VERSION "HNNBNNNYNNNNNNNNNNNNNNNNNNNNNNNNNNNNNNNNNN/4/%%%/4/'%**4NNN///"

NS_ :

BS_:

BU_: Frontradar Frontsensorik

BO_ 780 ACC_02: 8 Frontradar
 SG_ ACC_02_CRC : 0|8@1+ (1,0) [0|255] "" Vector__XXX
 SG_ ACC_02_BZ : 8|4@1+ (1,0) [0|15] "" Vector__XXX
 SG_ ACC_Wunschgeschw_02 : 12|10@1+ (0.32,0) [0|327.04] "Unit_KiloMeterPerHour" Vector__XXX
 SG_ ACC_Status_Prim_Anz : 22|2@1+ (1,0) [0|3] "" Vector__XXX
 SG_ ACC_Abstandsindex : 24|10@1+ (1,0) [1|1021] "" Vector__XXX
 SG_ ACC_Akustik_02 : 34|2@1+ (1,0) [0|3] "" Vector__XXX
 SG_ ACC_Warnung_Verkehrszeichen_1 : 36|1@1+ (1,0) [0|1] "" Vector__XXX
 SG_ ACC_Gesetzte_Zeitluecke : 37|3@1+ (1,0) [0|7] "" Vector__XXX
 SG_ ACC_Optischer_Fahrerhinweis : 40|1@1+ (1,0) [0|1] "" Vector__XXX
 SG_ ACC_Typ_Tachokranz : 41|1@1+ (1,0) [0|1] "" Vector__XXX
 SG_ ACC_Anzeige_Zeitluecke : 42|1@1+ (1,0) [0|1] "" Vector__XXX
 SG_ ACC_Tachokranz : 43|1@1+ (1,0) [0|1] "" Vector__XXX
 SG_ ACC_Display_Prio : 44|2@1+ (1,0) [0|3] "" Vector__XXX
 SG_ ACC_Relevantes_Objekt : 46|2@1+ (1,0) [0|3] "" Vector__XXX
 SG_ ACC_Texte_Primaeranz : 48|7@1+ (1,0) [0|127] "" Vector__XXX
 SG_ ACC_Wunschgeschw_erreicht : 55|1@1+ (1,0) [0|1] "" Vector__XXX
 SG_ ACC_Typ_Tachokranz_unten : 60|1@1+ (1,0) [0|1] "" Vector__XXX
 SG_ ACC_Status_Anzeige : 61|3@1+ (1,0) [0|7] "" Vector__XXX

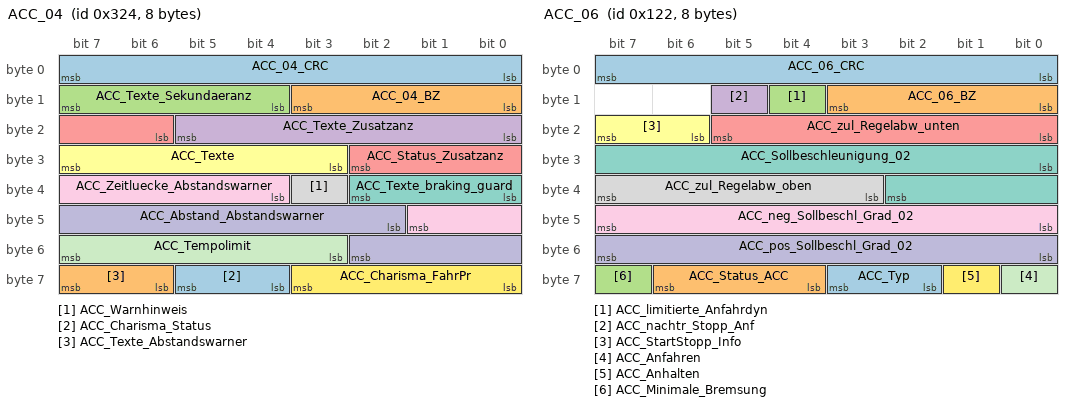
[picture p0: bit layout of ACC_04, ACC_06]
BO_ 804 ACC_04: 8 Frontradar
 SG_ ACC_04_CRC : 0|8@1+ (1,0) [0|255] "" Vector__XXX
 SG_ ACC_04_BZ : 8|4@1+ (1,0) [0|15] "" Vector__XXX
 SG_ ACC_Texte_Sekundaeranz : 12|4@1+ (1,0) [0|15] "" Vector__XXX
 SG_ ACC_Texte_Zusatzanz : 16|6@1+ (1,0) [0|63] "" Vector__XXX
 SG_ ACC_Status_Zusatzanz : 22|5@1+ (1,0) [0|31] "" Vector__XXX
 SG_ ACC_Texte : 27|5@1+ (1,0) [0|31] "" Vector__XXX
 SG_ ACC_Texte_braking_guard : 32|3@1+ (1,0) [0|7] "" Vector__XXX
 SG_ ACC_Warnhinweis : 35|1@1+ (1,0) [0|1] "" Vector__XXX
 SG_ ACC_Zeitluecke_Abstandswarner : 36|6@1+ (0.1,0) [0|6] "Unit_Secon" Vector__XXX
 SG_ ACC_Abstand_Abstandswarner : 42|9@1+ (1,0) [0|508] "" Vector__XXX
 SG_ ACC_Tempolimit : 51|5@1+ (1,0) [0|31] "" Vector__XXX
 SG_ ACC_Charisma_FahrPr : 56|4@1+ (1,0) [0|15] "" Vector__XXX
 SG_ ACC_Charisma_Status : 60|2@1+ (1,0) [0|3] "" Vector__XXX
 SG_ ACC_Texte_Abstandswarner : 62|2@1+ (1,0) [0|3] "" Vector__XXX

BO_ 290 ACC_06: 8 Frontradar
 SG_ ACC_06_CRC : 0|8@1+ (1,0) [0|255] "" Vector__XXX
 SG_ ACC_06_BZ : 8|4@1+ (1,0) [0|15] "" Vector__XXX
 SG_ ACC_limitierte_Anfahrdyn : 12|1@1+ (1,0) [0|1] "" Vector__XXX
 SG_ ACC_nachtr_Stopp_Anf : 13|1@1+ (1,0) [0|1] "" Vector__XXX
 SG_ ACC_zul_Regelabw_unten : 16|6@1+ (0.024,0) [0|1.512] "Unit_MeterPerSeconSquar" Vector__XXX
 SG_ ACC_StartStopp_Info : 22|2@1+ (1,0) [0|3] "" Vector__XXX
 SG_ ACC_Sollbeschleunigung_02 : 24|11@1+ (0.005,-7.22) [-7.22|3.005] "Unit_MeterPerSeconSquar" Vector__XXX
 SG_ ACC_zul_Regelabw_oben : 35|5@1+ (0.0625,0) [0|1.9375] "Unit_MeterPerSeconSquar" Vector__XXX
 SG_ ACC_neg_Sollbeschl_Grad_02 : 40|8@1+ (0.05,0) [0|12.75] "Unit_MeterPerCubicSecon" Vector__XXX
 SG_ ACC_pos_Sollbeschl_Grad_02 : 48|8@1+ (0.05,0) [0|12.75] "Unit_MeterPerCubicSecon" Vector__XXX
 SG_ ACC_Anfahren : 56|1@1+ (1,0) [0|1] "" Vector__XXX
 SG_ ACC_Anhalten : 57|1@1+ (1,0) [0|1] "" Vector__XXX
 SG_ ACC_Typ : 58|2@1+ (1,0) [0|3] "" Vector__XXX
 SG_ ACC_Status_ACC : 60|3@1+ (1,0) [0|7] "" Vector__XXX
 SG_ ACC_Minimale_Bremsung : 63|1@1+ (1,0) [0|1] "" Vector__XXX

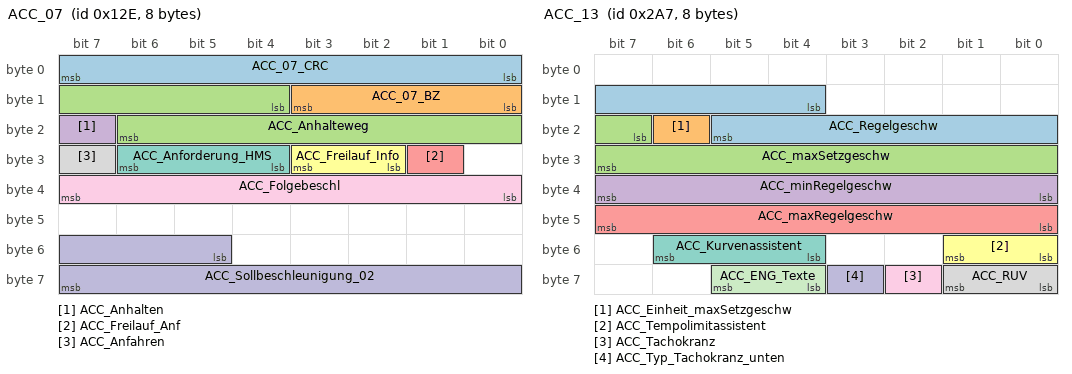
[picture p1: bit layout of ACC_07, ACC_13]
BO_ 302 ACC_07: 8 Frontradar
 SG_ ACC_07_CRC : 0|8@1+ (1,0) [0|255] "" Vector__XXX
 SG_ ACC_07_BZ : 8|4@1+ (1,0) [0|15] "" Vector__XXX
 SG_ ACC_Anhalteweg : 12|11@1+ (0.01,0) [0|20.45] "Unit_Meter" Vector__XXX
 SG_ ACC_Anhalten : 23|1@1+ (1,0) [0|1] "" Vector__XXX
 SG_ ACC_Freilauf_Anf : 25|1@1+ (1,0) [0|1] "" Vector__XXX
 SG_ ACC_Freilauf_Info : 26|2@1+ (1,0) [0|3] "" Vector__XXX
 SG_ ACC_Anforderung_HMS : 28|3@1+ (1,0) [0|7] "" Vector__XXX
 SG_ ACC_Anfahren : 31|1@1+ (1,0) [0|1] "" Vector__XXX
 SG_ ACC_Folgebeschl : 32|8@1+ (0.03,-4.6) [-4.6|2.99] "Unit_MeterPerSeconSquar" Vector__XXX
 SG_ ACC_Sollbeschleunigung_02 : 53|11@1+ (0.005,-7.22) [-7.22|3.005] "Unit_MeterPerSeconSquar" Vector__XXX

BO_ 279 ACC_10: 8 Frontradar
 SG_ ACC_10_CRC : 0|8@1+ (1,0) [0|255] ""  Frontsensorik
 SG_ ACC_10_BZ : 8|4@1+ (1,0) [0|15] ""  Frontsensorik
 SG_ AWV1_Anf_Prefill : 16|1@1+ (1,0) [0|1] "" Vector__XXX
 SG_ ANB_CM_Info : 17|1@1+ (1,0) [0|1] "" Vector__XXX
 SG_ AWV2_Freigabe : 18|1@1+ (1,0) [0|1] ""  Frontsensorik
 SG_ AWV1_HBA_Param : 19|2@1+ (1,0) [0|3] "" Vector__XXX
 SG_ AWV2_Ruckprofil : 21|3@1+ (1,0) [0|7] "" Vector__XXX
 SG_ AWV2_Priowarnung : 24|1@1+ (1,0) [0|1] "" Vector__XXX
 SG_ ANB_CM_Anforderung : 25|1@1+ (1,0) [0|1] "" Vector__XXX
 SG_ ANB_Info_Teilbremsung : 26|1@1+ (1,0) [0|1] "" Vector__XXX
 SG_ ANB_Notfallblinken : 27|1@1+ (1,0) [0|1] "" Vector__XXX
 SG_ ANB_Teilbremsung_Freigabe : 28|1@1+ (1,0) [0|1] ""  Frontsensorik
 SG_ ANB_Zielbrems_Teilbrems_Verz_Anf : 29|10@1+ (0.024,-20.016) [-20.016|4.536] "Unit_MeterPerSeconSquar" Vector__XXX
 SG_ ANB_Zielbremsung_Freigabe : 39|1@1+ (1,0) [0|1] ""  Frontsensorik
 SG_ AWV_Vorstufe : 40|1@1+ (1,0) [0|1] "" Vector__XXX
 SG_ AWV_Halten : 41|1@1+ (1,0) [0|1] "" Vector__XXX
 SG_ AWV_CityANB_Auspraegung : 42|1@1+ (1,0) [0|1] "" Vector__XXX
 SG_ PCF_Freigabe : 43|1@1+ (1,0) [0|1] "" Vector__XXX
 SG_ AWV1_ECD_Anlauf : 44|1@1+ (1,0) [0|1] "" Vector__XXX
 SG_ PCF_Time_to_collision : 56|8@1+ (0.01,0) [0|2.5] "Unit_Secon" Vector__XXX

BO_ 679 ACC_13: 8 Frontradar
 SG_ ACC_Regelgeschw : 12|10@1+ (0.32,0) [0|327.04] "Unit_KiloMeterPerHour" Vector__XXX
 SG_ ACC_Einheit_maxSetzgeschw : 22|1@1+ (1,0) [0|1] "" Vector__XXX
 SG_ ACC_maxSetzgeschw : 23|9@1+ (1,0) [0|510] "" Vector__XXX
 SG_ ACC_minRegelgeschw : 32|8@1+ (0.32,0) [0|81.28] "Unit_KiloMeterPerHour" Vector__XXX
 SG_ ACC_maxRegelgeschw : 40|8@1+ (0.32,0) [0|81.28] "Unit_KiloMeterPerHour" Vector__XXX
 SG_ ACC_Tempolimitassistent : 48|2@1+ (1,0) [0|3] "" Vector__XXX
 SG_ ACC_Kurvenassistent : 52|3@1+ (1,0) [0|7] "" Vector__XXX
 SG_ ACC_RUV : 56|2@1+ (1,0) [0|3] "" Vector__XXX
 SG_ ACC_Tachokranz : 58|1@1+ (1,0) [0|1] "" Vector__XXX
 SG_ ACC_Typ_Tachokranz_unten : 59|1@1+ (1,0) [0|1] "" Vector__XXX
 SG_ ACC_ENG_Texte : 60|2@1+ (1,0) [0|3] "" Vector__XXX

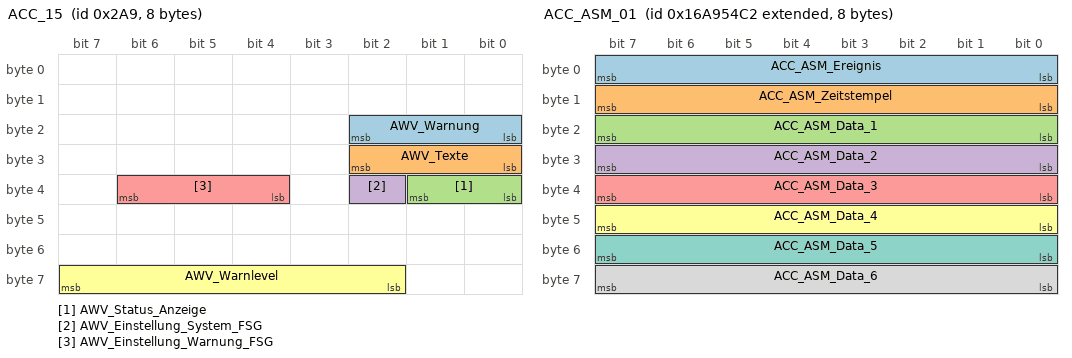
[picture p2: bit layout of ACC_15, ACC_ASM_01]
BO_ 681 ACC_15: 8 Frontradar
 SG_ AWV_Warnung : 16|3@1+ (1,0) [0|7] "" Vector__XXX
 SG_ AWV_Texte : 24|3@1+ (1,0) [0|7] "" Vector__XXX
 SG_ AWV_Status_Anzeige : 32|2@1+ (1,0) [0|3] "" Vector__XXX
 SG_ AWV_Einstellung_System_FSG : 34|1@1+ (1,0) [0|1] "" Vector__XXX
 SG_ AWV_Einstellung_Warnung_FSG : 36|3@1+ (1,0) [0|7] "" Vector__XXX
 SG_ AWV_Warnlevel : 58|6@1+ (1,0) [0|63] "" Vector__XXX

BO_ 2527679682 ACC_ASM_01: 8 Frontradar
 SG_ ACC_ASM_Ereignis : 0|8@1+ (1,0) [1|254] "" Vector__XXX
 SG_ ACC_ASM_Zeitstempel : 8|8@1+ (0.08,0) [0|20.32] "Unit_Secon" Vector__XXX
 SG_ ACC_ASM_Data_1 : 16|8@1+ (1,0) [0|255] "" Vector__XXX
 SG_ ACC_ASM_Data_2 : 24|8@1+ (1,0) [0|255] "" Vector__XXX
 SG_ ACC_ASM_Data_3 : 32|8@1+ (1,0) [0|255] "" Vector__XXX
 SG_ ACC_ASM_Data_4 : 40|8@1+ (1,0) [0|255] "" Vector__XXX
 SG_ ACC_ASM_Data_5 : 48|8@1+ (1,0) [0|255] "" Vector__XXX
 SG_ ACC_ASM_Data_6 : 56|8@1+ (1,0) [0|255] "" Vector__XXX

BO_ 64 Airbag_01: 8 Vector__XXX
 SG_ Airbag_01_CRC : 0|8@1+ (1,0) [0|255] ""  Frontradar,Frontsensorik
 SG_ Airbag_01_BZ : 8|4@1+ (1,0) [0|15] ""  Frontradar,Frontsensorik
 SG_ AB_RGS_Anst : 12|4@1+ (1,0) [0|15] "" Vector__XXX
 SG_ AB_Front_Crash : 16|1@1+ (1,0) [0|1] ""  Frontradar,Frontsensorik
 SG_ AB_Heck_Crash : 17|1@1+ (1,0) [0|1] ""  Frontsensorik
 SG_ AB_SF_Crash : 18|1@1+ (1,0) [0|1] ""  Frontsensorik
 SG_ AB_SB_Crash : 19|1@1+ (1,0) [0|1] ""  Frontsensorik
 SG_ AB_Rollover_Crash : 20|1@1+ (1,0) [0|1] ""  Frontsensorik
 SG_ AB_Crash_Int : 21|3@1+ (1,0) [0|7] ""  Frontradar
 SG_ AB_Lampe : 24|1@1+ (1,0) [0|1] "" Vector__XXX
 SG_ AB_Deaktiviert : 25|1@1+ (1,0) [0|1] "" Vector__XXX
 SG_ AB_VB_deaktiviert : 26|1@1+ (1,0) [0|1] "" Vector__XXX
 SG_ AB_Systemfehler : 27|1@1+ (1,0) [0|1] ""  Frontsensorik
 SG_ AB_Diagnose : 28|1@1+ (1,0) [0|1] "" Vector__XXX
 SG_ AB_Stellgliedtest : 29|1@1+ (1,0) [0|1] "" Vector__XXX
 SG_ AB_Erh_Auf_VB : 30|2@1+ (1,0) [0|3] "" Vector__XXX
 SG_ AB_Gurtwarn_VF : 32|1@1+ (1,0) [0|1] "" Vector__XXX
 SG_ AB_Gurtwarn_VB : 33|1@1+ (1,0) [0|1] "" Vector__XXX
 SG_ AB_Anzeige_Fussg : 34|2@1+ (1,0) [0|3] "" Vector__XXX
 SG_ AB_Texte_AKS : 36|2@1+ (1,0) [0|3] "" Vector__XXX
 SG_ AB_PAO_Leuchte_Anf : 38|1@1+ (1,0) [0|1] "" Vector__XXX
 SG_ AB_MKB_gueltig : 39|1@1+ (1,0) [0|1] "" Vector__XXX
 SG_ AB_MKB_Anforderung : 40|1@1+ (1,0) [0|1] "" Vector__XXX
 SG_ AB_Versorgungsspannung : 41|1@1+ (1,0) [0|1] "" Vector__XXX
 SG_ AB_Deaktivierung_HV : 42|3@1+ (1,0) [0|7] "" Vector__XXX
 SG_ AB_EDR_Trigger : 45|2@1+ (1,0) [0|3] "" Vector__XXX
 SG_ SC_Masterzeit_Offset : 53|2@1+ (5.08,0) [0|15.24] "Unit_Secon"  Frontradar
 SG_ SC_Masterzeit : 57|7@1+ (0.04,0) [0|5.04] "Unit_Secon"  Frontradar

BO_ 1312 Airbag_02: 8 Vector__XXX
 SG_ Airbag_02_CRC : 0|8@1+ (1,0) [0|255] ""  Frontradar
 SG_ Airbag_02_BZ : 8|4@1+ (1,0) [0|15] ""  Frontradar
 SG_ LoGeWa_Event_Kombiwarnung : 12|4@1+ (1,0) [0|15] "" Vector__XXX
 SG_ AB_Anforderung_eCall : 16|1@1+ (1,0) [0|1] "" Vector__XXX
 SG_ AB_Anprall_Seite_Beifahrer : 17|1@1+ (1,0) [0|1] "" Vector__XXX
 SG_ AB_Anprall_Rollover : 18|1@1+ (1,0) [0|1] "" Vector__XXX
 SG_ AB_Anprall_FGS : 19|1@1+ (1,0) [0|1] "" Vector__XXX
 SG_ AB_Anprall_Front_Beifahrer : 20|1@1+ (1,0) [0|1] "" Vector__XXX
 SG_ AB_Anprall_Front_Fahrer : 21|1@1+ (1,0) [0|1] "" Vector__XXX
 SG_ AB_Anprall_Heck_Beifahrer : 22|1@1+ (1,0) [0|1] "" Vector__XXX
 SG_ AB_Anprall_Heck_Fahrer : 23|1@1+ (1,0) [0|1] "" Vector__XXX
 SG_ AB_Wickelklappung_Reihe2_MI : 24|2@1+ (1,0) [0|3] "" Vector__XXX
 SG_ AB_Belegung_VB : 26|2@1+ (1,0) [0|3] "" Vector__XXX
 SG_ AB_Abschaltanf_SIH_BF : 28|1@1+ (1,0) [0|1] "" Vector__XXX
 SG_ AB_Anprall_Seite_Fahrer : 29|1@1+ (1,0) [0|1] "" Vector__XXX
 SG_ SC_PAO_Schriftzug_Anf : 30|2@1+ (1,0) [0|3] "" Vector__XXX
 SG_ SC_PAO_ON_Anf : 32|2@1+ (1,0) [0|3] "" Vector__XXX
 SG_ SC_PAO_OFF_Anf : 34|2@1+ (1,0) [0|3] "" Vector__XXX
 SG_ AB_Crashschwere : 36|3@1+ (1,0) [0|7] "" Vector__XXX
 SG_ AB_Anforderung_USM : 39|1@1+ (1,0) [0|1] "" Vector__XXX
 SG_ AB_Gurtschloss_FA : 40|2@1+ (1,0) [0|3] ""  Frontradar
 SG_ AB_Gurtschloss_BF : 42|2@1+ (1,0) [0|3] "" Vector__XXX
 SG_ AB_Gurtschloss_Reihe2_FA : 44|2@1+ (1,0) [0|3] "" Vector__XXX
 SG_ AB_Gurtschloss_Reihe2_MI : 46|2@1+ (1,0) [0|3] "" Vector__XXX
 SG_ AB_Gurtschloss_Reihe2_BF : 48|2@1+ (1,0) [0|3] "" Vector__XXX
 SG_ AB_Gurtschloss_Reihe3_FA : 50|2@1+ (1,0) [0|3] "" Vector__XXX
 SG_ AB_Gurtschloss_Reihe3_MI : 52|2@1+ (1,0) [0|3] "" Vector__XXX
 SG_ AB_Gurtschloss_Reihe3_BF : 54|2@1+ (1,0) [0|3] "" Vector__XXX
 SG_ AB_Sitzpos_Sens_FA : 56|2@1+ (1,0) [0|3] "" Vector__XXX
 SG_ AB_Sitzpos_Sens_BF : 58|2@1+ (1,0) [0|3] "" Vector__XXX
 SG_ AB_Wickelklappung_Reihe2_BF : 60|2@1+ (1,0) [0|3] "" Vector__XXX
 SG_ AB_Wickelklappung_Reihe2_FA : 62|2@1+ (1,0) [0|3] "" Vector__XXX

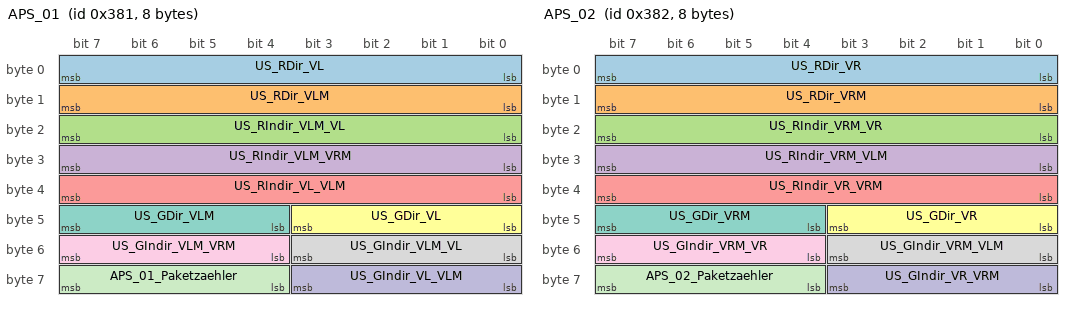
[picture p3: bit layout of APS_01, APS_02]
BO_ 897 APS_01: 8 Vector__XXX
 SG_ US_RDir_VL : 0|8@1+ (0.02,0) [0|5.1] "Unit_Meter"  Frontradar
 SG_ US_RDir_VLM : 8|8@1+ (0.02,0) [0|5.1] "Unit_Meter"  Frontradar
 SG_ US_RIndir_VLM_VL : 16|8@1+ (0.02,0) [0|5.1] "Unit_Meter"  Frontradar
 SG_ US_RIndir_VLM_VRM : 24|8@1+ (0.02,0) [0|5.1] "Unit_Meter"  Frontradar
 SG_ US_RIndir_VL_VLM : 32|8@1+ (0.02,0) [0|5.1] "Unit_Meter"  Frontradar
 SG_ US_GDir_VL : 40|4@1+ (0.066,0) [0|0.99] ""  Frontradar
 SG_ US_GDir_VLM : 44|4@1+ (0.066,0) [0|0.99] ""  Frontradar
 SG_ US_GIndir_VLM_VL : 48|4@1+ (0.066,0) [0|0.99] ""  Frontradar
 SG_ US_GIndir_VLM_VRM : 52|4@1+ (0.066,0) [0|0.99] ""  Frontradar
 SG_ US_GIndir_VL_VLM : 56|4@1+ (0.066,0) [0|0.99] ""  Frontradar
 SG_ APS_01_Paketzaehler : 60|4@1+ (1,0) [0|15] ""  Frontradar

BO_ 898 APS_02: 8 Vector__XXX
 SG_ US_RDir_VR : 0|8@1+ (0.02,0) [0|5.1] "Unit_Meter"  Frontradar
 SG_ US_RDir_VRM : 8|8@1+ (0.02,0) [0|5.1] "Unit_Meter"  Frontradar
 SG_ US_RIndir_VRM_VR : 16|8@1+ (0.02,0) [0|5.1] "Unit_Meter"  Frontradar
 SG_ US_RIndir_VRM_VLM : 24|8@1+ (0.02,0) [0|5.1] "Unit_Meter"  Frontradar
 SG_ US_RIndir_VR_VRM : 32|8@1+ (0.02,0) [0|5.1] "Unit_Meter"  Frontradar
 SG_ US_GDir_VR : 40|4@1+ (0.066,0) [0|0.99] ""  Frontradar
 SG_ US_GDir_VRM : 44|4@1+ (0.066,0) [0|0.99] ""  Frontradar
 SG_ US_GIndir_VRM_VLM : 48|4@1+ (0.066,0) [0|0.99] ""  Frontradar
 SG_ US_GIndir_VRM_VR : 52|4@1+ (0.066,0) [0|0.99] ""  Frontradar
 SG_ US_GIndir_VR_VRM : 56|4@1+ (0.066,0) [0|0.99] ""  Frontradar
 SG_ APS_02_Paketzaehler : 60|4@1+ (1,0) [0|15] ""  Frontradar

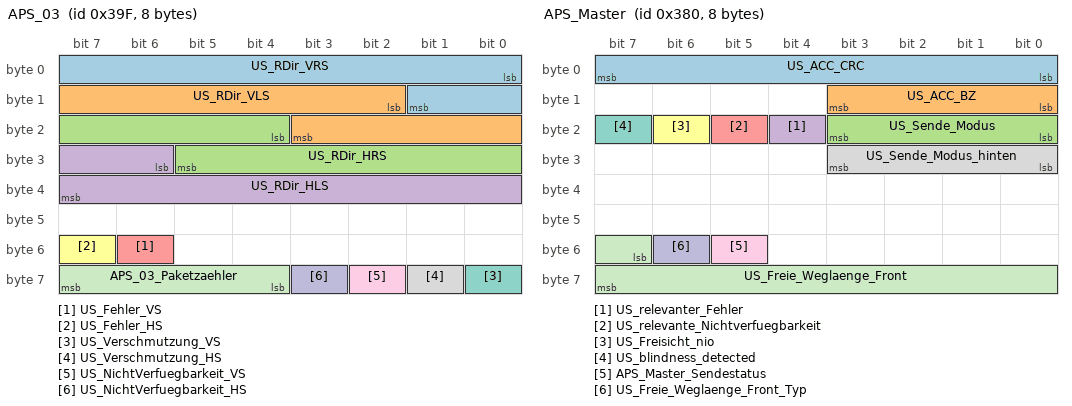
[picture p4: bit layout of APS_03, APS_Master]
BO_ 927 APS_03: 8 Vector__XXX
 SG_ US_RDir_VRS : 0|10@1+ (0.015625,0) [0|15.984375] "Unit_Meter" Vector__XXX
 SG_ US_RDir_VLS : 10|10@1+ (0.015625,0) [0|15.984375] "Unit_Meter" Vector__XXX
 SG_ US_RDir_HRS : 20|10@1+ (0.015625,0) [0|15.984375] "Unit_Meter" Vector__XXX
 SG_ US_RDir_HLS : 30|10@1+ (0.015625,0) [0|15.984375] "Unit_Meter" Vector__XXX
 SG_ US_Fehler_VS : 54|1@1+ (1,0) [0|1] "" Vector__XXX
 SG_ US_Fehler_HS : 55|1@1+ (1,0) [0|1] "" Vector__XXX
 SG_ US_Verschmutzung_VS : 56|1@1+ (1,0) [0|1] "" Vector__XXX
 SG_ US_Verschmutzung_HS : 57|1@1+ (1,0) [0|1] "" Vector__XXX
 SG_ US_NichtVerfuegbarkeit_VS : 58|1@1+ (1,0) [0|1] "" Vector__XXX
 SG_ US_NichtVerfuegbarkeit_HS : 59|1@1+ (1,0) [0|1] "" Vector__XXX
 SG_ APS_03_Paketzaehler : 60|4@1+ (1,0) [0|15] "" Vector__XXX

BO_ 896 APS_Master: 8 Vector__XXX
 SG_ US_ACC_CRC : 0|8@1+ (1,0) [0|255] "" Vector__XXX
 SG_ US_ACC_BZ : 8|4@1+ (1,0) [0|15] ""  Frontradar
 SG_ US_Sende_Modus : 16|4@1+ (1,0) [0|15] ""  Frontradar
 SG_ US_relevanter_Fehler : 20|1@1+ (1,0) [0|1] ""  Frontradar
 SG_ US_relevante_Nichtverfuegbarkeit : 21|1@1+ (1,0) [0|1] ""  Frontradar
 SG_ US_Freisicht_nio : 22|1@1+ (1,0) [0|1] ""  Frontradar
 SG_ US_blindness_detected : 23|1@1+ (1,0) [0|1] ""  Frontradar
 SG_ US_Sende_Modus_hinten : 24|4@1+ (1,0) [0|15] "" Vector__XXX
 SG_ APS_Master_Sendestatus : 53|1@1+ (1,0) [0|1] "" Vector__XXX
 SG_ US_Freie_Weglaenge_Front_Typ : 54|1@1+ (1,0) [0|1] ""  Frontradar
 SG_ US_Freie_Weglaenge_Front : 55|9@1+ (0.01,0) [0|5] "Unit_Meter"  Frontradar

BO_ 2536703232 BAP_ACC_ASG_01: 8 Vector__XXX
 SG_ BAP_ACC_ASG_01_Header : 0|8@1+ (1,0) [0|255] ""  Frontradar

BO_ 2536703248 BAP_ACC_FSG_01: 8 Frontradar
 SG_ BAP_ACC_FSG_01_Header : 0|8@1+ (1,0) [0|255] "" Vector__XXX

BO_ 2536708864 BAP_AWV_ASG_01: 8 Vector__XXX
 SG_ BAP_AWV_ASG_01_Header : 0|8@1+ (1,0) [0|255] ""  Frontradar

BO_ 2536708865 BAP_AWV_ASG_02: 8 Vector__XXX
 SG_ BAP_AWV_ASG_02_Header : 0|8@1+ (1,0) [0|255] ""  Frontradar

BO_ 2536708880 BAP_AWV_FSG_01: 8 Frontradar
 SG_ BAP_AWV_FSG_01_Header : 0|8@1+ (1,0) [0|255] "" Vector__XXX

BO_ 2536767264 BAP_Debug_Cmd: 8 Vector__XXX
 SG_ BAP_Debug_Cmd : 0|16@1+ (1,0) [0|65535] ""  Frontradar,Frontsensorik

BO_ 2536767280 BAP_Debug_Data: 8 Frontsensorik
 SG_ BAP_Debug_Data : 0|64@1+ (1,0) [0|1.84467440737096E+019] "" Vector__XXX

BO_ 2536708352 BAP_LDW_ASG_01: 8 Vector__XXX
 SG_ BAP_LDW_ASG_01_Header : 0|8@1+ (1,0) [0|255] ""  Frontsensorik

BO_ 2536708353 BAP_LDW_ASG_02: 8 Vector__XXX
 SG_ BAP_LDW_ASG_02_Header : 0|8@1+ (1,0) [0|255] ""  Frontsensorik

BO_ 2536708368 BAP_LDW_FSG_01: 8 Frontsensorik
 SG_ BAP_LDW_FSG_01_Header : 0|8@1+ (1,0) [0|255] "" Vector__XXX

BO_ 2536716800 BAP_PedAssist_ASG_01: 8 Vector__XXX
 SG_ BAP_PedAssist_ASG_01_Header : 0|8@1+ (1,0) [0|255] "" Vector__XXX

BO_ 2536716801 BAP_PedAssist_ASG_02: 8 Vector__XXX
 SG_ BAP_PedAssist_ASG_02_Data : 0|8@1+ (1,0) [0|255] "" Vector__XXX

BO_ 2536716816 BAP_PedAssist_FSG_01: 8 Vector__XXX
 SG_ BAP_PedAssist_FSG_01_Header : 0|8@1+ (1,0) [0|255] "" Vector__XXX

BO_ 2536703744 BAP_RDK_ASG_01: 8 Vector__XXX
 SG_ BAP_RDK_ASG_01_Header : 0|8@1+ (1,0) [0|255] "" Vector__XXX

BO_ 2536703745 BAP_RDK_ASG_02: 8 Vector__XXX
 SG_ BAP_RDK_ASG_02_Header : 0|8@1+ (1,0) [0|255] "" Vector__XXX

BO_ 2536703760 BAP_RDK_FSG_01: 8 Vector__XXX
 SG_ BAP_RDK_FSG_01_Header : 0|8@1+ (1,0) [0|255] "" Vector__XXX

BO_ 2536708608 BAP_SWA_ASG_01: 8 Vector__XXX
 SG_ BAP_SWA_ASG_01_Header : 0|8@1+ (1,0) [0|255] "" Vector__XXX

BO_ 2536708609 BAP_SWA_ASG_02: 8 Vector__XXX
 SG_ BAP_SWA_ASG_02_Header : 0|8@1+ (1,0) [0|255] "" Vector__XXX

BO_ 2536708624 BAP_SWA_FSG_01: 8 Vector__XXX
 SG_ BAP_SWA_FSG_01_Header : 0|8@1+ (1,0) [0|255] "" Vector__XXX

BO_ 2536710400 BAP_VZA_ASG_01: 8 Vector__XXX
 SG_ BAP_VZA_ASG_01_Header : 0|8@1+ (1,0) [0|255] ""  Frontsensorik

BO_ 2536710401 BAP_VZA_ASG_02: 8 Vector__XXX
 SG_ BAP_VZA_ASG_02_Header : 0|8@1+ (1,0) [0|255] ""  Frontsensorik

BO_ 2536710402 BAP_VZA_ASG_03: 8 Vector__XXX
 SG_ BAP_VZA_ASG_03_Header : 0|8@1+ (1,0) [0|255] "" Vector__XXX

BO_ 2536710416 BAP_VZA_FSG_01: 8 Frontsensorik
 SG_ BAP_VZA_FSG_01_Header : 0|8@1+ (1,0) [0|255] "" Vector__XXX

BO_ 870 Blinkmodi_02: 8 Vector__XXX
 SG_ BM_ZV_auf : 12|1@1+ (1,0) [0|1] "" Vector__XXX
 SG_ BM_ZV_zu : 13|1@1+ (1,0) [0|1] "" Vector__XXX
 SG_ BM_DWA_ein : 14|1@1+ (1,0) [0|1] "" Vector__XXX
 SG_ BM_DWA_Alarm : 15|1@1+ (1,0) [0|1] "" Vector__XXX
 SG_ BM_Crash : 16|1@1+ (1,0) [0|1] "" Vector__XXX
 SG_ BM_Panik : 17|1@1+ (1,0) [0|1] "" Vector__XXX
 SG_ BM_Not_Bremsung : 18|1@1+ (1,0) [0|1] "" Vector__XXX
 SG_ BM_GDO : 19|1@1+ (1,0) [0|1] "" Vector__XXX
 SG_ BM_Warnblinken : 20|1@1+ (1,0) [0|1] ""  Frontradar
 SG_ BM_Taxi_Notalarm : 21|1@1+ (1,0) [0|1] "" Vector__XXX
 SG_ BM_Telematik : 22|1@1+ (1,0) [0|1] "" Vector__XXX
 SG_ BM_links : 23|1@1+ (1,0) [0|1] ""  Frontsensorik
 SG_ BM_rechts : 24|1@1+ (1,0) [0|1] ""  Frontsensorik
 SG_ Blinken_li_Fzg_Takt : 25|1@1+ (1,0) [0|1] "" Vector__XXX
 SG_ Blinken_re_Fzg_Takt : 26|1@1+ (1,0) [0|1] "" Vector__XXX
 SG_ Blinken_li_Kombi_Takt : 27|1@1+ (1,0) [0|1] "" Vector__XXX
 SG_ Blinken_re_Kombi_Takt : 28|1@1+ (1,0) [0|1] "" Vector__XXX
 SG_ BM_NBA_n_codiert_n_aktiv : 29|1@1+ (1,0) [0|1] "" Vector__XXX
 SG_ BM_NBA_Status : 30|2@1+ (1,0) [0|3] "" Vector__XXX
 SG_ BM_WBT_Beleuchtung : 32|1@1+ (1,0) [0|1] "" Vector__XXX
 SG_ BM_HD_Oeffnung_angelernt : 33|1@1+ (1,0) [0|1] "" Vector__XXX
 SG_ BM_Autobahn : 34|1@1+ (1,0) [0|1] "" Vector__XXX
 SG_ BM_Rollenmodus_Blinken : 35|1@1+ (1,0) [0|1] "" Vector__XXX
 SG_ BM_Recas : 36|1@1+ (1,0) [0|1] "" Vector__XXX
 SG_ BM_Wischblinken : 37|1@1+ (1,0) [0|1] "" Vector__XXX
 SG_ BM_Telematik_Abbruchgrund : 38|6@1+ (1,0) [0|63] "" Vector__XXX

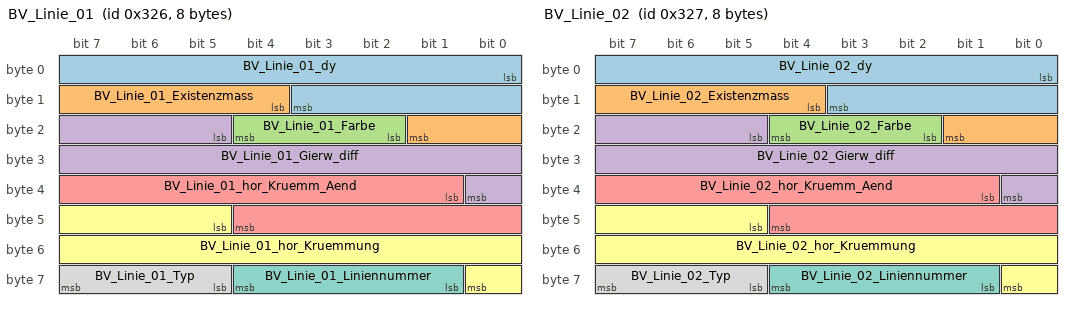
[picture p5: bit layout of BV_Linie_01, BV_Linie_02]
BO_ 806 BV_Linie_01: 8 Frontsensorik
 SG_ BV_Linie_01_dy : 0|12@1+ (0.00390625,-8) [-8|7.99609375] "Unit_Meter" Vector__XXX
 SG_ BV_Linie_01_Existenzmass : 12|6@1+ (0.015625,0) [0|0.984375] "Unit_Meter" Vector__XXX
 SG_ BV_Linie_01_Farbe : 18|3@1+ (1,0) [0|7] "" Vector__XXX
 SG_ BV_Linie_01_Gierw_diff : 21|12@1+ (0.00048828125,-1) [-1|0.99951171875] "Unit_Radia" Vector__XXX
 SG_ BV_Linie_01_hor_Kruemm_Aend : 33|12@1+ (1,-2047) [-2047|2048] "" Vector__XXX
 SG_ BV_Linie_01_hor_Kruemmung : 45|12@1+ (1,-2047) [-2047|2048] "" Vector__XXX
 SG_ BV_Linie_01_Liniennummer : 57|4@1+ (1,0) [1|15] "" Vector__XXX
 SG_ BV_Linie_01_Typ : 61|3@1+ (1,0) [0|7] "" Vector__XXX

BO_ 807 BV_Linie_02: 8 Frontsensorik
 SG_ BV_Linie_02_dy : 0|12@1+ (0.00390625,-8) [-8|7.99609375] "Unit_Meter" Vector__XXX
 SG_ BV_Linie_02_Existenzmass : 12|6@1+ (0.015625,0) [0|0.984375] "Unit_Meter" Vector__XXX
 SG_ BV_Linie_02_Farbe : 18|3@1+ (1,0) [0|7] "" Vector__XXX
 SG_ BV_Linie_02_Gierw_diff : 21|12@1+ (0.00048828125,-1) [-1|0.99951171875] "Unit_Radia" Vector__XXX
 SG_ BV_Linie_02_hor_Kruemm_Aend : 33|12@1+ (1,-2047) [-2047|2048] "" Vector__XXX
 SG_ BV_Linie_02_hor_Kruemmung : 45|12@1+ (1,-2047) [-2047|2048] "" Vector__XXX
 SG_ BV_Linie_02_Liniennummer : 57|4@1+ (1,0) [1|15] "" Vector__XXX
 SG_ BV_Linie_02_Typ : 61|3@1+ (1,0) [0|7] "" Vector__XXX

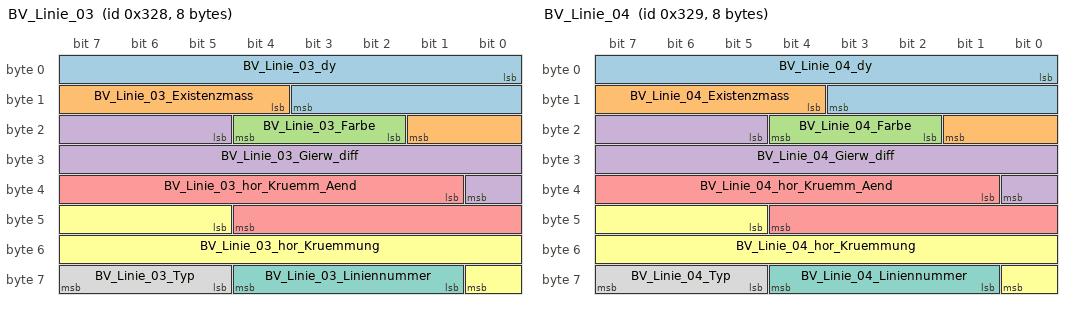
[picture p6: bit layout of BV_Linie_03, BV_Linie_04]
BO_ 808 BV_Linie_03: 8 Frontsensorik
 SG_ BV_Linie_03_dy : 0|12@1+ (0.00390625,-8) [-8|7.99609375] "Unit_Meter" Vector__XXX
 SG_ BV_Linie_03_Existenzmass : 12|6@1+ (0.015625,0) [0|0.984375] "Unit_Meter" Vector__XXX
 SG_ BV_Linie_03_Farbe : 18|3@1+ (1,0) [0|7] "" Vector__XXX
 SG_ BV_Linie_03_Gierw_diff : 21|12@1+ (0.00048828125,-1) [-1|0.99951171875] "Unit_Radia" Vector__XXX
 SG_ BV_Linie_03_hor_Kruemm_Aend : 33|12@1+ (1,-2047) [-2047|2048] "" Vector__XXX
 SG_ BV_Linie_03_hor_Kruemmung : 45|12@1+ (1,-2047) [-2047|2048] "" Vector__XXX
 SG_ BV_Linie_03_Liniennummer : 57|4@1+ (1,0) [1|15] "" Vector__XXX
 SG_ BV_Linie_03_Typ : 61|3@1+ (1,0) [0|7] "" Vector__XXX

BO_ 809 BV_Linie_04: 8 Frontsensorik
 SG_ BV_Linie_04_dy : 0|12@1+ (0.00390625,-8) [-8|7.99609375] "Unit_Meter" Vector__XXX
 SG_ BV_Linie_04_Existenzmass : 12|6@1+ (0.015625,0) [0|0.984375] "Unit_Meter" Vector__XXX
 SG_ BV_Linie_04_Farbe : 18|3@1+ (1,0) [0|7] "" Vector__XXX
 SG_ BV_Linie_04_Gierw_diff : 21|12@1+ (0.00048828125,-1) [-1|0.99951171875] "Unit_Radia" Vector__XXX
 SG_ BV_Linie_04_hor_Kruemm_Aend : 33|12@1+ (1,-2047) [-2047|2048] "" Vector__XXX
 SG_ BV_Linie_04_hor_Kruemmung : 45|12@1+ (1,-2047) [-2047|2048] "" Vector__XXX
 SG_ BV_Linie_04_Liniennummer : 57|4@1+ (1,0) [1|15] "" Vector__XXX
 SG_ BV_Linie_04_Typ : 61|3@1+ (1,0) [0|7] "" Vector__XXX

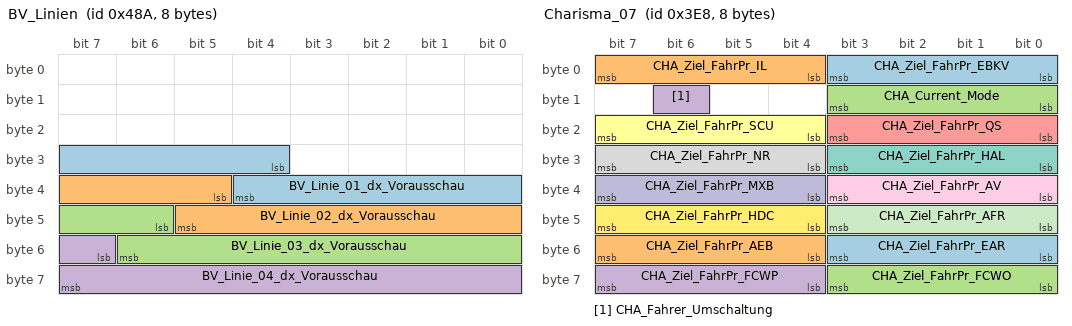
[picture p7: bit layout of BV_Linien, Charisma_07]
BO_ 1162 BV_Linien: 8 Frontsensorik
 SG_ BV_Linie_01_dx_Vorausschau : 28|9@1+ (0.25,0) [0|127.75] "Unit_Meter" Vector__XXX
 SG_ BV_Linie_02_dx_Vorausschau : 37|9@1+ (0.25,0) [0|127.75] "Unit_Meter" Vector__XXX
 SG_ BV_Linie_03_dx_Vorausschau : 46|9@1+ (0.25,0) [0|127.75] "Unit_Meter" Vector__XXX
 SG_ BV_Linie_04_dx_Vorausschau : 55|9@1+ (0.25,0) [0|127.75] "Unit_Meter" Vector__XXX

BO_ 2617162240 CCP_ACC_CRO_01: 8 Vector__XXX
 SG_ CCP_ACC_CRO_01_Data : 0|64@1+ (1,0) [0|1] ""  Frontradar

BO_ 2617162241 CCP_ACC_DTO_01: 8 Frontradar
 SG_ CCP_ACC_DTO_01_Data : 0|64@1+ (1,0) [0|1] "" Vector__XXX

BO_ 901 Charisma_01: 8 Vector__XXX
 SG_ CHA_Ziel_FahrPr_AGA : 0|4@1+ (1,0) [0|15] "" Vector__XXX
 SG_ CHA_Ziel_FahrPr_ESP : 4|4@1+ (1,0) [0|15] "" Vector__XXX
 SG_ CHA_Ziel_FahrPr_Freilauf : 8|4@1+ (1,0) [0|15] "" Vector__XXX
 SG_ CHA_Fahrer_Umschaltung : 14|1@1+ (1,0) [0|1] ""  Frontradar
 SG_ CHA_Fahrer_Umschaltung_BMA : 15|1@1+ (1,0) [0|1] "" Vector__XXX
 SG_ CHA_Ziel_FahrPr_MO : 16|4@1+ (1,0) [0|15] "" Vector__XXX
 SG_ CHA_Ziel_FahrPr_GE : 20|4@1+ (1,0) [0|15] "" Vector__XXX
 SG_ CHA_Ziel_FahrPr_ALR : 24|4@1+ (1,0) [0|15] "" Vector__XXX
 SG_ CHA_Ziel_FahrPr_MO_BZS : 28|4@1+ (1,0) [0|15] "" Vector__XXX
 SG_ CHA_Ziel_FahrPr_DR : 32|4@1+ (1,0) [0|15] "" Vector__XXX
 SG_ CHA_Ziel_FahrPr_VAQ : 36|4@1+ (1,0) [0|15] "" Vector__XXX
 SG_ CHA_Ziel_FahrPr_AFS : 40|4@1+ (1,0) [0|15] "" Vector__XXX
 SG_ CHA_Ziel_FahrPr_RGS : 44|4@1+ (1,0) [0|15] "" Vector__XXX
 SG_ CHA_Ziel_FahrPr_EPS : 48|4@1+ (1,0) [0|15] "" Vector__XXX
 SG_ CHA_Ziel_FahrPr_ACC : 52|4@1+ (1,0) [0|15] ""  Frontradar
 SG_ CHA_Ziel_FahrPr_SAK : 56|4@1+ (1,0) [0|15] "" Vector__XXX
 SG_ CHA_Ziel_FahrPr_MO_StSt : 60|4@1+ (1,0) [0|15] "" Vector__XXX

BO_ 1000 Charisma_07: 8 Vector__XXX
 SG_ CHA_Ziel_FahrPr_EBKV : 0|4@1+ (1,0) [0|15] "" Vector__XXX
 SG_ CHA_Ziel_FahrPr_IL : 4|4@1+ (1,0) [0|15] "" Vector__XXX
 SG_ CHA_Current_Mode : 8|4@1+ (1,0) [0|15] ""  Frontradar
 SG_ CHA_Fahrer_Umschaltung : 14|1@1+ (1,0) [0|1] "" Vector__XXX
 SG_ CHA_Ziel_FahrPr_QS : 16|4@1+ (1,0) [0|15] "" Vector__XXX
 SG_ CHA_Ziel_FahrPr_SCU : 20|4@1+ (1,0) [0|15] "" Vector__XXX
 SG_ CHA_Ziel_FahrPr_HAL : 24|4@1+ (1,0) [0|15] "" Vector__XXX
 SG_ CHA_Ziel_FahrPr_NR : 28|4@1+ (1,0) [0|15] "" Vector__XXX
 SG_ CHA_Ziel_FahrPr_AV : 32|4@1+ (1,0) [0|15] "" Vector__XXX
 SG_ CHA_Ziel_FahrPr_MXB : 36|4@1+ (1,0) [0|15] "" Vector__XXX
 SG_ CHA_Ziel_FahrPr_AFR : 40|4@1+ (1,0) [0|15] "" Vector__XXX
 SG_ CHA_Ziel_FahrPr_HDC : 44|4@1+ (1,0) [0|15] "" Vector__XXX
 SG_ CHA_Ziel_FahrPr_EAR : 48|4@1+ (1,0) [0|15] "" Vector__XXX
 SG_ CHA_Ziel_FahrPr_AEB : 52|4@1+ (1,0) [0|15] "" Vector__XXX
 SG_ CHA_Ziel_FahrPr_FCWO : 56|4@1+ (1,0) [0|15] "" Vector__XXX
 SG_ CHA_Ziel_FahrPr_FCWP : 60|4@1+ (1,0) [0|15] "" Vector__XXX

BO_ 2549880330 DIA_LED_LM_L_Req: 8 Vector__XXX
 SG_ DIA_LED_LM_L_Req_Data : 0|64@1+ (1,0) [0|1.84467440737096E+019] "" Vector__XXX

BO_ 2550011402 DIA_LED_LM_L_Resp: 8 Vector__XXX
 SG_ DIA_LED_LM_L_Resp_Data : 0|64@1+ (1,0) [0|1.84467440737096E+019] "" Vector__XXX

BO_ 2549880331 DIA_LED_LM_R_Req: 8 Vector__XXX
 SG_ DIA_LED_LM_R_Req_Data : 0|64@1+ (1,0) [0|1.84467440737096E+019] "" Vector__XXX

BO_ 2550011403 DIA_LED_LM_R_Resp: 8 Vector__XXX
 SG_ DIA_LED_LM_R_Resp_Data : 0|64@1+ (1,0) [0|1.84467440737096E+019] "" Vector__XXX

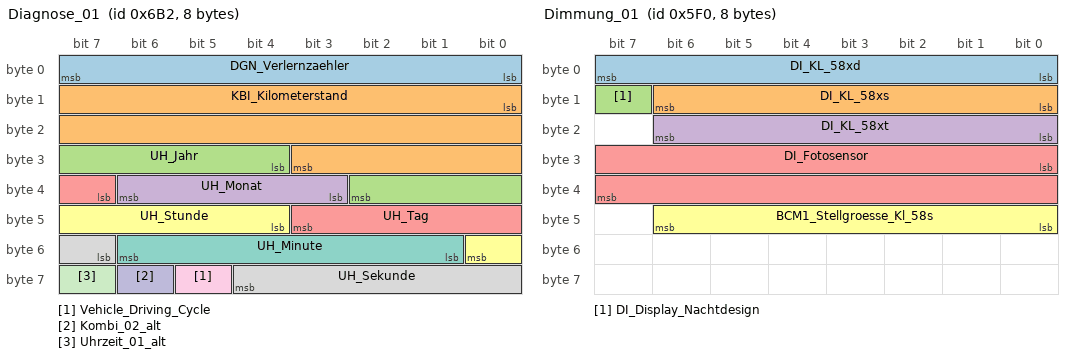
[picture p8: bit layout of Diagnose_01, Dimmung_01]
BO_ 1714 Diagnose_01: 8 Vector__XXX
 SG_ DGN_Verlernzaehler : 0|8@1+ (1,0) [0|254] ""  Frontradar,Frontsensorik
 SG_ KBI_Kilometerstand : 8|20@1+ (1,0) [0|1048573] "Unit_KiloMeter"  Frontradar,Frontsensorik
 SG_ UH_Jahr : 28|7@1+ (1,2000) [2000|2127] "Unit_Year"  Frontradar,Frontsensorik
 SG_ UH_Monat : 35|4@1+ (1,0) [1|12] "Unit_Month"  Frontradar,Frontsensorik
 SG_ UH_Tag : 39|5@1+ (1,0) [1|31] "Unit_Day"  Frontradar,Frontsensorik
 SG_ UH_Stunde : 44|5@1+ (1,0) [0|23] "Unit_Hours"  Frontradar,Frontsensorik
 SG_ UH_Minute : 49|6@1+ (1,0) [0|59] "Unit_Minut"  Frontradar,Frontsensorik
 SG_ UH_Sekunde : 55|6@1+ (1,0) [0|59] "Unit_Secon"  Frontradar,Frontsensorik
 SG_ Vehicle_Driving_Cycle : 61|1@1+ (1,0) [0|1] "" Vector__XXX
 SG_ Kombi_02_alt : 62|1@1+ (1,0) [0|1] ""  Frontradar,Frontsensorik
 SG_ Uhrzeit_01_alt : 63|1@1+ (1,0) [0|1] ""  Frontradar,Frontsensorik

BO_ 1520 Dimmung_01: 8 Vector__XXX
 SG_ DI_KL_58xd : 0|8@1+ (1,0) [0|253] "" Vector__XXX
 SG_ DI_KL_58xs : 8|7@1+ (1,0) [0|100] "Unit_PerCent" Vector__XXX
 SG_ DI_Display_Nachtdesign : 15|1@1+ (1,0) [0|1] "" Vector__XXX
 SG_ DI_KL_58xt : 16|7@1+ (1,0) [0|100] "Unit_PerCent" Vector__XXX
 SG_ DI_Fotosensor : 24|16@1+ (1,0) [0|65535] "" Vector__XXX
 SG_ BCM1_Stellgroesse_Kl_58s : 40|7@1+ (1,0) [0|100] "" Vector__XXX

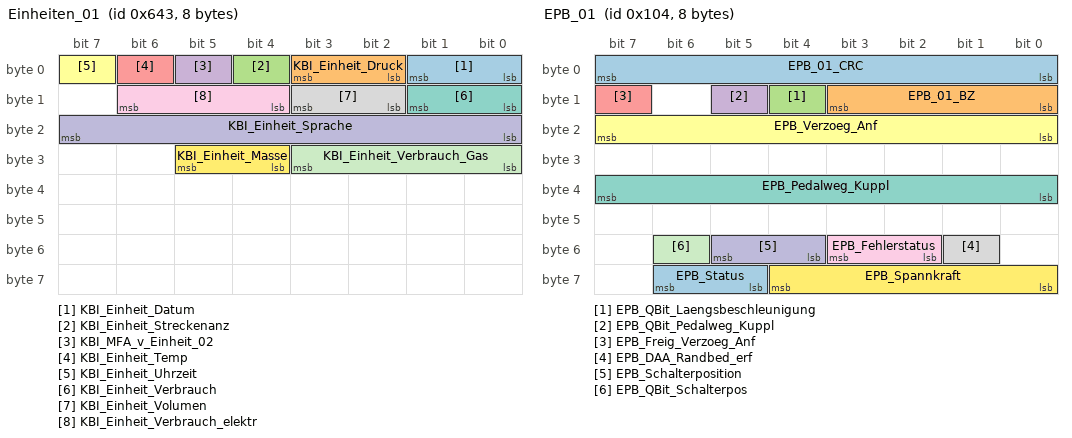
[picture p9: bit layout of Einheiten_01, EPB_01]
BO_ 1603 Einheiten_01: 8 Vector__XXX
 SG_ KBI_Einheit_Datum : 0|2@1+ (1,0) [0|3] "" Vector__XXX
 SG_ KBI_Einheit_Druck : 2|2@1+ (1,0) [0|3] "" Vector__XXX
 SG_ KBI_Einheit_Streckenanz : 4|1@1+ (1,0) [0|1] "" Vector__XXX
 SG_ KBI_MFA_v_Einheit_02 : 5|1@1+ (1,0) [0|1] "" Vector__XXX
 SG_ KBI_Einheit_Temp : 6|1@1+ (1,0) [0|1] "" Vector__XXX
 SG_ KBI_Einheit_Uhrzeit : 7|1@1+ (1,0) [0|1] "" Vector__XXX
 SG_ KBI_Einheit_Verbrauch : 8|2@1+ (1,0) [0|3] "" Vector__XXX
 SG_ KBI_Einheit_Volumen : 10|2@1+ (1,0) [0|3] "" Vector__XXX
 SG_ KBI_Einheit_Verbrauch_elektr : 12|3@1+ (1,0) [0|7] "" Vector__XXX
 SG_ KBI_Einheit_Sprache : 16|8@1+ (1,0) [0|255] "" Vector__XXX
 SG_ KBI_Einheit_Verbrauch_Gas : 24|4@1+ (1,0) [0|15] "" Vector__XXX
 SG_ KBI_Einheit_Masse : 28|2@1+ (1,0) [0|3] "" Vector__XXX

BO_ 260 EPB_01: 8 Vector__XXX
 SG_ EPB_01_CRC : 0|8@1+ (1,0) [0|255] ""  Frontradar
 SG_ EPB_01_BZ : 8|4@1+ (1,0) [0|15] ""  Frontradar
 SG_ EPB_QBit_Laengsbeschleunigung : 12|1@1+ (1,0) [0|1] "" Vector__XXX
 SG_ EPB_QBit_Pedalweg_Kuppl : 13|1@1+ (1,0) [0|1] "" Vector__XXX
 SG_ EPB_Freig_Verzoeg_Anf : 15|1@1+ (1,0) [0|1] ""  Frontradar
 SG_ EPB_Verzoeg_Anf : 16|8@1+ (0.048,-7.968) [-7.968|4.224] "Unit_MeterPerSeconSquar" Vector__XXX
 SG_ EPB_Pedalweg_Kuppl : 32|8@1+ (0.4,0) [8|92] "Unit_PerCent" Vector__XXX
 SG_ EPB_DAA_Randbed_erf : 49|1@1+ (1,0) [0|1] "" Vector__XXX
 SG_ EPB_Fehlerstatus : 50|2@1+ (1,0) [0|3] ""  Frontradar
 SG_ EPB_Schalterposition : 52|2@1+ (1,0) [0|3] ""  Frontradar
 SG_ EPB_QBit_Schalterpos : 54|1@1+ (1,0) [0|1] ""  Frontradar
 SG_ EPB_Spannkraft : 56|5@1+ (1,0) [0|29] "Unit_KiloNewto"  Frontradar
 SG_ EPB_Status : 61|2@1+ (1,0) [0|3] ""  Frontradar

BO_ 257 ESP_02: 8 Vector__XXX
 SG_ ESP_02_CRC : 0|8@1+ (1,0) [0|255] ""  Frontradar,Frontsensorik
 SG_ ESP_02_BZ : 8|4@1+ (1,0) [0|15] ""  Frontradar,Frontsensorik
 SG_ ESP_QBit_Gierrate : 12|1@1+ (1,0) [0|1] ""  Frontradar,Frontsensorik
 SG_ ESP_QBit_Laengsbeschl : 13|1@1+ (1,0) [0|1] ""  Frontradar,Frontsensorik
 SG_ ESP_QBit_Querb : 14|1@1+ (1,0) [0|1] ""  Frontradar,Frontsensorik
 SG_ ESP_Stillstandsflag : 15|1@1+ (1,0) [0|1] "" Vector__XXX
 SG_ ESP_Querbeschleunigung : 16|8@1+ (0.01,-1.27) [-1.27|1.27] "Unit_ForceOfGravi"  Frontradar,Frontsensorik
 SG_ ESP_Laengsbeschl : 24|10@1+ (0.03125,-16) [-16|15.90625] "Unit_MeterPerSeconSquar"  Frontradar,Frontsensorik
 SG_ ESC_Motorstartverzoegerung : 34|1@1+ (1,0) [0|1] "" Vector__XXX
 SG_ ESC_SeitenwindAssistent_Eingriff : 35|1@1+ (1,0) [0|1] "" Vector__XXX
 SG_ ESP_Anschleppstart_Freigabe : 36|2@1+ (1,0) [0|3] "" Vector__XXX
 SG_ ESP_QBit_Anf_Vert_Wank : 39|1@1+ (1,0) [0|1] "" Vector__XXX
 SG_ ESP_Gierrate : 40|14@1+ (0.01,0) [0|163.82] "Unit_DegreOfArcPerSecon"  Frontradar,Frontsensorik
 SG_ ESP_VZ_Gierrate : 54|1@1+ (1,0) [0|1] ""  Frontradar,Frontsensorik
 SG_ ESP_Notbremsanzeige : 55|1@1+ (1,0) [0|1] "" Vector__XXX
 SG_ ESP_SpannungsAnf : 56|1@1+ (1,0) [0|1] "" Vector__XXX
 SG_ ESP_PLA_Abbruch : 57|3@1+ (1,0) [0|7] "" Vector__XXX
 SG_ ESP_Status_ESP_PLA : 60|4@1+ (1,0) [0|15] "" Vector__XXX

BO_TX_BU_ 2536767280 : Frontradar,Frontsensorik;

CM_ "MQB_ECAN_V7.14F Generated by BUSNET NG Produktiv 9.3.5";
CM_ BU_ Frontradar "Frontradar (mit Funktion Adaptive Cruise Control) ab MQB B inkl. MQB A0";
CM_ BU_ Frontsensorik "Frontkamera MQB A";
CM_ BO_ 780 "ab MQB mit CRC-8, ACC_Wunschgeschw_02 und ACC_Akustik_02";
CM_ SG_ 780 ACC_02_CRC "Für MLB:
'Berechnung siehe Lastenheft 'Kommunikationsabsicherung für FlexRay und CAN''

Ab MQB und MLBevo:
'Berechnung siehe Lastenheft 'End-to-End Kommunikationsabsicherung''

Endwerte siehe Begleitdokument 'S-PDU Kennungsfolgen'";
CM_ SG_ 780 ACC_Wunschgeschw_02 "Zur Anzeige der Wunschgeschwindigkeit im Kombiinstrument
";
CM_ SG_ 780 ACC_Status_Prim_Anz "Ansteuerung einer primären Statusanzeige für ACC/GRA in verschiedenen Farben";
CM_ SG_ 780 ACC_Abstandsindex "Für die optionale Anzeige einer einheitenlosen Abstandsreserve oder einer gemessenen Zeitlücke in der Zusatzanzeige
";
CM_ SG_ 780 ACC_Akustik_02 "Ansteuerung der zugehörigen Akustik im Kombiinstrument, solange die entsprechende Bitkombination gesetzt ist.";
CM_ SG_ 780 ACC_Warnung_Verkehrszeichen_1 "PACC: Zeigt bei Überschreitung der aktuellen Höchstgeschwindigkeit um 10% einen Hinweis im Kombi an";
CM_ SG_ 780 ACC_Gesetzte_Zeitluecke "Nur in ADR/ACC-Fahrzeugen: ACC Zusatzanzeige: 0 = aus / ungleich 0 = ein; angezeigte ADR-Zeitlücke wird auf 3 Bits begrenzt";
CM_ SG_ 780 ACC_Optischer_Fahrerhinweis "Fahrerübernahmeaufforderung; z.B. bei Erreichen der Systemgrenzen oder beim Auftreten von Fehlern in kritischen Situationen (VW).
";
CM_ SG_ 780 ACC_Typ_Tachokranz "Abhängig von der ACC-Codierung 'Land' ist der Bereich der einstellbaren Wunschgeschwindigkeit und damit die Länge des schwach beleuchteten Tachokranzes begrenzt. Das Bit steuert im Kombi die Ausleuchtung des Tachokranzes an.
Der auszuleuchtende Bereich i";
CM_ SG_ 780 ACC_Anzeige_Zeitluecke "Anforderung zur Umschaltung zwischen dem Anzeigemodus 'Keine Änderung Zeitlücke' und 'Änderung Zeitlücke' (z.B. Pfeildarstellung in Zusatzanzeige)
";
CM_ SG_ 780 ACC_Tachokranz "Für zusätzliche Status- und Einstellbereichsanzeige im Tacho. (z.B. Tachokranz)
";
CM_ SG_ 780 ACC_Display_Prio "Zur situationsabhängigen Prioritätensteuerung von ACC Anzeigen im nicht permanenten Anzeigebereich. Im Kombiinstrument ist jeder Prioritätsstufe eine adäquate Prio-Definition zugeordnet.

";
CM_ SG_ 780 ACC_Relevantes_Objekt "Ansteuerung einer primären Anzeige 'Relevantes Objekt' für ACC in verschiedenen Farben.
";
CM_ SG_ 780 ACC_Texte_Primaeranz "Weitere Textdefinitionen im DBC- bzw. FIBEX-File!";
CM_ SG_ 780 ACC_Wunschgeschw_erreicht "Signal for Bentley BY83x: ACC_set_speed_achieved

Mit diesem Signal wird im Kombi eine Anzeige angesteuert, wenn das Fahrzeug die gesetzte Wunschgeschwindigkeit erreicht hat.

This signal illuminates the set speed icon a different colour  in the Kombi";
CM_ SG_ 780 ACC_Typ_Tachokranz_unten "Mit diesem Bit wird die LED unterhalb der minimalen Setzgeschwindigkeit an/ausgeschaltet.
";
CM_ SG_ 780 ACC_Status_Anzeige "Status nur zur Defintion von Anzeige im Kombi. Hinweis: Wird für die spez. VW-Anzeige (überlappende Anzeigebereiche) verwendet. Vom AUDI-ACC im Rahmen der Modulstrategie zu bedienen.";
CM_ BO_ 804 "ab MQB mit CRC-8";
CM_ SG_ 804 ACC_04_CRC "Für MLB:
'Berechnung siehe Lastenheft 'Kommunikationsabsicherung für FlexRay und CAN''

Ab MQB und MLBevo:
'Berechnung siehe Lastenheft 'End-to-End Kommunikationsabsicherung''

Endwerte siehe Begleitdokument 'S-PDU Kennungsfolgen'";
CM_ SG_ 804 ACC_Texte_Sekundaeranz "Textdefinitionen für Anzeige ACC, Tempolimitassistent und Kurvenassistent";
CM_ SG_ 804 ACC_Texte_Zusatzanz "Beschreibt aktuell aktives Fahrprogramm/Zeitlücke usw. des ACC

0xD..0x10 = DISTANZ x stand sind im Audi D4 nicht definiert";
CM_ SG_ 804 ACC_Status_Zusatzanz "Für optionale Anzeige eines Bildes/Textes in der Zusatzanzeige. (Mitteldisplay)

0x7..0x1F = nicht definiert
";
CM_ SG_ 804 ACC_Texte "Zusätzliches Signal zu 'ACC_Texte_Primaeranz', welches Warnungen und Fahrerhinweise bzgl. ACC im Mitteldisplay des Kombis anzeigt.";
CM_ SG_ 804 ACC_Texte_braking_guard "Ausgaben der AWV-Funktionen (braking guard, Front Assist, presense):
* Deaktivierung über MMI / MIB / Kombi oder ESP-Austastung
* die Anzeige der Warnung bei Kollisionsgefahr
* Anzeige zu Beginn des AWV-Demomodus
* Meldung von Systemstörungen  sowie
";
CM_ SG_ 804 ACC_Warnhinweis "Porsche E2: zur Anzeige der gelben Warnaufforderung als Vorstufe zum TOR (TOR: Übernahmeaufforderung bei Erreichen der ACC-Systemgrenze)

VW MQB: Signal wird zur Ansteuerung der Abstandswarnung im Kombiinstrument genutzt.";
CM_ SG_ 804 ACC_Zeitluecke_Abstandswarner "Anzeige der aktuellen Zeitluecke zum vorausfahrenden Fahrzeug";
CM_ SG_ 804 ACC_Abstand_Abstandswarner "Signal dient zur Anzeige des Abstands im Kombi
Hinweis: das Signal ist mit dem Signal ACC_Einheit_Abstandswarner zu interpretieren";
CM_ SG_ 804 ACC_Tempolimit "Anzeige einer Tempolimit-Vorgabe (Geschwindigkeitsbegrenzung, Aufhebung einer Geschwindigkeitsbegrenzung)

Signalbeschreibung 0..31: siehe LH Kombi-SG_-_6.2.x_ACC";
CM_ SG_ 804 ACC_Charisma_FahrPr "MLBevo: Aktuelles Fahrprogramm des Charisma-Teilnehmers (siehe Systemlastenheft Drive Select)
MQB: Istwert der Kennlinie (siehe Systemlastenheft MQB FPA)";
CM_ SG_ 804 ACC_Charisma_Status "Rückmeldung an den Charisma-Master

Wert 0x3 ist nur für Fahrzeuge ab MQB relevant";
CM_ SG_ 804 ACC_Texte_Abstandswarner "Signal zur Ansteuerung von Fahrer- und Warnhinweisen des Abstandswarners im Mitteldisplay";
CM_ BO_ 290 "ab MQB";
CM_ SG_ 290 ACC_06_CRC "Für MLB:
'Berechnung siehe Lastenheft 'Kommunikationsabsicherung für FlexRay und CAN''

Ab MQB und MLBevo:
'Berechnung siehe Lastenheft 'End-to-End Kommunikationsabsicherung''

Endwerte siehe Begleitdokument 'S-PDU Kennungsfolgen'";
CM_ SG_ 290 ACC_limitierte_Anfahrdyn "Info für den Motor, dass beim ACC-Anfahren mit Zielfahrzeug seitens ACC eine limitierte Fahrpedalkennlinie gefordert wird.";
CM_ SG_ 290 ACC_nachtr_Stopp_Anf "Dieses Signal dient dem Motor als Trigger, dass ein nachträglicher Motorstopp eingeleitet werden kann, wenn es die Bedingungen des StSt Koordinators dies zulassen.";
CM_ SG_ 290 ACC_zul_Regelabw_unten "Anforderung an den Triebstrangkoordinator. Zulässiger Betrag der Abweichung zwischen angeforderter 'ACC_Sollbeschleunigung(_02)' und umzusetzender Sollbeschleunigung  im TSK. Im TSK wird, abhängig vom Arbeitspunkt die Toleranz und die Sollbeschleunigung f";
CM_ SG_ 290 ACC_StartStopp_Info "Freigabe bzw. Startanforderung für Start/Stopp";
CM_ SG_ 290 ACC_Sollbeschleunigung_02 "Anforderung an den Triebstrangkoordinator , eine 'ACC_Sollbeschleunigung' umzusetzen.";
CM_ SG_ 290 ACC_zul_Regelabw_oben "Anforderung an den Triebstrangkoordinator. Zulässiger Betrag der Abweichung zwischen angeforderter 'ACC_Sollbeschleunigung(_02)' und umzusetzender Sollbeschleunigung  im TSK. Im TSK wird, abhängig vom Arbeitspunkt die Toleranz und die Sollbeschleunigung f";
CM_ SG_ 290 ACC_neg_Sollbeschl_Grad_02 "Empfehlung an den Triebstrangkoordinator , mit welchem betragsmäßig maximalen negativen Gradienten eine ACC-Anforderung 'ACC_Sollbeschleunigung_02' einzuregeln ist.";
CM_ SG_ 290 ACC_pos_Sollbeschl_Grad_02 "Empfehlung an den Triebstrangkoordinator , mit welchem betragsmäßig maximalen positiven Gradienten eine ACC-Anforderung 'ACC_Sollbeschleunigung_02' einzuregeln ist.";
CM_ SG_ 290 ACC_Anfahren "Anforderung Anfahren";
CM_ SG_ 290 ACC_Anhalten "Im Falle eines gesetzten Bits wird vom ACC ein Anhalten bis in den Stand gewünscht. Das Bit wird von ACC nur unterhalb einer appl. Geschwindigkeitsschwelle gesetzt. Notwendig für die ACCplus-Funktionalität. Nicht für Audi B8 relevant, jedoch im Vorgriff a";
CM_ SG_ 290 ACC_Typ "Motor plausibilisiert seine eigene Kodierung";
CM_ SG_ 290 ACC_Status_ACC "'ACC OFF' bedeutet ACC-Hauptschalter ist 'Gerastet Aus

'ACC Reversibler Fehler' bedeutet, daß das ACC aktuell einen 
reversiblen Fehler im ACC-SG selbst oder in einem zum 
ACC-System gehörenden SG erkennt.

'ACC irreversibler Fehler' bedeutet, daß ";
CM_ SG_ 290 ACC_Minimale_Bremsung "Im Falle eines gesetzten Bits wird vom ACC dem TSK angezeigt, dass es sich im Resume_Suspend_Mode befindet. In diesem Mode darf der TSK keine ECD-Bremsung anfordern, unabhängig von der 'ACC_Sollbeschleunigungsanforderung'. Eine Fahrzeugverzögerung darf nu";
CM_ BO_ 302 "ab MQB";
CM_ SG_ 302 ACC_07_CRC "Für MLB:
'Berechnung siehe Lastenheft 'Kommunikationsabsicherung für FlexRay und CAN''

Ab MQB und MLBevo:
'Berechnung siehe Lastenheft 'End-to-End Kommunikationsabsicherung''

Endwerte siehe Begleitdokument 'S-PDU Kennungsfolgen'";
CM_ SG_ 302 ACC_Anhalteweg "Verbleibender Weg bis zum Stillstand";
CM_ SG_ 302 ACC_Anhalten "Im Falle eines gesetzten Bits wird vom ACC ein Anhalten bis in den Stand gewünscht. Das Bit wird von ACC nur unterhalb einer appl. Geschwindigkeitsschwelle gesetzt. Notwendig für die ACCplus-Funktionalität. Nicht für Audi B8 relevant, jedoch im Vorgriff a";
CM_ SG_ 302 ACC_Freilauf_Anf "Freilauf-Anforderung durch Energo/ACC";
CM_ SG_ 302 ACC_Freilauf_Info "Freilauf-Freigabe durch Aktiven Teilnehmer Freilauf";
CM_ SG_ 302 ACC_Anforderung_HMS "Bremsanforderung an den Haltemanager";
CM_ SG_ 302 ACC_Anfahren "Anforderung Anfahren";
CM_ SG_ 302 ACC_Folgebeschl "Sollbeschleunigung des ACC-Folgeregler";
CM_ SG_ 302 ACC_Sollbeschleunigung_02 "Anforderung an den Triebstrangkoordinator , eine 'ACC_Sollbeschleunigung' umzusetzen.";
CM_ BO_ 279 "ab MQB";
CM_ SG_ 279 ACC_10_CRC "Für MLB:
'Berechnung siehe Lastenheft 'Kommunikationsabsicherung für FlexRay und CAN''

Ab MQB und MLBevo:
'Berechnung siehe Lastenheft 'End-to-End Kommunikationsabsicherung''

Endwerte siehe Begleitdokument 'S-PDU Kennungsfolgen'";
CM_ SG_ 279 AWV1_Anf_Prefill "Anforderung an ESP, dass die Prefill-Funktion aktiviert werden soll.
Nur Audi B8: Umsetzung der Prefill-Anforderung im ESP nur in Verbindung mit gesetztem Bit 'AWV1_Freigabe'.";
CM_ SG_ 279 ANB_CM_Info "Information über die ANB_CM-Ausprägung";
CM_ SG_ 279 AWV2_Freigabe "Freigabit für die Warnruck-Anforderung an das ESP";
CM_ SG_ 279 AWV1_HBA_Param "Anforderung an ESP, welcher HBA-Parametersatz verwendet werden soll. Die Festlegung der Empfindlichkeitsschwellen der verschiedenen Parametersätze erfolgt mit der Applikation des Gesamtsystems ESP/ACC bzw. des HBA.
Nur Audi B8: Umsetzung der Anforderung ";
CM_ SG_ 279 AWV2_Ruckprofil "Anforderung an ESP, welcher Ruck aus einer Auswahl von max. 7 verschiedenen Ruckprofilen verwendet werden soll. Eine Umsetzung der Ruckanforderung im ESP erfolgt nur mit gesetztem Bit 'AWV2 Freigabe'.";
CM_ SG_ 279 AWV2_Priowarnung "Im Falle einer AWV2-Vorwarnung (optisch/akustisch) oder eines AWV2-Bremsruckes soll im LDW eine Fahrerwarnung bzgl. Verlassen der Fahrspur unterdrückt werden. (AWV2 hat Priorität. Eine gleichzeitige LDW-Warnung könnte den Fahrer irritieren.) 
";
CM_ SG_ 279 ANB_CM_Anforderung "ANB_CM-Anforderungsbit an das ESP";
CM_ SG_ 279 ANB_Info_Teilbremsung "Über das Signal s_ANB_Info_Teilbremsung muss das ACC-SG dem ESP-SG dauerhaft beginnend mit einer Teilbremsung-Anforderung mitteilen welche Ausprägung angefordert wird.

Signaldefinition: 
0x0 = Ausprägung 'Standard'
0x1 = Ausprägung 'Erweitert'";
CM_ SG_ 279 ANB_Notfallblinken "Info an das BCM_2 die Warnblinkanlage anzusteuern";
CM_ SG_ 279 ANB_Teilbremsung_Freigabe "Freigabe-Bit der Teilbremsung an das ESP";
CM_ SG_ 279 ANB_Zielbrems_Teilbrems_Verz_Anf "Verzögerungsanforderung der Funktionen Zielbremsung und Teibremsung an das ESP";
CM_ SG_ 279 ANB_Zielbremsung_Freigabe "Freigabe-Bit der Zielbremsung an das ESP";
CM_ SG_ 279 AWV_Vorstufe "Info an das Restfahrzeug, dass in Kürze eine Notbremsung/schnelles Ausweichmanöver erfolgt (Info wird u.a. in Dämpferregelung zur Anpassung der Regelung verwendet)";
CM_ SG_ 279 AWV_Halten "Anforderung an das ESP, das Fahrzeug nach erfolgter automatischer Bremsung bis in den Stillstand im Stillstand zu halten und eine Fahrer-Überwachung zu aktivieren.";
CM_ SG_ 279 AWV_CityANB_Auspraegung "Plausibilisierung der Codierung der CityANB-Ausprägung im ESP.";
CM_ SG_ 279 PCF_Freigabe "Freigabe der Funktion PreCrash-Front";
CM_ SG_ 279 AWV1_ECD_Anlauf "Anforderung an ESC, dass die ESP-Pumpe für eine bevorstehende ECD-Regelung aktiviert werden soll.";
CM_ SG_ 279 PCF_Time_to_collision "Prädizierter Aufprallzeipunkt des relevanten Objektes";
CM_ SG_ 679 ACC_Regelgeschw "Zur Anzeige der Regelgeschwindigkeit (z.B. Kurven- / Tempolimitassistent) im Kombiinstrument";
CM_ SG_ 679 ACC_Einheit_maxSetzgeschw "Einheit zu Signal ACC_maxSetzgeschw";
CM_ SG_ 679 ACC_maxSetzgeschw "maximale ACC-Setzgeschwindigkeit zur Ansteuerung des ACC-Setzbereichs im Kombi
Hinweis: Signal ist mit Signal ACC_Einheit_maxSetzgeschw zu interpretieren";
CM_ SG_ 679 ACC_minRegelgeschw "Signal dient zur Anzeige von Regelabweichungen.
Subtrahiert von der Regelgeschwindigkeit ergibt sich eine Toleranzgeschwindigkeit.";
CM_ SG_ 679 ACC_maxRegelgeschw "Signal dient zur Anzeige von Regelabweichungen.
Addiert zu der Regelgeschwindigkeit ergibt sich eine Toleranzgeschwindigkeit.";
CM_ SG_ 679 ACC_Tempolimitassistent "Ansteuerng einer Anzeige zur Funktion Tempolimitassistent";
CM_ SG_ 679 ACC_Kurvenassistent "Ansteuerung einer Anzeige zur Funktion Kurvenassistent";
CM_ SG_ 679 ACC_RUV "Anzeige für Rechtsunterholverhinderung in Abhängigkeit Rechts- / Linksverkehr";
CM_ SG_ 679 ACC_Tachokranz "Für zusätzliche Status- und Einstellbereichsanzeige im Tacho. (z.B. Tachokranz)
";
CM_ SG_ 679 ACC_Typ_Tachokranz_unten "Mit diesem Bit wird die LED unterhalb der minimalen Setzgeschwindigkeit an/ausgeschaltet.
";
CM_ SG_ 679 ACC_ENG_Texte "Signal zur Ansteuerung von Fahrerhinweisen der Energo-Funktioin im Mitteldisplay ";
CM_ SG_ 681 AWV_Warnung "Hinweisanzeige im Kombi 'Hauptdisplay'";
CM_ SG_ 681 AWV_Texte "Hinweisanzeige im Kombi 'Hauptdisplay'
3 = Demomodus --> nur für VW
4 = System_aus --> nur für PAG
";
CM_ SG_ 681 AWV_Status_Anzeige "Signal zur Realisierung des BAP-Koordiantors
Signal identisch zu AWV_BAP_Status 
Kl15 aus: nicht bereitgestellt.";
CM_ SG_ 681 AWV_Einstellung_System_FSG "Signal zur Realisierung des BAP-Koordiantors";
CM_ SG_ 681 AWV_Einstellung_Warnung_FSG "Signal zur Realisierung des BAP-Koordinators";
CM_ SG_ 681 AWV_Warnlevel "Warnlevel der Funktion Anhaltewegverkürzung";
CM_ SG_ 2527679682 ACC_ASM_Ereignis "Dieses Signal definiert, welche Funktion und welche Art von Aktivität das Senden der Botschaft an den Assistenzsystemmonitor ASM (Host SG: Safety Computer) veranlasst hat.";
CM_ SG_ 2527679682 ACC_ASM_Zeitstempel "Dieses Signal ermöglicht die zeitliche Zuordnung der von ACC an den Assistenzsystemmonitor ASM (Host SG: Safety Computer) gesendeten Statusbotschaften.";
CM_ SG_ 2527679682 ACC_ASM_Data_1 "Dieses Signal wird von ACC (LongRangeRadar) befüllt und an den Assistenzsystemmonitor ASM (Host SG: Safety Computer) gesendet.";
CM_ SG_ 2527679682 ACC_ASM_Data_2 "Dieses Signal wird von ACC (LongRangeRadar) befüllt und an den Assistenzsystemmonitor ASM (Host SG: Safety Computer) gesendet.";
CM_ SG_ 2527679682 ACC_ASM_Data_3 "Dieses Signal wird von ACC (LongRangeRadar) befüllt und an den Assistenzsystemmonitor ASM (Host SG: Safety Computer) gesendet.";
CM_ SG_ 2527679682 ACC_ASM_Data_4 "Dieses Signal wird von ACC (LongRangeRadar) befüllt und an den Assistenzsystemmonitor ASM (Host SG: Safety Computer) gesendet.";
CM_ SG_ 2527679682 ACC_ASM_Data_5 "Dieses Signal wird von ACC (LongRangeRadar) befüllt und an den Assistenzsystemmonitor ASM (Host SG: Safety Computer) gesendet.";
CM_ SG_ 2527679682 ACC_ASM_Data_6 "Dieses Signal wird von ACC (LongRangeRadar) befüllt und an den Assistenzsystemmonitor ASM (Host SG: Safety Computer) gesendet.";
CM_ SG_ 64 Airbag_01_CRC "Für MLB:
'Berechnung siehe Lastenheft 'Kommunikationsabsicherung für FlexRay und CAN''

Ab MQB und MLBevo:
'Berechnung siehe Lastenheft 'End-to-End Kommunikationsabsicherung''

Endwerte siehe Begleitdokument 'S-PDU Kennungsfolgen'";
CM_ SG_ 64 AB_RGS_Anst "PreCrash-Ansteuerung reversibler Gurtstraffer (Aktivierung und Kraftniveau)

10xx = deaktiviert";
CM_ SG_ 64 AB_Front_Crash "Bit wird bei Überschreitung der Gurtstraffer-, US- und RdW-Schwelle gesetzt";
CM_ SG_ 64 AB_Heck_Crash "Wird für alle neu anlaufenden Projekte umgesetzt: AB8.4, Audi8/VW8";
CM_ SG_ 64 AB_SF_Crash "Z.Zt. nur in Verbindung mit Crash-Intensität >= 100b (Kraftstoffpumpenabschaltung) verwendet.";
CM_ SG_ 64 AB_SB_Crash "Z.Zt. nur in Verbindung mit Crash-Intensität >= 100b (Kraftstoffpumpenabschaltung) verwendet.
";
CM_ SG_ 64 AB_Rollover_Crash "Wird im B6/B7 Cabrio und New Beetle Cabrio bedient. ";
CM_ SG_ 64 AB_Crash_Int "Crash_Intensität_1 = fahrzeugabhängige Reaktionen im Crash
Crash_Intensität_2 = fahrzeugabhängige Reaktionen im Crash
Crash_Intensität_3 = fahrzeugabhängige Reaktionen im Crash

Die jeweiligen fahrzeugabhängigen Reaktionen im Crash sind in einem separ";
CM_ SG_ 64 AB_Lampe "Sicherheitswarnlampe im Kombi wird vom Airbag-SG angesteuert; Zustand der Lampe wird auf dem CAN-Bus ausgegeben (auch Blinkinformation).";
CM_ SG_ 64 AB_Deaktiviert "Airbag oder Gurtstraffer wurden per Anpassung deaktiviert: Aktualisierung erst nach Selbsttest";
CM_ SG_ 64 AB_VB_deaktiviert "Als Option vorgehalten, Beifahrerairbag wurden per Schlüsselschalter oder Insassenerkennung deaktiviert";
CM_ SG_ 64 AB_Systemfehler "Systemfehler Ggf. wird Warnlampe dauernd eingeschaltet.";
CM_ SG_ 64 AB_Diagnose "Airbag in Diagnose";
CM_ SG_ 64 AB_Stellgliedtest "Information, ob Airbag im Stellgliedtest ist, um eine Notrufauflösung beim Stellgliedtest zu verhindern";
CM_ SG_ 64 AB_Erh_Auf_VB "Der Fahrer soll bei einem Statuswechsel des Beifahrerairbags (ausgelöst durch die Beifahrerinsassenerkennung oder den Schlüsselschloßschalter) aufmerksam gemacht werden durch eine Anzeige im Kombi. Nur Audi: gültig für: AB2 (4-Türer AU352), B7, C6, D3";
CM_ SG_ 64 AB_Gurtwarn_VF "Fahrer hat Gurt nicht gesteckt, Anzeige im Kombi";
CM_ SG_ 64 AB_Gurtwarn_VB "Beifahrer hat Gurt nicht gesteckt, Anzeige im Kombi";
CM_ SG_ 64 AB_Anzeige_Fussg "Anzeige für ausgelöste Fussgängerschutz-Aktuatorik";
CM_ SG_ 64 AB_Texte_AKS "Textanzeige für pyrotechnische Auslösung der aktiven Kopfstütze (AKS)";
CM_ SG_ 64 AB_PAO_Leuchte_Anf "Anforderung an die Passenger-Airbag-Off Leuchte in der Dachkonsole (ein / aus), Einsatz nur bei PAG";
CM_ SG_ 64 AB_MKB_gueltig "Multi-Kollisions-Bremsung im Airbag freigeschaltet";
CM_ SG_ 64 AB_MKB_Anforderung "Anforderung Multi-Kollisions-Bremsung";
CM_ SG_ 64 AB_Versorgungsspannung "Übertragung der Plausibilitätsinformation Kl.15-Last vs. Kl.15-CAN.
Bedienung im Fall Kl.15-Last 'EIN' und Kl.15-CAN 'AUS' mit Ausgabe Warnung/Akustik im Kombi.";
CM_ SG_ 64 AB_Deaktivierung_HV "Deaktivierung des HV-Systems und der HV-Teilnehmer im Crash (u.a. Hybrid- und Elektrofahrzeuge)";
CM_ SG_ 64 AB_EDR_Trigger "Triggerbedingung zur dezentralen Aufzeichnung unfallrelevanter Daten im Event Data Recorder";
CM_ SG_ 64 SC_Masterzeit_Offset "Erweiterung des Signals SC_Masterzeit um zwei höherwertige Bits, so dass ein Zeitbereich von ~20s (statt 5s) abgedeckt werden kann. Der aus SC_Masterzeit_Offset und SC_Masterzeit zu bildende Zeitstempel wird für die Synchronisation von Ereignissen der Fun";
CM_ SG_ 64 SC_Masterzeit "Masterzeit für alle Objektlisten";
CM_ SG_ 1312 Airbag_02_CRC "Für MLB:
'Berechnung siehe Lastenheft 'Kommunikationsabsicherung für FlexRay und CAN''

Ab MQB und MLBevo:
'Berechnung siehe Lastenheft 'End-to-End Kommunikationsabsicherung''

Endwerte siehe Begleitdokument 'S-PDU Kennungsfolgen'";
CM_ SG_ 1312 LoGeWa_Event_Kombiwarnung "Event für Kombiwarnung";
CM_ SG_ 1312 AB_Anforderung_eCall "Trigger für Car2X Steuergerät das ein eCall Ereignis erkannt wurde.";
CM_ SG_ 1312 AB_Anprall_Seite_Beifahrer "Uebermittlung der Lage einer Kollision, Anprallzone Beifahrerseite Seite";
CM_ SG_ 1312 AB_Anprall_Rollover "Uebermittlung der Lage einer Kollision, Rollover erkannt";
CM_ SG_ 1312 AB_Anprall_FGS "Uebermittlung der Lage einer Kollision, Fussgaengerschutz-Aktorik";
CM_ SG_ 1312 AB_Anprall_Front_Beifahrer "Uebermittlung der Lage einer Kollision, Anprallzone Beifahrerseite vorne";
CM_ SG_ 1312 AB_Anprall_Front_Fahrer "Uebermittlung der Lage einer Kollision, Anprallzone Fahrerseite vorne";
CM_ SG_ 1312 AB_Anprall_Heck_Beifahrer "Uebermittlung der Lage einer Kollision, Anprallzone Beifahrerseite hinten";
CM_ SG_ 1312 AB_Anprall_Heck_Fahrer "Uebermittlung der Lage einer Kollision, Anprallzone Fahrerseite hinten";
CM_ SG_ 1312 AB_Wickelklappung_Reihe2_MI "Status Wickelklappung 2. Reihe Mitte, Mehrausstattung";
CM_ SG_ 1312 AB_Belegung_VB "Belegungserkennung vorne Beifahrer. Wird in US-Steuergeräten über Bladder-Matte bedient, optional bei RdW, falls SBE_EuroNCAP entschieden wird.";
CM_ SG_ 1312 AB_Abschaltanf_SIH_BF "Die Insassenerkennung auf der Beifahrerseite fordert bei Übertemperatur eine Abschaltung der Sitzheizung an. Die Übertemperatur kann bei niederohmigen Nebenschlüssen der Sitzheizungsmatte als Folge von zu hohem resultierenden Strom auftreten.";
CM_ SG_ 1312 AB_Anprall_Seite_Fahrer "Uebermittlung der Lage einer Kollision, Anprallzone Fahrerseite Seite";
CM_ SG_ 1312 SC_PAO_Schriftzug_Anf "Sollwert für LED 'PASSENGER AIRBAG' in Anzeige Passenger Airbag On/Off";
CM_ SG_ 1312 SC_PAO_ON_Anf "Sollwert für LED 'ON' in Anzeige Passenger Airbag On/Off";
CM_ SG_ 1312 SC_PAO_OFF_Anf "Sollwert für LED 'OFF' in Anzeige Passenger Airbag On/Off";
CM_ SG_ 1312 AB_Crashschwere "Übermittlung der Crashschwere an das Gateway (OBDC)";
CM_ SG_ 1312 AB_Anforderung_USM "Trigger für Gateway (OBDC) und MIB/MMI, dass ein USM-Ereignis erkannt wurde.";
CM_ SG_ 1312 AB_Gurtschloss_FA "Gurtschlosstatatus Fahrerseite";
CM_ SG_ 1312 AB_Gurtschloss_BF "Gurtschlossstatus Beifahrerseite";
CM_ SG_ 1312 AB_Gurtschloss_Reihe2_FA "Gurtschlossstatus 2. Reihe Fahrerseite, Mehrausstattung";
CM_ SG_ 1312 AB_Gurtschloss_Reihe2_MI "Gurtschlossstatus 2. Reihe Mitte,  Mehrausstattung";
CM_ SG_ 1312 AB_Gurtschloss_Reihe2_BF "Gurtschlossstatus 2. Reihe Beifahrerseite,  Mehrausstattung";
CM_ SG_ 1312 AB_Gurtschloss_Reihe3_FA "Gurtschlossstatus 3. Reihe Fahrerseite,  Mehrausstattung";
CM_ SG_ 1312 AB_Gurtschloss_Reihe3_MI "Gurtschlossstatus 3. Reihe Mitte,  Mehrausstattung";
CM_ SG_ 1312 AB_Gurtschloss_Reihe3_BF "Gurtschlossstatus 3. Reihe Beifahrerseite,  Mehrausstattung";
CM_ SG_ 1312 AB_Sitzpos_Sens_FA "Ausgabe Sitzposition Fahrer";
CM_ SG_ 1312 AB_Sitzpos_Sens_BF "Ausgabe Sitzposition Beifahrer";
CM_ SG_ 1312 AB_Wickelklappung_Reihe2_BF "Status Wickelklappung 2. Reihe Beifahrerseite, Mehrausstattung";
CM_ SG_ 1312 AB_Wickelklappung_Reihe2_FA "Status Wickelklappung 2. Reihe Fahrerseite, Mehrausstattung";
CM_ SG_ 897 US_RDir_VL "direkte Messung des US-Sensors vorne links";
CM_ SG_ 897 US_RDir_VLM "direkte Messung des US-Sensors vorne links Mitte";
CM_ SG_ 897 US_RIndir_VLM_VL "indirekte Messung der US-Sensoren vorne links Mitte (Sender) und vorne links (Empfänger)";
CM_ SG_ 897 US_RIndir_VLM_VRM "indirekte Messung der US-Sensoren vorne links Mitte (Sender) und vorne rechts Mitte (Empfänger)";
CM_ SG_ 897 US_RIndir_VL_VLM "indirekte Messung der US-Sensoren vorne links (Sender) und vorne links Mitte (Empfänger)";
CM_ SG_ 897 US_GDir_VL "Güte der direkten Messung des US-Sensors vorne links";
CM_ SG_ 897 US_GDir_VLM "Güte der direkten Messung des US-Sensors vorne links Mitte";
CM_ SG_ 897 US_GIndir_VLM_VL "Güte der indirekten Messung der US-Sensoren vorne links Mitte (Sender) und vorne links (Empfänger)";
CM_ SG_ 897 US_GIndir_VLM_VRM "Güte der indirekten Messung der US-Sensoren vorne links Mitte (Sender) und vorne rechts Mitte (Empfänger)";
CM_ SG_ 897 US_GIndir_VL_VLM "Güte der indirekten Messung der US-Sensoren vorne links (Sender) und vorne links Mitte (Empfänger)";
CM_ SG_ 897 APS_01_Paketzaehler "Wird verwendet zur Verifizierung der Botschafsreihenfolge
APS_Master
APS_01
APS_02

";
CM_ SG_ 898 US_RDir_VR "direkte Messung des US-Sensors vorne rechts";
CM_ SG_ 898 US_RDir_VRM "direkte Messung des US-Sensors vorne rechts Mitte";
CM_ SG_ 898 US_RIndir_VRM_VR "indirekte Messung der US-Sensoren vorne rechts  Mitte (Sender) und vorne rechts (Empfänger)";
CM_ SG_ 898 US_RIndir_VRM_VLM "indirekte Messung der US-Sensoren vorne rechts Mitte (Sender) und vorne links Mitte (Empfänger)";
CM_ SG_ 898 US_RIndir_VR_VRM "indirekte Messung der US-Sensoren vorne rechts (Sender) und vorne rechts Mitte (Empfänger)";
CM_ SG_ 898 US_GDir_VR "Güte der direkten Messung des US-Sensors vorne rechts";
CM_ SG_ 898 US_GDir_VRM "Güte der direkten Messung des US-Sensors vorne rechts Mitte";
CM_ SG_ 898 US_GIndir_VRM_VLM "Güte der indirekten Messung der US-Sensoren vorne rechts Mitte (Sender) und vorne links Mitte (Empfänger)";
CM_ SG_ 898 US_GIndir_VRM_VR "Güte der indirekten Messung der US-Sensoren vorne rechts Mitte (Sender) und vorne rechts (Empfänger)";
CM_ SG_ 898 US_GIndir_VR_VRM "Güte der indirekten Messung der US-Sensoren vorne rechts (Sender) und vorne rechts Mitte (Empfänger)";
CM_ SG_ 898 APS_02_Paketzaehler "Wird verwendet zur Verifizierung der Botschafsreihenfolge
APS_Master
APS_01
APS_02

";
CM_ SG_ 927 US_RDir_VRS "direkte Messung des US-Sensors vorne rechts seitlich";
CM_ SG_ 927 US_RDir_VLS "direkte Messung des US-Sensors vorne links seitlich";
CM_ SG_ 927 US_RDir_HRS "direkte Messung des US-Sensors hinten rechts seitlich";
CM_ SG_ 927 US_RDir_HLS "direkte Messung des US-Sensors hinten links seitlich";
CM_ SG_ 927 US_Fehler_VS "Fehler US-Sensoren vorne seitlich";
CM_ SG_ 927 US_Fehler_HS "Fehler US-Sensor hinten seitlich";
CM_ SG_ 927 US_Verschmutzung_VS "Verschmutzung US-Sensoren vorne seitlich";
CM_ SG_ 927 US_Verschmutzung_HS "Verschmutzung US-Sensoren hinten seitlich";
CM_ SG_ 927 US_NichtVerfuegbarkeit_VS "Nichtverfuegbarkeit US-Sensoren vorne seitlich";
CM_ SG_ 927 US_NichtVerfuegbarkeit_HS "Nichtverfuegbarkeit US-Sensoren hinten seitlich";
CM_ SG_ 927 APS_03_Paketzaehler "Wird verwendet zur Verifizierung der Botschafsreihenfolge";
CM_ SG_ 896 US_ACC_CRC "Ab MQB und MLBevo:
'Berechnung siehe Lastenheft 'End-to-End Kommunikationsabsicherung''

Endwerte siehe Begleitdokument 'S-PDU Kennungsfolgen'";
CM_ SG_ 896 US_Sende_Modus "US=Ultraschall
US_SendeModus:
0x0: keine für das ACC-SG relevanten Abstandswerte werden gesendet
0x1: 4K ext. range, 10 Signalwege verfügbar ('4m')
0x2: 4K norm. range, 10 Signalwege verfügbar ('2m')
0x3: 6K ext. range, 16 Signalwege verfügbar ('4m')";
CM_ SG_ 896 US_relevanter_Fehler "US erkennt einen Fehler, die Objektdetektion im Frontbereich betreffend, mit FSP-Eintrag.";
CM_ SG_ 896 US_relevante_Nichtverfuegbarkeit "US erkennt eine Nichtverfuegbarkeit, die Objektdetektion im Frontbereich betreffend, ohne FSP-Eintrag";
CM_ SG_ 896 US_Freisicht_nio "Blindheitserkennung
Nach KL15-Ein konnte Freisichtprüfung noch nicht erfüllt werden";
CM_ SG_ 896 US_blindness_detected "US erkennt selbständig eigene Blindheit durch äußere Einflüsse.";
CM_ SG_ 896 US_Sende_Modus_hinten "US=Ultraschall
US_Sende_Modus_hinten:
0x0: keine für das ACC-SG relevanten Abstandswerte werden gesendet
0x1....0x4: frei
0x5: 2-K. ext. range (PLA), 2 Signalwege verfügbar ('4m')
0x6: Modeumschaltung (ext -> norm oder norm -> ext)
0x7: Blindheitspr";
CM_ SG_ 896 APS_Master_Sendestatus "Gibt den Sendestatus der Botschaft APS_Master an (notwendig für IL-Unterstützung)";
CM_ SG_ 896 US_Freie_Weglaenge_Front_Typ "Beschreibt die Begrenzung der freien Weglänge vor dem Fahrzeug. Gehört somit zum Signal US_Freie_Weglaenge_Front. Die freie Weglänge kann bei einem gemessenen Objekt enden oder bei der maximalen Sensorreichweite.";
CM_ SG_ 896 US_Freie_Weglaenge_Front "US_Freie Weglaenge vor dem Fahrzeug - lenkwinkelabhängig. Die freie Weglänge kann dabei durch Hindernisse oder den maximalen Sichtbereich beschränkt sein. Siehe Signal US_Freie_Weglaenge_Front_Typ";
CM_ BO_ 870 "Nur die Kombination des statischen und toggelnden Signals ergibt den Blinktakt für die Hell & Dunkelphase";
CM_ SG_ 870 BM_ZV_auf "Blinken bei ZV auf

";
CM_ SG_ 870 BM_ZV_zu "Blinken bei ZV zu

";
CM_ SG_ 870 BM_DWA_ein "Status Quittierungsblinken DWA";
CM_ SG_ 870 BM_DWA_Alarm "Status DWA-Alarmblinken
";
CM_ SG_ 870 BM_Crash "Status Crashblinken
";
CM_ SG_ 870 BM_Panik "Panikblinken
";
CM_ SG_ 870 BM_Not_Bremsung "Notbremsblinken

";
CM_ SG_ 870 BM_GDO "Blinken bei UGDO anlernen

";
CM_ SG_ 870 BM_Warnblinken "Warnblinken

";
CM_ SG_ 870 BM_Taxi_Notalarm "Blinken bei Taxi-Not-Alarm

";
CM_ SG_ 870 BM_Telematik "Telematikblinken
";
CM_ SG_ 870 BM_links "Richtungsblinken links

";
CM_ SG_ 870 BM_rechts "Richtungsblinken rechts

";
CM_ SG_ 870 Blinken_li_Fzg_Takt "Fzg-Takt Blinker links

";
CM_ SG_ 870 Blinken_re_Fzg_Takt "Fzg-Takt Blinker rechts

";
CM_ SG_ 870 Blinken_li_Kombi_Takt "Kombi-Takt Blinker links

";
CM_ SG_ 870 Blinken_re_Kombi_Takt "Kombi-Takt Blinker rechts

";
CM_ SG_ 870 BM_NBA_n_codiert_n_aktiv "Notbremsanzeige nicht codiert/nicht aktiv (Fehler)";
CM_ SG_ 870 BM_NBA_Status "Notbremsanzeige Status nicht aktiv / BRL Dunkelphase / BRL Hellphase";
CM_ SG_ 870 BM_WBT_Beleuchtung "Aktivierung Warnblinktasterfunktionsbeleuchtung
Warnblinktasterfunktionsbeleuchtung soll aktiviert werden (statisch auf 1)";
CM_ SG_ 870 BM_HD_Oeffnung_angelernt "Das HDSG fordert über das CAN Signal HDSG_01.HD_Rueckmeld_prog eine Blinkerquittierung beim BCM2 an.
Wenn die Geschwindigkeit kleiner einer vorgegebenen Schwelle (default 2km/h) ist wird das Signal BM_HD_Öffnung_angelernt versendet und die Blinkerquittie";
CM_ SG_ 870 BM_Autobahn "Status Autobahnblinken
";
CM_ SG_ 870 BM_Rollenmodus_Blinken "Das Signal wird statisch gesetzt, wenn die Blinkerart Rollenmodus_Blinken aktiv ist.";
CM_ SG_ 870 BM_Recas "Blinkermodus RECAS  (RearEndCollisionAlertSignal)";
CM_ SG_ 870 BM_Wischblinken "Blinkermodus Wisch_Blinken";
CM_ SG_ 870 BM_Telematik_Abbruchgrund "Gibt bei erwaretem aber ausbleibendem Flankenanstieg der BM_Telematik an wieso die Ausführung verhindert wurde. Bei Flankenabfall der BM_Telematik wird angegeben wieso die Ausführung beendet wurde.

Bei nicht bereitem Sender soll 'init' gesendet werden,";
CM_ SG_ 806 BV_Linie_01_dy "y-Abstand zum Fahrzeug-Koordinatensystem";
CM_ SG_ 806 BV_Linie_01_Existenzmass "Existenzwahrscheinlichkeit für eine Linie (Markierung)

Umrechnungsfaktor 2^-6";
CM_ SG_ 806 BV_Linie_01_Farbe "Linienfarbe";
CM_ SG_ 806 BV_Linie_01_Gierw_diff "Winkel zwischen FZ-Längsachse und Tangente am Anfangspunkt des Tracks

Umrechnungsfaktor 2^-11";
CM_ SG_ 806 BV_Linie_01_hor_Kruemm_Aend "horizontale Krümmungsänderung der Linie
Multiplikation des Rohwerts mit 2^-21

(Einheit im Steuergerät 1/m^2)";
CM_ SG_ 806 BV_Linie_01_hor_Kruemmung "horizontale Krümmung der Linie
Multiplikation des Rohwerts mit 2^-16

(Einheit im Steuergerät 1/m)";
CM_ SG_ 806 BV_Linie_01_Liniennummer "Linke Masterlinie: Liniennummer der Videoverarbeitung

0 = keine Linie
1 .. 15 eindeutige Liniennummer";
CM_ SG_ 806 BV_Linie_01_Typ "Markierungstyp";
CM_ SG_ 807 BV_Linie_02_dy "y-Abstand zum Fahrzeug-Koordinatensystem";
CM_ SG_ 807 BV_Linie_02_Existenzmass "Existenzwahrscheinlichkeit für eine Linie (Markierung)

Umrechnungsfaktor 2^-6";
CM_ SG_ 807 BV_Linie_02_Farbe "Linienfarbe";
CM_ SG_ 807 BV_Linie_02_Gierw_diff "Winkel zwischen FZ-Längsachse und Tangente am Anfangspunkt des Tracks

Umrechnungsfaktor 2^-11";
CM_ SG_ 807 BV_Linie_02_hor_Kruemm_Aend "horizontale Krümmungsänderung der Linie
Multiplikation des Rohwerts mit 2^-21

(Einheit im Steuergerät 1/m^2)";
CM_ SG_ 807 BV_Linie_02_hor_Kruemmung "horizontale Krümmung der Linie
Multiplikation des Rohwerts mit 2^-16

(Einheit im Steuergerät 1/m)";
CM_ SG_ 807 BV_Linie_02_Liniennummer "Rechte Masterlinie: Liniennummer der Videoverarbeitung

0 = keine Linie
1 .. 15 eindeutige Liniennummer";
CM_ SG_ 807 BV_Linie_02_Typ "Markierungstyp";
CM_ SG_ 808 BV_Linie_03_dy "y-Abstand zum Fahrzeug-Koordinatensystem";
CM_ SG_ 808 BV_Linie_03_Existenzmass "Existenzwahrscheinlichkeit für eine Linie (Markierung)

Umrechnungsfaktor 2^-6";
CM_ SG_ 808 BV_Linie_03_Farbe "Linienfarbe";
CM_ SG_ 808 BV_Linie_03_Gierw_diff "Winkel zwischen FZ-Längsachse und Tangente am Anfangspunkt des Tracks

Umrechnungsfaktor 2^-11";
CM_ SG_ 808 BV_Linie_03_hor_Kruemm_Aend "horizontale Krümmungsänderung der Linie
Multiplikation des Rohwerts mit 2^-21

(Einheit im Steuergerät 1/m^2)";
CM_ SG_ 808 BV_Linie_03_hor_Kruemmung "horizontale Krümmung der Linie
Multiplikation des Rohwerts mit 2^-16";
CM_ SG_ 808 BV_Linie_03_Liniennummer "Liniennummer der Videoverarbeitung

0 = keine Linie
1 .. 15 eindeutige Liniennummer";
CM_ SG_ 808 BV_Linie_03_Typ "Markierungstyp";
CM_ SG_ 809 BV_Linie_04_dy "y-Abstand zum Fahrzeug-Koordinatensystem";
CM_ SG_ 809 BV_Linie_04_Existenzmass "Existenzwahrscheinlichkeit für eine Linie (Markierung)

Umrechnungsfaktor 2^-6";
CM_ SG_ 809 BV_Linie_04_Farbe "Linienfarbe";
CM_ SG_ 809 BV_Linie_04_Gierw_diff "Winkel zwischen FZ-Längsachse und Tangente am Anfangspunkt des Tracks

Umrechnungsfaktor 2^-11";
CM_ SG_ 809 BV_Linie_04_hor_Kruemm_Aend "horizontale Krümmungsänderung der Linie
Multiplikation des Rohwerts mit 2^-21

(Einheit im Steuergerät 1/m^2)";
CM_ SG_ 809 BV_Linie_04_hor_Kruemmung "horizontale Krümmung der Linie
Multiplikation des Rohwerts mit 2^-16

(Einheit im Steuergerät 1/m)";
CM_ SG_ 809 BV_Linie_04_Liniennummer "Liniennummer der Videoverarbeitung

0 = keine Linie
1 .. 15 eindeutige Liniennummer";
CM_ SG_ 809 BV_Linie_04_Typ "Markierungstyp";
CM_ SG_ 1162 BV_Linie_01_dx_Vorausschau "x-Abstand des letzten gültigen Messwerts, Ausgabe phys. '0 m', wenn der Beginn der Linie bereits überfahren wurde";
CM_ SG_ 1162 BV_Linie_02_dx_Vorausschau "x-Abstand des letzten gültigen Messwerts, Ausgabe phys. '0 m', wenn der Beginn der Linie bereits überfahren wurde";
CM_ SG_ 1162 BV_Linie_03_dx_Vorausschau "x-Abstand des letzten gültigen Messwerts, Ausgabe phys. '0 m', wenn der Beginn der Linie bereits überfahren wurde";
CM_ SG_ 1162 BV_Linie_04_dx_Vorausschau "x-Abstand des letzten gültigen Messwerts, Ausgabe phys. '0 m', wenn der Beginn der Linie bereits überfahren wurde";
CM_ BO_ 901 "ab MQB ohne CHK und mit geänderter Sendeart";
CM_ SG_ 901 CHA_Ziel_FahrPr_AGA "Anforderung Ziel-Fahrprogramm AGA/SAK2 (Aussensound)";
CM_ SG_ 901 CHA_Ziel_FahrPr_ESP "Anforderung Ziel-Fahrprogramm ESP";
CM_ SG_ 901 CHA_Ziel_FahrPr_Freilauf "Anforderung Ziel-Fahrprogramm Funktion Freilauf";
CM_ SG_ 901 CHA_Fahrer_Umschaltung "Die manuelle Umschaltung durch den Fahrer soll signalisiert werden, um zu automatischen Umschaltungen (z.B. Retries) differenzieren zu können.";
CM_ SG_ 901 CHA_Fahrer_Umschaltung_BMA "Die manuelle Umschaltung der Betriebsmodusauswahl durch den Fahrer soll signalisiert werden, um zu automatischen Umschaltungen (z.B. Retries) differenzieren zu können.";
CM_ SG_ 901 CHA_Ziel_FahrPr_MO "Anforderung Ziel-Fahrprogramm Motor";
CM_ SG_ 901 CHA_Ziel_FahrPr_GE "Anforderung Ziel-Fahrprogramm Getriebe";
CM_ SG_ 901 CHA_Ziel_FahrPr_ALR "Anforderung Ziel-Fahrprogramm Allrad";
CM_ SG_ 901 CHA_Ziel_FahrPr_MO_BZS "Anforderung Zielfahrprogramm Motor-Betriebszusände";
CM_ SG_ 901 CHA_Ziel_FahrPr_DR "Anforderung Ziel-Fahrprogramm Dämpfer";
CM_ SG_ 901 CHA_Ziel_FahrPr_VAQ "Anforderung Ziel-Fahrprogramm VAQ";
CM_ SG_ 901 CHA_Ziel_FahrPr_AFS "Anforderung Ziel-Fahrprogramm AFS";
CM_ SG_ 901 CHA_Ziel_FahrPr_RGS "Anforderung Ziel-Fahrprogramm Funktion Reversibler Gurtstraffer";
CM_ SG_ 901 CHA_Ziel_FahrPr_EPS "Anforderung Ziel-Fahrprogramm Elektrische Lenkhilfe";
CM_ SG_ 901 CHA_Ziel_FahrPr_ACC "MQB
Anforderung Ziel-Fahrprogramm ACC";
CM_ SG_ 901 CHA_Ziel_FahrPr_SAK "Anforderung Ziel-Fahrprogramm Soundaktuator";
CM_ SG_ 901 CHA_Ziel_FahrPr_MO_StSt "Anforderung Ziel-Fahrprogramm Funktion Motor Start-Stopp";
CM_ SG_ 1000 CHA_Ziel_FahrPr_EBKV "Signal zur Ansteuerung des EBKV durch den Charisma-Koordinator";
CM_ SG_ 1000 CHA_Ziel_FahrPr_IL "Anforderung Ziel-Fahrprogramm Integrallenkung";
CM_ SG_ 1000 CHA_Current_Mode "Aktuell eingestelltes Charisma Fahrprogramm";
CM_ SG_ 1000 CHA_Fahrer_Umschaltung "Die manuelle Umschaltung durch den Fahrer soll signalisiert werden, um zu automatischen Umschaltungen (z.B. Retries) differenzieren zu können.";
CM_ SG_ 1000 CHA_Ziel_FahrPr_QS "Anforderung Ziel-Fahrprogramm geregelte Hinterachsquersperre";
CM_ SG_ 1000 CHA_Ziel_FahrPr_SCU "Anforderung Ziel-Fahrprogramm SCU";
CM_ SG_ 1000 CHA_Ziel_FahrPr_HAL "Anforderung Zielfahrprogramm Hinterachslenkung (HAL)";
CM_ SG_ 1000 CHA_Ziel_FahrPr_NR "Anforderung Ziel-Fahrprogramm Niveaureglierung";
CM_ SG_ 1000 CHA_Ziel_FahrPr_AV "Anforderung Ziel-Fahrprogramm AreaView2";
CM_ SG_ 1000 CHA_Ziel_FahrPr_MXB "Anforderung Ziel-Fahrprogramm MXB";
CM_ SG_ 1000 CHA_Ziel_FahrPr_AFR "Anforderung Ziel-Fahrprogramm Aktive Fahrwerk Regelung (eAWS und eABC)";
CM_ SG_ 1000 CHA_Ziel_FahrPr_HDC "Anforderung Ziel-Fahrprogramm Hill Descent Control";
CM_ SG_ 1000 CHA_Ziel_FahrPr_EAR "Anforderung Zielfahrprogramm EAR (EFP Allrad Regelsysteme)";
CM_ SG_ 1000 CHA_Ziel_FahrPr_AEB "Anforderung Ziel-Fahrprogramm AEB (Autonomous Emergency Braking)";
CM_ SG_ 1000 CHA_Ziel_FahrPr_FCWO "Anforderung Ziel-Fahrprogramm FCWO (Objektwarnung)";
CM_ SG_ 1000 CHA_Ziel_FahrPr_FCWP "Anforderung Ziel-Fahrprogramm FCWP (Personenwarnung)";
CM_ BO_ 2549880330 "Diagnosezugriff Leistungsmodul LED";
CM_ SG_ 2549880330 DIA_LED_LM_L_Req_Data "Diagnosezugriff & Flashen LED Leistungsmodule";
CM_ SG_ 2550011402 DIA_LED_LM_L_Resp_Data "Diagnosezugriff & Flashen LED Leistungsmodule";
CM_ BO_ 2549880331 "Diagnosezugriff Leistungsmodul LED";
CM_ SG_ 2549880331 DIA_LED_LM_R_Req_Data "Diagnosezugriff & Flashen LED Leistungsmodule";
CM_ SG_ 2550011403 DIA_LED_LM_R_Resp_Data "Diagnosezugriff & Flashen LED Leistungsmodule";
CM_ SG_ 1714 DGN_Verlernzaehler "wrap around 254 --> 0";
CM_ SG_ 1714 KBI_Kilometerstand "Fehler wird ausgegeben, falls Kilometerstand nicht restaurierbar
";
CM_ SG_ 1714 UH_Monat "0x0D, 0xF =  Werte ungültig
0x0E = reserviert (nur VW)";
CM_ SG_ 1714 UH_Tag "0x0: reserviert bei VW";
CM_ SG_ 1714 UH_Stunde "0x18 - 0x1F = Werte ungültig";
CM_ SG_ 1714 UH_Minute "0x3C- 0x3f = Werte ungültig";
CM_ SG_ 1714 UH_Sekunde "0x3C- 0x3f = Werte ungültig";
CM_ SG_ 1714 Vehicle_Driving_Cycle "Optimierung der Inbetriebnahme von Steuergeräten in einem Teilverbau in der Produktion.
Siehe VW80114. Signal bildet (durch eine Gateway-Funktion) den Inhalt des Signals OBD_Driving_Cycle ab.";
CM_ SG_ 1714 Uhrzeit_01_alt "
";
CM_ BO_ 1520 "ab MQB nach abgestimmten FLH Dimmung";
CM_ SG_ 1520 DI_KL_58xd "Klemme 58xd Display- und Funktionsbeleuchtung
Mit der Klemme 58xd wird die Helligkeit der Display- und der Funktionsbeleuchtungen der Schalter gesteuert.
Im Detail beschrieben im 'Funktionslastenheft Dimmung MQB'.";
CM_ SG_ 1520 DI_KL_58xs "Suchbeleuchtung Schalter
EIN-AUS-Schaltalgorithmus der allgemeinen Schaltersuchbeleuchtung. 
Im Detail beschrieben im 'Funktionslastenheft Dimmung MQB'.
";
CM_ SG_ 1520 DI_Display_Nachtdesign "Für Displays sind oft  automatische Umschaltungen von Tag-/Nachtdesign vorgesehen.
Es gibt jedoch Zustände, an denen auch tagsüber das Abblendlicht eingeschaltet ist.
z.B. Dauerfahrlicht, Geschwindigkeitsabhängiges 'Licht-An-Bei-Autobahn', 'Regenlicht',";
CM_ SG_ 1520 DI_KL_58xt "Timergesteuerte Suchbeleuchtung
Der EIN-AUS-Schaltalgorithmus für die vor- und nachlaufende Schaltersuchbeleuchtungen beim Ein- & Aussteigen; z.B.: Start/Stop-Taster.
Im Detail beschrieben im 'Funktionslastenheft Dimmung MQB'.";
CM_ SG_ 1520 DI_Fotosensor "Helligkeitswert Fotosensor
Für die Dimmung relevanter Wert zur Sensierung der Umgebungshelligkeit
Im Detail beschrieben im 'Funktionslastenheft Dimmung MQB'.";
CM_ SG_ 1520 BCM1_Stellgroesse_Kl_58s "Rohwert Dimmpoti";
CM_ BO_ 1603 "ab MQB mit 8 Byte";
CM_ SG_ 1603 KBI_Einheit_Datum "Anzeigevariante des Datums";
CM_ SG_ 1603 KBI_Einheit_Druck "Einheit des Druckes";
CM_ SG_ 1603 KBI_Einheit_Streckenanz "Einheit der Streckenanzeige";
CM_ SG_ 1603 KBI_MFA_v_Einheit_02 "Einheit der Geschwindigkeit, die vom Fahrer im Car-Menü gewählt wurde. Veränderliche Grösse, im Gegensatz zur Einheit des Tachokranzes.

Redundant in der Einheiten_01 Botschaft definiert, um Konsistenz zur BAP-Festlegung zu haben.";
CM_ SG_ 1603 KBI_Einheit_Temp "Einheit der Temperatur";
CM_ SG_ 1603 KBI_Einheit_Uhrzeit "Anzeigevariante der Uhrzeit";
CM_ SG_ 1603 KBI_Einheit_Verbrauch "Einheit der Verbrauchs";
CM_ SG_ 1603 KBI_Einheit_Volumen "Einheit des Volumens";
CM_ SG_ 1603 KBI_Einheit_Verbrauch_elektr "Einheit elektrischer Verbrauch";
CM_ SG_ 1603 KBI_Einheit_Sprache "Siehe BAP-Datenfestlegung UnitMaster";
CM_ SG_ 1603 KBI_Einheit_Verbrauch_Gas "Unterscheidung zwischen M3/h und kg/h für Komfortverbrauchsberechnung.";
CM_ SG_ 1603 KBI_Einheit_Masse "Einheit der Masse (Verwendung z.B. ASTA)";
CM_ BO_ 260 "ab MQB mit CRC-8";
CM_ SG_ 260 EPB_01_CRC "Für MLB:
'Berechnung siehe Lastenheft 'Kommunikationsabsicherung für FlexRay und CAN''

Ab MQB und MLBevo:
'Berechnung siehe Lastenheft 'End-to-End Kommunikationsabsicherung''

Endwerte siehe Begleitdokument 'S-PDU Kennungsfolgen'";
CM_ SG_ 260 EPB_QBit_Laengsbeschleunigung "Mitteilung z.Zt. für ACC, um unter bestimmten Zuständen mitzuteilen, daß Längsbeschleunigung temporär ungültig ist. Bsp.: Selbsttest Längsbeschleunigungssensor.";
CM_ SG_ 260 EPB_Freig_Verzoeg_Anf "Verzögerungsanforderung	";
CM_ SG_ 260 EPB_Verzoeg_Anf "Steuerungsanforderung an andere Systeme (z.B. ESP), um während der Fahrt, durch den Handbremsschalter ausgelöst, zu bremsen (ECD-Funktion)";
CM_ SG_ 260 EPB_Pedalweg_Kuppl "Signal entspricht Tastverhältnis des PWM. Gesamtweg Kupplungspedal 10% bis 90%, damit zu erwartende Werte 25 bis 225. 25 bei Kupplungspedal nicht getreten, 225 bei Kupplungspedal voll durchgetreten.
2% Toleranz wird im Wertebereich ermöglicht (8%-92%).
";
CM_ SG_ 260 EPB_DAA_Randbed_erf "Die Randbedingungen zum automatischen Öffnen der EPB (Funktion DAA) sind erfüllt und ein Betätigen des Fahrpedals führt zum Öffnen der EPB.";
CM_ SG_ 260 EPB_Fehlerstatus "PAG/VW526: Werte 1 und 2 werden nur bei PAG und VW526 verwendet. Genauere Informationen bitte in den Fachabteilungen erfragen!";
CM_ SG_ 260 EPB_Schalterposition "Spiegelt die Schalterstellung wieder.

0x3 = Schalterfehler ";
CM_ SG_ 260 EPB_Spannkraft "Erzeugte Spannkraft. Bezieht sich auf die Aktuatoren.

MQB: Spannkraftwerte entsprechen nicht den tatsächlichen Spannkräften. Genauere Informationen bitte in der Fachabteilung erfragen! ";
CM_ SG_ 260 EPB_Status "Gibt den Zustand der EPB-Aktuatoren an.

Nur VW526/PAG E2: Wert 0x3 bedeutet 'unbekannt'

";
CM_ SG_ 257 ESP_02_CRC "Für MLB:
'Berechnung siehe Lastenheft 'Kommunikationsabsicherung für FlexRay und CAN''

Ab MQB und MLBevo:
'Berechnung siehe Lastenheft 'End-to-End Kommunikationsabsicherung''

Endwerte siehe Begleitdokument 'S-PDU Kennungsfolgen'";
CM_ SG_ 257 ESP_QBit_Gierrate "QBit der Gierrate. Gesetzt bei Ersatzwert, Init oder Fehler. 
";
CM_ SG_ 257 ESP_QBit_Laengsbeschl "QBit der Längsbeschleunigung. Gesetzt bei Ersatzwert, Init oder Fehler. 
";
CM_ SG_ 257 ESP_QBit_Querb "QBit der Querbeschleunigung. Gesetzt bei Ersatzwert, Init oder Fehler. ";
CM_ SG_ 257 ESP_Stillstandsflag "Bei RB-Projekten wird das Stillstandsflag gesetzt, wenn der absolute Stillstand der Raddrehzahlsensoren erkannt wurde, d.h. kein Zahn bewegt sich mehr. Dieses Bit wird bspw. im MOST für TV-Tuner-Abschaltung Australien verwendet, d.h. leichte Erschütterung";
CM_ SG_ 257 ESP_Querbeschleunigung "Beschleunigungswert in y-Achse

MLB: Gemessener Wert
0xFF = Fehler (wie bereits im Wertebereich spezifizert)
Bei ESP-Abschaltung durch modellgestützte Überwachung wird das Signal weiterhin ausgegeben.
Im AU64x und AU57x erfolgt die Bereitstellung der";
CM_ SG_ 257 ESP_Laengsbeschl "Beschleunigungswert in x-Achse

MLB: Im AU64x und AU57x erfolgt die Bereitstellung der Sensorwerte durch SARA-SG! Im AU64x und AU57x wird bei ESP-Abschaltung durch modellgestützte Überwachung das Signal weiterhin ausgegeben.

MQB: Sensorrohwert Längsb";
CM_ SG_ 257 ESC_Motorstartverzoegerung "Mit dem Signal 'Motorstartverzögerung' wird den aktiven Teilnehmern ermöglicht, einen Motorstart durch die Start-Stop-Funktion zu verzögern.";
CM_ SG_ 257 ESC_SeitenwindAssistent_Eingriff "Mit diesem Statusbit wird eine aktive Regelung durch den Seitenwindassistenten signalisiert.";
CM_ SG_ 257 ESP_Anschleppstart_Freigabe "Bilden einer Schleppstartfreigabe aus Fahrdynamiksicht. Schleppstartabbruch bei kritischer Fahrzeugstabilität";
CM_ SG_ 257 ESP_QBit_Anf_Vert_Wank "QBit der Wankmomentenverteilung. Gesetzt bei Ersatzwert, Init oder Fehler.";
CM_ SG_ 257 ESP_Gierrate "Winkelgeschwindigkeit um die z-Achse, ESP_VZ_Gierrate & ESP_QBit_Gierrate beachten !!!

MLB: gemessener Wert
tatsächliche Auflösung Bosch ESP: 0,27 Grad/s

Ab AU64x Auflösung wie die tatsächliche Skalierung 0,01. Im AU64x und AU57x wird bei ESP-Absch";
CM_ SG_ 257 ESP_VZ_Gierrate "Vorzeichen der Gierrate";
CM_ SG_ 257 ESP_Notbremsanzeige "ABS/ASR oder ESP hat Notbremssituation erkannt.
Weiterführende Informationen im Lastenheft spezifiziert und in der entsprechenden Fachabteilung zu erfragen.

";
CM_ SG_ 257 ESP_SpannungsAnf "Die Rekuperation kann mit der Anforderung einer höheren Spannung eingeschränkt werden.";
CM_ SG_ 257 ESP_PLA_Abbruch "Wenn der Bremseingriff abgebrochen wurde, wird in diesem Signal der Grund des Abbruchs dargestellt.
Dies ist nur gültig, wenn der Status ESP_Status_ESP_PLA = '0xA' ist.";
CM_ SG_ 257 ESP_Status_ESP_PLA "Zustand der Statusmaschine der Bremse für die korrespondierende Statusmaschine in dem PLA-SG";
BA_DEF_  "DBName" STRING ;
BA_DEF_  "GenNWMApBusSleep" STRING ;
BA_DEF_  "GenNWMApCanNormal" STRING ;
BA_DEF_  "GenNWMApCanOff" STRING ;
BA_DEF_  "GenNWMApCanOn" STRING ;
BA_DEF_  "GenNWMApCanSleep" STRING ;
BA_DEF_  "GenNWMApCanWakeUp" STRING ;
BA_DEF_  "GenNWMGotoMode_Awake" STRING ;
BA_DEF_  "GenNWMGotoMode_BusSleep" STRING ;
BA_DEF_  "GenNWMSleepTime" INT 0 1000000;
BA_DEF_  "GenNWMTalkNM" STRING ;
BA_DEF_  "Manufacturer" STRING ;
BA_DEF_  "NmhBaseAddress" HEX 0 536870911;
BA_DEF_  "NmhMessageCount" INT 0 256;
BA_DEF_  "NmType" STRING ;
BA_DEF_  "VAGTP20_SetupMessageCount" INT 0 255;
BA_DEF_  "VAGTP20_SetupStartAddress" HEX 0 2047;
BA_DEF_  "VersionDay" INT 1 31;
BA_DEF_  "VersionMonth" INT 1 12;
BA_DEF_  "VersionWeek" INT 1 52;
BA_DEF_  "VersionYear" INT 0 99;
BA_DEF_  "VersionNumber" INT 0 65535;
BA_DEF_  "Baudrate" INT 0 1000000;
BA_DEF_  "SamplePointMin" INT 1 100;
BA_DEF_  "SamplePointMax" INT 1 100;
BA_DEF_  "SyncJumpWidthMin" INT 1 4;
BA_DEF_  "SyncJumpWidthMax" INT 1 4;
BA_DEF_  "NmhTimeoutTimer" INT 0 65535;
BA_DEF_  "NmhWaitBusSleepTimer" INT 0 65535;
BA_DEF_  "NmhPrepareBusSleepTimer" INT 0 65535;
BA_DEF_  "NmhLongTimer" INT 0 65535;
BA_DEF_  "NmhNStart" INT 0 255;
BA_DEF_ BU_  "GenNodAutoGenDsp" ENUM  "No","Yes";
BA_DEF_ BU_  "GenNodAutoGenSnd" ENUM  "No","Yes";
BA_DEF_ BU_  "GenNodSleepTime" INT 0 1000000;
BA_DEF_ BU_  "ILUsed" ENUM  "No","Yes";
BA_DEF_ BU_  "ECUVariantDefault" ENUM  "No","Yes";
BA_DEF_ BU_  "ECUVariantGroup" STRING ;
BA_DEF_ BU_  "NodeLayerModules" STRING ;
BA_DEF_ BU_  "NmhNode" ENUM  "No","Yes";
BA_DEF_ BU_  "NmNode" ENUM  "No","Yes";
BA_DEF_ BO_  "DiagRequest" ENUM  "No","Yes";
BA_DEF_ BO_  "DiagResponse" ENUM  "No","Yes";
BA_DEF_ BO_  "DiagState" ENUM  "No","Yes";
BA_DEF_ BO_  "GenMsgChkConstant" HEX 0 4095;
BA_DEF_ BO_  "GenMsgCycleTime" INT 0 65535;
BA_DEF_ BO_  "GenMsgCycleTimeFast" INT 0 65535;
BA_DEF_ BO_  "GenMsgDelayTime" INT 0 100000;
BA_DEF_ BO_  "GenMsgILSupport" ENUM  "No","Yes";
BA_DEF_ BO_  "GenMsgNrOfRepetition" INT 0 100;
BA_DEF_ BO_  "GenMsgPDUConstants" STRING ;
BA_DEF_ BO_  "GenMsgSendType" ENUM  "Cyclic","not_used","not_used","not_used","not_used","not_used","not_used","IfActive","NoMsgSendType";
BA_DEF_ BO_  "GenMsgStartDelayTime" INT 0 100000;
BA_DEF_ BO_  "NmMessage" ENUM  "No","Yes";
BA_DEF_ BO_  "NmhMessage" ENUM  "No","Yes";
BA_DEF_ BO_  "MsgType" ENUM  "Application","NM ","NMH","TP2.0","ISO-TP ","BAP","EID","KS";
BA_DEF_ BO_  "VAGTP20_API" HEX 0 255;
BA_DEF_ BO_  "VAGTP20_DynConnection" ENUM  "No","Yes";
BA_DEF_ BO_  "VAGTP20_DynSetup" ENUM  "No","Yes";
BA_DEF_ BO_  "VAGTP20_StatConnection" ENUM  "No","Yes";
BA_DEF_ SG_  "GenSigActiveRepetitions" INT -2147483648 2147483647;
BA_DEF_ SG_  "GenSigInactiveValue" INT -2147483648 2147483647;
BA_DEF_ SG_  "GenSigSendType" ENUM  "Cyclic","OnWrite","OnWriteWithRepetition","OnChange","OnChangeWithRepetition","IfActive","IfActiveWithRepetition","NoSigSendType","OnChangeAndIfActive","OnChangeAndIfActiveWithRepetition";
BA_DEF_ SG_  "GenSigStartValue" INT -2147483648 2147483647;
BA_DEF_ SG_  "NWM-WakeupAllowed" ENUM  "No","Yes";
BA_DEF_ SG_  "GenSigFuncType" ENUM  "NoFunction","MsgCounter","CRC-8","XOR","XOR-2","DatedBit","SW-Kl15","CHK","Constant","Protocol","CRC-8-SAE_J1850";
BA_DEF_ SG_  "GenSigSwitchedByIgnition" ENUM  "No","Yes";
BA_DEF_ SG_  "Fehlerwert" HEX 0 2147483647;
BA_DEF_ SG_  "GenSigMissingSourceValue" HEX 0 2147483647;
BA_DEF_REL_ BU_SG_REL_  "GenSigTimeoutTime" INT 0 65535;
BA_DEF_DEF_  "DBName" "";
BA_DEF_DEF_  "GenNWMApBusSleep" "";
BA_DEF_DEF_  "GenNWMApCanNormal" "";
BA_DEF_DEF_  "GenNWMApCanOff" "";
BA_DEF_DEF_  "GenNWMApCanOn" "";
BA_DEF_DEF_  "GenNWMApCanSleep" "";
BA_DEF_DEF_  "GenNWMApCanWakeUp" "";
BA_DEF_DEF_  "GenNWMGotoMode_Awake" "";
BA_DEF_DEF_  "GenNWMGotoMode_BusSleep" "";
BA_DEF_DEF_  "GenNWMSleepTime" 0;
BA_DEF_DEF_  "GenNWMTalkNM" "";
BA_DEF_DEF_  "Manufacturer" "";
BA_DEF_DEF_  "NmhBaseAddress" 0;
BA_DEF_DEF_  "NmhMessageCount" 1;
BA_DEF_DEF_  "NmType" "None";
BA_DEF_DEF_  "VAGTP20_SetupMessageCount" 0;
BA_DEF_DEF_  "VAGTP20_SetupStartAddress" 0;
BA_DEF_DEF_  "VersionDay" 25;
BA_DEF_DEF_  "VersionMonth" 11;
BA_DEF_DEF_  "VersionWeek" 48;
BA_DEF_DEF_  "VersionYear" 14;
BA_DEF_DEF_  "VersionNumber" 0;
BA_DEF_DEF_  "Baudrate" 0;
BA_DEF_DEF_  "SamplePointMin" 1;
BA_DEF_DEF_  "SamplePointMax" 1;
BA_DEF_DEF_  "SyncJumpWidthMin" 1;
BA_DEF_DEF_  "SyncJumpWidthMax" 1;
BA_DEF_DEF_  "NmhTimeoutTimer" 0;
BA_DEF_DEF_  "NmhWaitBusSleepTimer" 0;
BA_DEF_DEF_  "NmhPrepareBusSleepTimer" 0;
BA_DEF_DEF_  "NmhLongTimer" 0;
BA_DEF_DEF_  "NmhNStart" 0;
BA_DEF_DEF_  "GenNodAutoGenDsp" "Yes";
BA_DEF_DEF_  "GenNodAutoGenSnd" "Yes";
BA_DEF_DEF_  "GenNodSleepTime" 0;
BA_DEF_DEF_  "ILUsed" "Yes";
BA_DEF_DEF_  "ECUVariantDefault" "Yes";
BA_DEF_DEF_  "ECUVariantGroup" "";
BA_DEF_DEF_  "NodeLayerModules" "";
BA_DEF_DEF_  "NmhNode" "Yes";
BA_DEF_DEF_  "NmNode" "No";
BA_DEF_DEF_REL_ "GenSigTimeoutTime" 0;
BA_DEF_DEF_  "DiagRequest" "No";
BA_DEF_DEF_  "DiagResponse" "No";
BA_DEF_DEF_  "DiagState" "No";
BA_DEF_DEF_  "GenMsgChkConstant" 0;
BA_DEF_DEF_  "GenMsgCycleTime" 0;
BA_DEF_DEF_  "GenMsgCycleTimeFast" 0;
BA_DEF_DEF_  "GenMsgDelayTime" 0;
BA_DEF_DEF_  "GenMsgILSupport" "No";
BA_DEF_DEF_  "GenMsgNrOfRepetition" 0;
BA_DEF_DEF_  "GenMsgPDUConstants" "";
BA_DEF_DEF_  "GenMsgSendType" "NoMsgSendType";
BA_DEF_DEF_  "GenMsgStartDelayTime" 0;
BA_DEF_DEF_  "NmMessage" "No";
BA_DEF_DEF_  "NmhMessage" "No";
BA_DEF_DEF_  "MsgType" "Application";
BA_DEF_DEF_  "VAGTP20_API" 0;
BA_DEF_DEF_  "VAGTP20_DynConnection" "No";
BA_DEF_DEF_  "VAGTP20_DynSetup" "No";
BA_DEF_DEF_  "VAGTP20_StatConnection" "No";
BA_DEF_DEF_  "GenSigActiveRepetitions" 0;
BA_DEF_DEF_  "GenSigInactiveValue" 0;
BA_DEF_DEF_  "GenSigSendType" "NoSigSendType";
BA_DEF_DEF_  "GenSigStartValue" 0;
BA_DEF_DEF_  "NWM-WakeupAllowed" "No";
BA_DEF_DEF_  "GenSigFuncType" "NoFunction";
BA_DEF_DEF_  "GenSigSwitchedByIgnition" "Yes";
BA_DEF_DEF_  "Fehlerwert" 0;
BA_DEF_DEF_  "GenSigMissingSourceValue" 0;
BA_ "NmhNStart" 20;
BA_ "NmhLongTimer" 200;
BA_ "NmhPrepareBusSleepTimer" 500;
BA_ "NmhWaitBusSleepTimer" 750;
BA_ "NmhTimeoutTimer" 1000;
BA_ "SyncJumpWidthMax" 4;
BA_ "SyncJumpWidthMin" 2;
BA_ "SamplePointMax" 84;
BA_ "SamplePointMin" 80;
BA_ "Baudrate" 500000;
BA_ "VersionNumber" 14;
BA_ "VAGTP20_SetupStartAddress" 512;
BA_ "VAGTP20_SetupMessageCount" 128;
BA_ "NmType" "NM-High";
BA_ "NmhMessageCount" 256;
BA_ "NmhBaseAddress" 452984832;
BA_ "Manufacturer" "VAG";
BA_ "GenNWMTalkNM" "Nmh_ReqNetOn()";
BA_ "GenNWMSleepTime" 4000;
BA_ "GenNWMGotoMode_BusSleep" "Nmh_ReqNetOff()";
BA_ "GenNWMGotoMode_Awake" "Nmh_ReqNetOn()";
BA_ "GenNWMApCanWakeUp" "apCanWakeUp()";
BA_ "GenNWMApCanSleep" "apCanSleep()";
BA_ "GenNWMApCanOn" "NMIndnetOn()";
BA_ "GenNWMApCanOff" "NMIndnetOff()";
BA_ "GenNWMApCanNormal" "apCanNormal()";
BA_ "GenNWMApBusSleep" "NMIndNetSDN()";
BA_ "DBName" "MQB_ECAN";
BA_ "NmhNode" BU_ Frontradar 0;
BA_ "ECUVariantGroup" BU_ Frontradar "ACC";
BA_ "GenNodSleepTime" BU_ Frontradar 4000;
BA_ "NmhNode" BU_ Frontsensorik 0;
BA_ "ECUVariantGroup" BU_ Frontsensorik "Frontsensorik";
BA_ "GenNodSleepTime" BU_ Frontsensorik 4000;
BA_ "GenMsgSendType" BO_ 780 0;
BA_ "GenMsgPDUConstants" BO_ 780 "0x0f,0x0f,0x0f,0x0f,0x0f,0x0f,0x0f,0x0f,0x0f,0x0f,0x0f,0x0f,0x0f,0x0f,0x0f,0x0f";
BA_ "GenMsgILSupport" BO_ 780 1;
BA_ "GenMsgCycleTime" BO_ 780 60;
BA_ "GenMsgChkConstant" BO_ 780 15;
BA_ "GenMsgSendType" BO_ 804 0;
BA_ "GenMsgPDUConstants" BO_ 804 "0x27,0x27,0x27,0x27,0x27,0x27,0x27,0x27,0x27,0x27,0x27,0x27,0x27,0x27,0x27,0x27";
BA_ "GenMsgILSupport" BO_ 804 1;
BA_ "GenMsgCycleTime" BO_ 804 60;
BA_ "GenMsgChkConstant" BO_ 804 39;
BA_ "GenMsgSendType" BO_ 290 0;
BA_ "GenMsgPDUConstants" BO_ 290 "0x37,0x7d,0xf3,0xa9,0x18,0x46,0x6d,0x4d,0x3d,0x71,0x92,0x9c,0xe5,0x32,0x10,0xb9";
BA_ "GenMsgILSupport" BO_ 290 1;
BA_ "GenMsgCycleTime" BO_ 290 20;
BA_ "GenMsgSendType" BO_ 302 0;
BA_ "GenMsgPDUConstants" BO_ 302 "0xf8,0xe5,0x97,0xc9,0xd6,0x07,0x47,0x21,0x66,0xdd,0xcf,0x6f,0xa1,0x94,0x74,0x63";
BA_ "GenMsgILSupport" BO_ 302 1;
BA_ "GenMsgCycleTime" BO_ 302 20;
BA_ "GenMsgSendType" BO_ 279 0;
BA_ "GenMsgPDUConstants" BO_ 279 "0x16,0x16,0x16,0x16,0x16,0x16,0x16,0x16,0x16,0x16,0x16,0x16,0x16,0x16,0x16,0x16";
BA_ "GenMsgILSupport" BO_ 279 1;
BA_ "GenMsgCycleTime" BO_ 279 20;
BA_ "GenMsgChkConstant" BO_ 279 22;
BA_ "GenMsgSendType" BO_ 679 0;
BA_ "GenMsgILSupport" BO_ 679 1;
BA_ "GenMsgCycleTime" BO_ 679 60;
BA_ "GenMsgSendType" BO_ 681 0;
BA_ "GenMsgILSupport" BO_ 681 1;
BA_ "GenMsgDelayTime" BO_ 681 40;
BA_ "GenMsgCycleTime" BO_ 681 200;
BA_ "GenMsgSendType" BO_ 2527679682 0;
BA_ "GenMsgILSupport" BO_ 2527679682 1;
BA_ "GenMsgDelayTime" BO_ 2527679682 100;
BA_ "GenMsgCycleTime" BO_ 2527679682 2000;
BA_ "GenMsgSendType" BO_ 64 0;
BA_ "GenMsgPDUConstants" BO_ 64 "0x40,0x40,0x40,0x40,0x40,0x40,0x40,0x40,0x40,0x40,0x40,0x40,0x40,0x40,0x40,0x40";
BA_ "GenMsgNrOfRepetition" BO_ 64 5;
BA_ "GenMsgILSupport" BO_ 64 1;
BA_ "GenMsgDelayTime" BO_ 64 10;
BA_ "GenMsgCycleTimeFast" BO_ 64 10;
BA_ "GenMsgCycleTime" BO_ 64 50;
BA_ "GenMsgChkConstant" BO_ 64 64;
BA_ "GenMsgSendType" BO_ 1312 0;
BA_ "GenMsgPDUConstants" BO_ 1312 "0x44,0x44,0x44,0x44,0x44,0x44,0x44,0x44,0x44,0x44,0x44,0x44,0x44,0x44,0x44,0x44";
BA_ "GenMsgILSupport" BO_ 1312 1;
BA_ "GenMsgDelayTime" BO_ 1312 20;
BA_ "GenMsgCycleTime" BO_ 1312 200;
BA_ "GenMsgChkConstant" BO_ 1312 68;
BA_ "GenMsgSendType" BO_ 897 0;
BA_ "GenMsgILSupport" BO_ 897 1;
BA_ "GenMsgCycleTime" BO_ 897 80;
BA_ "GenMsgSendType" BO_ 898 0;
BA_ "GenMsgILSupport" BO_ 898 1;
BA_ "GenMsgCycleTime" BO_ 898 80;
BA_ "GenMsgSendType" BO_ 927 0;
BA_ "GenMsgILSupport" BO_ 927 1;
BA_ "GenMsgCycleTime" BO_ 927 80;
BA_ "GenMsgSendType" BO_ 896 0;
BA_ "GenMsgPDUConstants" BO_ 896 "0x13,0x13,0x13,0x13,0x13,0x13,0x13,0x13,0x13,0x13,0x13,0x13,0x13,0x13,0x13,0x13";
BA_ "GenMsgILSupport" BO_ 896 1;
BA_ "GenMsgCycleTimeFast" BO_ 896 20;
BA_ "GenMsgCycleTime" BO_ 896 80;
BA_ "GenMsgChkConstant" BO_ 896 19;
BA_ "MsgType" BO_ 2536703232 5;
BA_ "GenMsgSendType" BO_ 2536703232 7;
BA_ "GenMsgCycleTimeFast" BO_ 2536703232 80;
BA_ "MsgType" BO_ 2536703248 5;
BA_ "GenMsgSendType" BO_ 2536703248 7;
BA_ "GenMsgCycleTimeFast" BO_ 2536703248 50;
BA_ "GenMsgCycleTime" BO_ 2536703248 1000;
BA_ "MsgType" BO_ 2536708864 5;
BA_ "GenMsgSendType" BO_ 2536708864 7;
BA_ "GenMsgCycleTimeFast" BO_ 2536708864 80;
BA_ "MsgType" BO_ 2536708865 5;
BA_ "GenMsgSendType" BO_ 2536708865 7;
BA_ "GenMsgCycleTimeFast" BO_ 2536708865 80;
BA_ "MsgType" BO_ 2536708880 5;
BA_ "GenMsgSendType" BO_ 2536708880 7;
BA_ "GenMsgCycleTimeFast" BO_ 2536708880 50;
BA_ "GenMsgCycleTime" BO_ 2536708880 1000;
BA_ "MsgType" BO_ 2536767264 5;
BA_ "MsgType" BO_ 2536767280 5;
BA_ "MsgType" BO_ 2536708352 5;
BA_ "GenMsgSendType" BO_ 2536708352 7;
BA_ "GenMsgCycleTimeFast" BO_ 2536708352 80;
BA_ "MsgType" BO_ 2536708353 5;
BA_ "GenMsgSendType" BO_ 2536708353 7;
BA_ "GenMsgCycleTimeFast" BO_ 2536708353 80;
BA_ "MsgType" BO_ 2536708368 5;
BA_ "GenMsgSendType" BO_ 2536708368 7;
BA_ "GenMsgCycleTimeFast" BO_ 2536708368 50;
BA_ "GenMsgCycleTime" BO_ 2536708368 1000;
BA_ "MsgType" BO_ 2536716800 5;
BA_ "GenMsgSendType" BO_ 2536716800 7;
BA_ "GenMsgCycleTimeFast" BO_ 2536716800 80;
BA_ "MsgType" BO_ 2536716801 5;
BA_ "GenMsgSendType" BO_ 2536716801 7;
BA_ "GenMsgCycleTimeFast" BO_ 2536716801 80;
BA_ "MsgType" BO_ 2536716816 5;
BA_ "GenMsgSendType" BO_ 2536716816 7;
BA_ "GenMsgCycleTimeFast" BO_ 2536716816 50;
BA_ "GenMsgCycleTime" BO_ 2536716816 1000;
BA_ "MsgType" BO_ 2536703744 5;
BA_ "GenMsgSendType" BO_ 2536703744 7;
BA_ "GenMsgCycleTimeFast" BO_ 2536703744 80;
BA_ "MsgType" BO_ 2536703745 5;
BA_ "GenMsgSendType" BO_ 2536703745 7;
BA_ "GenMsgCycleTimeFast" BO_ 2536703745 80;
BA_ "MsgType" BO_ 2536703760 5;
BA_ "GenMsgSendType" BO_ 2536703760 7;
BA_ "GenMsgCycleTimeFast" BO_ 2536703760 50;
BA_ "GenMsgCycleTime" BO_ 2536703760 1000;
BA_ "MsgType" BO_ 2536708608 5;
BA_ "GenMsgSendType" BO_ 2536708608 7;
BA_ "GenMsgCycleTimeFast" BO_ 2536708608 80;
BA_ "MsgType" BO_ 2536708609 5;
BA_ "GenMsgSendType" BO_ 2536708609 7;
BA_ "GenMsgCycleTimeFast" BO_ 2536708609 80;
BA_ "MsgType" BO_ 2536708624 5;
BA_ "GenMsgSendType" BO_ 2536708624 7;
BA_ "GenMsgCycleTimeFast" BO_ 2536708624 50;
BA_ "GenMsgCycleTime" BO_ 2536708624 1000;
BA_ "MsgType" BO_ 2536710400 5;
BA_ "GenMsgSendType" BO_ 2536710400 7;
BA_ "GenMsgCycleTimeFast" BO_ 2536710400 80;
BA_ "MsgType" BO_ 2536710401 5;
BA_ "GenMsgSendType" BO_ 2536710401 7;
BA_ "GenMsgCycleTimeFast" BO_ 2536710401 80;
BA_ "MsgType" BO_ 2536710402 5;
BA_ "GenMsgSendType" BO_ 2536710402 7;
BA_ "GenMsgCycleTimeFast" BO_ 2536710402 80;
BA_ "MsgType" BO_ 2536710416 5;
BA_ "GenMsgSendType" BO_ 2536710416 7;
BA_ "GenMsgCycleTimeFast" BO_ 2536710416 50;
BA_ "GenMsgCycleTime" BO_ 2536710416 1000;
BA_ "GenMsgSendType" BO_ 870 0;
BA_ "GenMsgNrOfRepetition" BO_ 870 5;
BA_ "GenMsgILSupport" BO_ 870 1;
BA_ "GenMsgDelayTime" BO_ 870 10;
BA_ "GenMsgCycleTimeFast" BO_ 870 50;
BA_ "GenMsgCycleTime" BO_ 870 1000;
BA_ "GenMsgSendType" BO_ 806 0;
BA_ "GenMsgILSupport" BO_ 806 1;
BA_ "GenMsgCycleTime" BO_ 806 80;
BA_ "GenMsgSendType" BO_ 807 0;
BA_ "GenMsgILSupport" BO_ 807 1;
BA_ "GenMsgCycleTime" BO_ 807 80;
BA_ "GenMsgSendType" BO_ 808 0;
BA_ "GenMsgILSupport" BO_ 808 1;
BA_ "GenMsgCycleTime" BO_ 808 80;
BA_ "GenMsgSendType" BO_ 809 0;
BA_ "GenMsgILSupport" BO_ 809 1;
BA_ "GenMsgCycleTime" BO_ 809 80;
BA_ "GenMsgSendType" BO_ 1162 0;
BA_ "GenMsgILSupport" BO_ 1162 1;
BA_ "GenMsgCycleTime" BO_ 1162 100;
BA_ "MsgType" BO_ 2617162240 6;
BA_ "MsgType" BO_ 2617162241 6;
BA_ "GenMsgSendType" BO_ 901 0;
BA_ "GenMsgILSupport" BO_ 901 1;
BA_ "GenMsgDelayTime" BO_ 901 50;
BA_ "GenMsgCycleTime" BO_ 901 1000;
BA_ "GenMsgSendType" BO_ 1000 0;
BA_ "GenMsgILSupport" BO_ 1000 1;
BA_ "GenMsgDelayTime" BO_ 1000 50;
BA_ "GenMsgCycleTime" BO_ 1000 1000;
BA_ "MsgType" BO_ 2549880330 4;
BA_ "DiagRequest" BO_ 2549880330 1;
BA_ "MsgType" BO_ 2550011402 4;
BA_ "DiagResponse" BO_ 2550011402 1;
BA_ "MsgType" BO_ 2549880331 4;
BA_ "DiagRequest" BO_ 2549880331 1;
BA_ "MsgType" BO_ 2550011403 4;
BA_ "DiagResponse" BO_ 2550011403 1;
BA_ "GenMsgSendType" BO_ 1714 0;
BA_ "GenMsgILSupport" BO_ 1714 1;
BA_ "GenMsgCycleTime" BO_ 1714 1000;
BA_ "GenMsgSendType" BO_ 1520 0;
BA_ "GenMsgILSupport" BO_ 1520 1;
BA_ "GenMsgDelayTime" BO_ 1520 50;
BA_ "GenMsgCycleTime" BO_ 1520 200;
BA_ "GenMsgSendType" BO_ 1603 0;
BA_ "GenMsgILSupport" BO_ 1603 1;
BA_ "GenMsgDelayTime" BO_ 1603 100;
BA_ "GenMsgCycleTime" BO_ 1603 1000;
BA_ "GenMsgSendType" BO_ 260 0;
BA_ "GenMsgPDUConstants" BO_ 260 "0x05,0x05,0x05,0x05,0x05,0x05,0x05,0x05,0x05,0x05,0x05,0x05,0x05,0x05,0x05,0x05";
BA_ "GenMsgILSupport" BO_ 260 1;
BA_ "GenMsgCycleTime" BO_ 260 20;
BA_ "GenMsgChkConstant" BO_ 260 5;
BA_ "GenMsgSendType" BO_ 257 0;
BA_ "GenMsgPDUConstants" BO_ 257 "0xaa,0xaa,0xaa,0xaa,0xaa,0xaa,0xaa,0xaa,0xaa,0xaa,0xaa,0xaa,0xaa,0xaa,0xaa,0xaa";
BA_ "GenMsgILSupport" BO_ 257 1;
BA_ "GenMsgCycleTime" BO_ 257 20;
BA_ "GenMsgChkConstant" BO_ 257 170;
BA_ "GenSigFuncType" SG_ 780 ACC_02_CRC 2;
BA_ "GenSigSendType" SG_ 780 ACC_02_CRC 0;
BA_ "GenSigFuncType" SG_ 780 ACC_02_BZ 1;
BA_ "GenSigSendType" SG_ 780 ACC_02_BZ 0;
BA_ "GenSigStartValue" SG_ 780 ACC_Wunschgeschw_02 1023;
BA_ "GenSigSendType" SG_ 780 ACC_Wunschgeschw_02 0;
BA_ "GenSigSendType" SG_ 780 ACC_Status_Prim_Anz 0;
BA_ "GenSigSendType" SG_ 780 ACC_Abstandsindex 0;
BA_ "GenSigSendType" SG_ 780 ACC_Akustik_02 0;
BA_ "GenSigSendType" SG_ 780 ACC_Warnung_Verkehrszeichen_1 0;
BA_ "GenSigSendType" SG_ 780 ACC_Gesetzte_Zeitluecke 0;
BA_ "GenSigSendType" SG_ 780 ACC_Optischer_Fahrerhinweis 0;
BA_ "GenSigSendType" SG_ 780 ACC_Typ_Tachokranz 0;
BA_ "GenSigSendType" SG_ 780 ACC_Anzeige_Zeitluecke 0;
BA_ "GenSigSendType" SG_ 780 ACC_Tachokranz 0;
BA_ "GenSigSendType" SG_ 780 ACC_Display_Prio 0;
BA_ "GenSigSendType" SG_ 780 ACC_Relevantes_Objekt 0;
BA_ "GenSigSendType" SG_ 780 ACC_Texte_Primaeranz 0;
BA_ "GenSigSendType" SG_ 780 ACC_Wunschgeschw_erreicht 0;
BA_ "GenSigSendType" SG_ 780 ACC_Typ_Tachokranz_unten 0;
BA_ "GenSigSendType" SG_ 780 ACC_Status_Anzeige 0;
BA_ "GenSigFuncType" SG_ 804 ACC_04_CRC 2;
BA_ "GenSigSendType" SG_ 804 ACC_04_CRC 0;
BA_ "GenSigFuncType" SG_ 804 ACC_04_BZ 1;
BA_ "GenSigSendType" SG_ 804 ACC_04_BZ 0;
BA_ "GenSigSendType" SG_ 804 ACC_Texte_Sekundaeranz 0;
BA_ "GenSigSendType" SG_ 804 ACC_Texte_Zusatzanz 0;
BA_ "GenSigSendType" SG_ 804 ACC_Status_Zusatzanz 0;
BA_ "GenSigSendType" SG_ 804 ACC_Texte 0;
BA_ "GenSigSendType" SG_ 804 ACC_Texte_braking_guard 0;
BA_ "GenSigSendType" SG_ 804 ACC_Warnhinweis 0;
BA_ "GenSigStartValue" SG_ 804 ACC_Zeitluecke_Abstandswarner 63;
BA_ "GenSigSendType" SG_ 804 ACC_Zeitluecke_Abstandswarner 0;
BA_ "GenSigStartValue" SG_ 804 ACC_Abstand_Abstandswarner 511;
BA_ "GenSigSendType" SG_ 804 ACC_Abstand_Abstandswarner 0;
BA_ "GenSigSendType" SG_ 804 ACC_Tempolimit 0;
BA_ "GenSigSendType" SG_ 804 ACC_Charisma_FahrPr 0;
BA_ "GenSigSendType" SG_ 804 ACC_Charisma_Status 0;
BA_ "GenSigSendType" SG_ 804 ACC_Texte_Abstandswarner 0;
BA_ "GenSigFuncType" SG_ 290 ACC_06_CRC 2;
BA_ "GenSigSendType" SG_ 290 ACC_06_CRC 0;
BA_ "GenSigFuncType" SG_ 290 ACC_06_BZ 1;
BA_ "GenSigSendType" SG_ 290 ACC_06_BZ 0;
BA_ "GenSigSendType" SG_ 290 ACC_limitierte_Anfahrdyn 0;
BA_ "GenSigSendType" SG_ 290 ACC_nachtr_Stopp_Anf 0;
BA_ "GenSigSendType" SG_ 290 ACC_zul_Regelabw_unten 0;
BA_ "GenSigSendType" SG_ 290 ACC_StartStopp_Info 0;
BA_ "Fehlerwert" SG_ 290 ACC_Sollbeschleunigung_02 2047;
BA_ "GenSigStartValue" SG_ 290 ACC_Sollbeschleunigung_02 2046;
BA_ "GenSigSendType" SG_ 290 ACC_Sollbeschleunigung_02 0;
BA_ "GenSigSendType" SG_ 290 ACC_zul_Regelabw_oben 0;
BA_ "GenSigSendType" SG_ 290 ACC_neg_Sollbeschl_Grad_02 0;
BA_ "GenSigSendType" SG_ 290 ACC_pos_Sollbeschl_Grad_02 0;
BA_ "GenSigSendType" SG_ 290 ACC_Anfahren 0;
BA_ "GenSigSendType" SG_ 290 ACC_Anhalten 0;
BA_ "GenSigFuncType" SG_ 290 ACC_Typ 8;
BA_ "GenSigSendType" SG_ 290 ACC_Typ 0;
BA_ "GenSigSendType" SG_ 290 ACC_Status_ACC 0;
BA_ "GenSigSendType" SG_ 290 ACC_Minimale_Bremsung 0;
BA_ "GenSigFuncType" SG_ 302 ACC_07_CRC 2;
BA_ "GenSigSendType" SG_ 302 ACC_07_CRC 0;
BA_ "GenSigFuncType" SG_ 302 ACC_07_BZ 1;
BA_ "GenSigSendType" SG_ 302 ACC_07_BZ 0;
BA_ "Fehlerwert" SG_ 302 ACC_Anhalteweg 2047;
BA_ "GenSigStartValue" SG_ 302 ACC_Anhalteweg 2046;
BA_ "GenSigSendType" SG_ 302 ACC_Anhalteweg 0;
BA_ "GenSigSendType" SG_ 302 ACC_Anhalten 0;
BA_ "GenSigSendType" SG_ 302 ACC_Freilauf_Anf 0;
BA_ "GenSigSendType" SG_ 302 ACC_Freilauf_Info 0;
BA_ "GenSigSendType" SG_ 302 ACC_Anforderung_HMS 0;
BA_ "GenSigSendType" SG_ 302 ACC_Anfahren 0;
BA_ "GenSigStartValue" SG_ 302 ACC_Folgebeschl 254;
BA_ "GenSigSendType" SG_ 302 ACC_Folgebeschl 0;
BA_ "Fehlerwert" SG_ 302 ACC_Sollbeschleunigung_02 2047;
BA_ "GenSigStartValue" SG_ 302 ACC_Sollbeschleunigung_02 2046;
BA_ "GenSigSendType" SG_ 302 ACC_Sollbeschleunigung_02 0;
BA_ "GenSigFuncType" SG_ 279 ACC_10_CRC 2;
BA_ "GenSigSendType" SG_ 279 ACC_10_CRC 0;
BA_ "GenSigFuncType" SG_ 279 ACC_10_BZ 1;
BA_ "GenSigSendType" SG_ 279 ACC_10_BZ 0;
BA_ "GenSigSendType" SG_ 279 AWV1_Anf_Prefill 0;
BA_ "GenSigSendType" SG_ 279 ANB_CM_Info 0;
BA_ "GenSigSendType" SG_ 279 AWV2_Freigabe 0;
BA_ "GenSigSendType" SG_ 279 AWV1_HBA_Param 0;
BA_ "GenSigSendType" SG_ 279 AWV2_Ruckprofil 0;
BA_ "GenSigSendType" SG_ 279 AWV2_Priowarnung 0;
BA_ "GenSigSendType" SG_ 279 ANB_CM_Anforderung 0;
BA_ "GenSigSendType" SG_ 279 ANB_Info_Teilbremsung 0;
BA_ "GenSigSendType" SG_ 279 ANB_Notfallblinken 0;
BA_ "GenSigSendType" SG_ 279 ANB_Teilbremsung_Freigabe 0;
BA_ "GenSigStartValue" SG_ 279 ANB_Zielbrems_Teilbrems_Verz_Anf 834;
BA_ "GenSigSendType" SG_ 279 ANB_Zielbrems_Teilbrems_Verz_Anf 0;
BA_ "GenSigSendType" SG_ 279 ANB_Zielbremsung_Freigabe 0;
BA_ "GenSigSendType" SG_ 279 AWV_Vorstufe 0;
BA_ "GenSigSendType" SG_ 279 AWV_Halten 0;
BA_ "GenSigFuncType" SG_ 279 AWV_CityANB_Auspraegung 8;
BA_ "GenSigSendType" SG_ 279 AWV_CityANB_Auspraegung 0;
BA_ "GenSigSendType" SG_ 279 PCF_Freigabe 0;
BA_ "GenSigSendType" SG_ 279 AWV1_ECD_Anlauf 0;
BA_ "GenSigStartValue" SG_ 279 PCF_Time_to_collision 255;
BA_ "GenSigSendType" SG_ 279 PCF_Time_to_collision 0;
BA_ "GenSigStartValue" SG_ 679 ACC_Regelgeschw 1023;
BA_ "GenSigSendType" SG_ 679 ACC_Regelgeschw 0;
BA_ "GenSigSendType" SG_ 679 ACC_Einheit_maxSetzgeschw 0;
BA_ "GenSigStartValue" SG_ 679 ACC_maxSetzgeschw 511;
BA_ "GenSigSendType" SG_ 679 ACC_maxSetzgeschw 0;
BA_ "GenSigStartValue" SG_ 679 ACC_minRegelgeschw 255;
BA_ "GenSigSendType" SG_ 679 ACC_minRegelgeschw 0;
BA_ "GenSigStartValue" SG_ 679 ACC_maxRegelgeschw 255;
BA_ "GenSigSendType" SG_ 679 ACC_maxRegelgeschw 0;
BA_ "GenSigSendType" SG_ 679 ACC_Tempolimitassistent 0;
BA_ "GenSigSendType" SG_ 679 ACC_Kurvenassistent 0;
BA_ "GenSigSendType" SG_ 679 ACC_RUV 0;
BA_ "GenSigSendType" SG_ 679 ACC_Tachokranz 0;
BA_ "GenSigSendType" SG_ 679 ACC_Typ_Tachokranz_unten 0;
BA_ "GenSigSendType" SG_ 679 ACC_ENG_Texte 0;
BA_ "GenSigSendType" SG_ 681 AWV_Warnung 3;
BA_ "GenSigSendType" SG_ 681 AWV_Texte 3;
BA_ "GenSigSendType" SG_ 681 AWV_Status_Anzeige 3;
BA_ "GenSigSendType" SG_ 681 AWV_Einstellung_System_FSG 3;
BA_ "GenSigSendType" SG_ 681 AWV_Einstellung_Warnung_FSG 3;
BA_ "GenSigSendType" SG_ 681 AWV_Warnlevel 3;
BA_ "GenSigSendType" SG_ 2527679682 ACC_ASM_Ereignis 3;
BA_ "GenSigStartValue" SG_ 2527679682 ACC_ASM_Zeitstempel 255;
BA_ "GenSigSendType" SG_ 2527679682 ACC_ASM_Zeitstempel 3;
BA_ "GenSigSendType" SG_ 2527679682 ACC_ASM_Data_1 0;
BA_ "GenSigSendType" SG_ 2527679682 ACC_ASM_Data_2 0;
BA_ "GenSigSendType" SG_ 2527679682 ACC_ASM_Data_3 0;
BA_ "GenSigSendType" SG_ 2527679682 ACC_ASM_Data_4 0;
BA_ "GenSigSendType" SG_ 2527679682 ACC_ASM_Data_5 0;
BA_ "GenSigSendType" SG_ 2527679682 ACC_ASM_Data_6 0;
BA_ "GenSigFuncType" SG_ 64 Airbag_01_CRC 2;
BA_ "GenSigSendType" SG_ 64 Airbag_01_CRC 0;
BA_ "GenSigFuncType" SG_ 64 Airbag_01_BZ 1;
BA_ "GenSigSendType" SG_ 64 Airbag_01_BZ 0;
BA_ "GenSigStartValue" SG_ 64 AB_RGS_Anst 8;
BA_ "GenSigSendType" SG_ 64 AB_RGS_Anst 3;
BA_ "GenSigSendType" SG_ 64 AB_Front_Crash 4;
BA_ "GenSigSendType" SG_ 64 AB_Heck_Crash 4;
BA_ "GenSigSendType" SG_ 64 AB_SF_Crash 4;
BA_ "GenSigSendType" SG_ 64 AB_SB_Crash 4;
BA_ "GenSigSendType" SG_ 64 AB_Rollover_Crash 4;
BA_ "GenSigSendType" SG_ 64 AB_Crash_Int 4;
BA_ "GenSigStartValue" SG_ 64 AB_Lampe 1;
BA_ "GenSigSendType" SG_ 64 AB_Lampe 0;
BA_ "GenSigSendType" SG_ 64 AB_Deaktiviert 0;
BA_ "GenSigStartValue" SG_ 64 AB_VB_deaktiviert 1;
BA_ "GenSigSendType" SG_ 64 AB_VB_deaktiviert 0;
BA_ "GenSigSendType" SG_ 64 AB_Systemfehler 0;
BA_ "GenSigSendType" SG_ 64 AB_Diagnose 0;
BA_ "GenSigSendType" SG_ 64 AB_Stellgliedtest 0;
BA_ "GenSigSendType" SG_ 64 AB_Erh_Auf_VB 0;
BA_ "GenSigSendType" SG_ 64 AB_Gurtwarn_VF 0;
BA_ "GenSigSendType" SG_ 64 AB_Gurtwarn_VB 0;
BA_ "GenSigSendType" SG_ 64 AB_Anzeige_Fussg 0;
BA_ "GenSigSendType" SG_ 64 AB_Texte_AKS 0;
BA_ "GenSigStartValue" SG_ 64 AB_PAO_Leuchte_Anf 1;
BA_ "GenSigSendType" SG_ 64 AB_PAO_Leuchte_Anf 0;
BA_ "GenSigFuncType" SG_ 64 AB_MKB_gueltig 8;
BA_ "GenSigSendType" SG_ 64 AB_MKB_gueltig 0;
BA_ "GenSigSendType" SG_ 64 AB_MKB_Anforderung 4;
BA_ "GenSigSendType" SG_ 64 AB_Versorgungsspannung 0;
BA_ "Fehlerwert" SG_ 64 AB_Deaktivierung_HV 7;
BA_ "GenSigSendType" SG_ 64 AB_Deaktivierung_HV 4;
BA_ "GenSigSendType" SG_ 64 AB_EDR_Trigger 3;
BA_ "GenSigSendType" SG_ 64 SC_Masterzeit_Offset 0;
BA_ "GenSigStartValue" SG_ 64 SC_Masterzeit 127;
BA_ "GenSigSendType" SG_ 64 SC_Masterzeit 0;
BA_ "GenSigFuncType" SG_ 1312 Airbag_02_CRC 2;
BA_ "GenSigSendType" SG_ 1312 Airbag_02_CRC 0;
BA_ "GenSigFuncType" SG_ 1312 Airbag_02_BZ 1;
BA_ "GenSigSendType" SG_ 1312 Airbag_02_BZ 0;
BA_ "GenSigSendType" SG_ 1312 LoGeWa_Event_Kombiwarnung 3;
BA_ "GenSigSendType" SG_ 1312 AB_Anforderung_eCall 0;
BA_ "GenSigSendType" SG_ 1312 AB_Anprall_Seite_Beifahrer 3;
BA_ "GenSigSendType" SG_ 1312 AB_Anprall_Rollover 3;
BA_ "GenSigSendType" SG_ 1312 AB_Anprall_FGS 3;
BA_ "GenSigSendType" SG_ 1312 AB_Anprall_Front_Beifahrer 3;
BA_ "GenSigSendType" SG_ 1312 AB_Anprall_Front_Fahrer 3;
BA_ "GenSigSendType" SG_ 1312 AB_Anprall_Heck_Beifahrer 3;
BA_ "GenSigSendType" SG_ 1312 AB_Anprall_Heck_Fahrer 3;
BA_ "GenSigSendType" SG_ 1312 AB_Wickelklappung_Reihe2_MI 3;
BA_ "Fehlerwert" SG_ 1312 AB_Belegung_VB 1;
BA_ "GenSigSendType" SG_ 1312 AB_Belegung_VB 0;
BA_ "GenSigSendType" SG_ 1312 AB_Abschaltanf_SIH_BF 3;
BA_ "GenSigSendType" SG_ 1312 AB_Anprall_Seite_Fahrer 3;
BA_ "GenSigSendType" SG_ 1312 SC_PAO_Schriftzug_Anf 0;
BA_ "GenSigSendType" SG_ 1312 SC_PAO_ON_Anf 0;
BA_ "GenSigSendType" SG_ 1312 SC_PAO_OFF_Anf 0;
BA_ "Fehlerwert" SG_ 1312 AB_Crashschwere 7;
BA_ "GenSigSendType" SG_ 1312 AB_Crashschwere 3;
BA_ "GenSigSendType" SG_ 1312 AB_Anforderung_USM 0;
BA_ "GenSigStartValue" SG_ 1312 AB_Gurtschloss_FA 1;
BA_ "GenSigSendType" SG_ 1312 AB_Gurtschloss_FA 3;
BA_ "GenSigStartValue" SG_ 1312 AB_Gurtschloss_BF 1;
BA_ "GenSigSendType" SG_ 1312 AB_Gurtschloss_BF 3;
BA_ "GenSigStartValue" SG_ 1312 AB_Gurtschloss_Reihe2_FA 1;
BA_ "GenSigSendType" SG_ 1312 AB_Gurtschloss_Reihe2_FA 3;
BA_ "GenSigStartValue" SG_ 1312 AB_Gurtschloss_Reihe2_MI 1;
BA_ "GenSigSendType" SG_ 1312 AB_Gurtschloss_Reihe2_MI 3;
BA_ "GenSigStartValue" SG_ 1312 AB_Gurtschloss_Reihe2_BF 1;
BA_ "GenSigSendType" SG_ 1312 AB_Gurtschloss_Reihe2_BF 3;
BA_ "GenSigStartValue" SG_ 1312 AB_Gurtschloss_Reihe3_FA 1;
BA_ "GenSigSendType" SG_ 1312 AB_Gurtschloss_Reihe3_FA 3;
BA_ "GenSigStartValue" SG_ 1312 AB_Gurtschloss_Reihe3_MI 1;
BA_ "GenSigSendType" SG_ 1312 AB_Gurtschloss_Reihe3_MI 3;
BA_ "GenSigStartValue" SG_ 1312 AB_Gurtschloss_Reihe3_BF 1;
BA_ "GenSigSendType" SG_ 1312 AB_Gurtschloss_Reihe3_BF 3;
BA_ "Fehlerwert" SG_ 1312 AB_Sitzpos_Sens_FA 1;
BA_ "GenSigSendType" SG_ 1312 AB_Sitzpos_Sens_FA 0;
BA_ "Fehlerwert" SG_ 1312 AB_Sitzpos_Sens_BF 1;
BA_ "GenSigSendType" SG_ 1312 AB_Sitzpos_Sens_BF 0;
BA_ "GenSigSendType" SG_ 1312 AB_Wickelklappung_Reihe2_BF 3;
BA_ "GenSigSendType" SG_ 1312 AB_Wickelklappung_Reihe2_FA 3;
BA_ "GenSigStartValue" SG_ 897 US_RDir_VL 255;
BA_ "GenSigSendType" SG_ 897 US_RDir_VL 0;
BA_ "GenSigStartValue" SG_ 897 US_RDir_VLM 255;
BA_ "GenSigSendType" SG_ 897 US_RDir_VLM 0;
BA_ "GenSigStartValue" SG_ 897 US_RIndir_VLM_VL 255;
BA_ "GenSigSendType" SG_ 897 US_RIndir_VLM_VL 0;
BA_ "GenSigStartValue" SG_ 897 US_RIndir_VLM_VRM 255;
BA_ "GenSigSendType" SG_ 897 US_RIndir_VLM_VRM 0;
BA_ "GenSigStartValue" SG_ 897 US_RIndir_VL_VLM 255;
BA_ "GenSigSendType" SG_ 897 US_RIndir_VL_VLM 0;
BA_ "GenSigStartValue" SG_ 897 US_GDir_VL 15;
BA_ "GenSigSendType" SG_ 897 US_GDir_VL 0;
BA_ "GenSigStartValue" SG_ 897 US_GDir_VLM 15;
BA_ "GenSigSendType" SG_ 897 US_GDir_VLM 0;
BA_ "GenSigStartValue" SG_ 897 US_GIndir_VLM_VL 15;
BA_ "GenSigSendType" SG_ 897 US_GIndir_VLM_VL 0;
BA_ "GenSigStartValue" SG_ 897 US_GIndir_VLM_VRM 15;
BA_ "GenSigSendType" SG_ 897 US_GIndir_VLM_VRM 0;
BA_ "GenSigStartValue" SG_ 897 US_GIndir_VL_VLM 15;
BA_ "GenSigSendType" SG_ 897 US_GIndir_VL_VLM 0;
BA_ "GenSigSendType" SG_ 897 APS_01_Paketzaehler 0;
BA_ "GenSigStartValue" SG_ 898 US_RDir_VR 255;
BA_ "GenSigSendType" SG_ 898 US_RDir_VR 0;
BA_ "GenSigStartValue" SG_ 898 US_RDir_VRM 255;
BA_ "GenSigSendType" SG_ 898 US_RDir_VRM 0;
BA_ "GenSigStartValue" SG_ 898 US_RIndir_VRM_VR 255;
BA_ "GenSigSendType" SG_ 898 US_RIndir_VRM_VR 0;
BA_ "GenSigStartValue" SG_ 898 US_RIndir_VRM_VLM 255;
BA_ "GenSigSendType" SG_ 898 US_RIndir_VRM_VLM 0;
BA_ "GenSigStartValue" SG_ 898 US_RIndir_VR_VRM 255;
BA_ "GenSigSendType" SG_ 898 US_RIndir_VR_VRM 0;
BA_ "GenSigStartValue" SG_ 898 US_GDir_VR 15;
BA_ "GenSigSendType" SG_ 898 US_GDir_VR 0;
BA_ "GenSigStartValue" SG_ 898 US_GDir_VRM 15;
BA_ "GenSigSendType" SG_ 898 US_GDir_VRM 0;
BA_ "GenSigStartValue" SG_ 898 US_GIndir_VRM_VLM 15;
BA_ "GenSigSendType" SG_ 898 US_GIndir_VRM_VLM 0;
BA_ "GenSigStartValue" SG_ 898 US_GIndir_VRM_VR 15;
BA_ "GenSigSendType" SG_ 898 US_GIndir_VRM_VR 0;
BA_ "GenSigStartValue" SG_ 898 US_GIndir_VR_VRM 15;
BA_ "GenSigSendType" SG_ 898 US_GIndir_VR_VRM 0;
BA_ "GenSigSendType" SG_ 898 APS_02_Paketzaehler 0;
BA_ "GenSigStartValue" SG_ 927 US_RDir_VRS 1023;
BA_ "GenSigSendType" SG_ 927 US_RDir_VRS 0;
BA_ "GenSigStartValue" SG_ 927 US_RDir_VLS 1023;
BA_ "GenSigSendType" SG_ 927 US_RDir_VLS 0;
BA_ "GenSigStartValue" SG_ 927 US_RDir_HRS 1023;
BA_ "GenSigSendType" SG_ 927 US_RDir_HRS 0;
BA_ "GenSigStartValue" SG_ 927 US_RDir_HLS 1023;
BA_ "GenSigSendType" SG_ 927 US_RDir_HLS 0;
BA_ "Fehlerwert" SG_ 927 US_Fehler_VS 1;
BA_ "GenSigSendType" SG_ 927 US_Fehler_VS 0;
BA_ "Fehlerwert" SG_ 927 US_Fehler_HS 1;
BA_ "GenSigSendType" SG_ 927 US_Fehler_HS 0;
BA_ "GenSigSendType" SG_ 927 US_Verschmutzung_VS 0;
BA_ "GenSigSendType" SG_ 927 US_Verschmutzung_HS 0;
BA_ "GenSigSendType" SG_ 927 US_NichtVerfuegbarkeit_VS 0;
BA_ "GenSigSendType" SG_ 927 US_NichtVerfuegbarkeit_HS 0;
BA_ "GenSigSendType" SG_ 927 APS_03_Paketzaehler 0;
BA_ "GenSigFuncType" SG_ 896 US_ACC_CRC 2;
BA_ "GenSigSendType" SG_ 896 US_ACC_CRC 0;
BA_ "GenSigFuncType" SG_ 896 US_ACC_BZ 1;
BA_ "GenSigSendType" SG_ 896 US_ACC_BZ 0;
BA_ "Fehlerwert" SG_ 896 US_Sende_Modus 15;
BA_ "GenSigSendType" SG_ 896 US_Sende_Modus 0;
BA_ "GenSigSendType" SG_ 896 US_relevanter_Fehler 0;
BA_ "GenSigSendType" SG_ 896 US_relevante_Nichtverfuegbarkeit 0;
BA_ "GenSigSendType" SG_ 896 US_Freisicht_nio 0;
BA_ "GenSigSendType" SG_ 896 US_blindness_detected 0;
BA_ "Fehlerwert" SG_ 896 US_Sende_Modus_hinten 15;
BA_ "GenSigSendType" SG_ 896 US_Sende_Modus_hinten 0;
BA_ "GenSigSendType" SG_ 896 APS_Master_Sendestatus 5;
BA_ "GenSigSendType" SG_ 896 US_Freie_Weglaenge_Front_Typ 0;
BA_ "Fehlerwert" SG_ 896 US_Freie_Weglaenge_Front 511;
BA_ "GenSigStartValue" SG_ 896 US_Freie_Weglaenge_Front 510;
BA_ "GenSigSendType" SG_ 896 US_Freie_Weglaenge_Front 0;
BA_ "GenSigSwitchedByIgnition" SG_ 2536703232 BAP_ACC_ASG_01_Header 0;
BA_ "GenSigSendType" SG_ 2536703232 BAP_ACC_ASG_01_Header 3;
BA_ "GenSigSendType" SG_ 2536703248 BAP_ACC_FSG_01_Header 3;
BA_ "GenSigSwitchedByIgnition" SG_ 2536708864 BAP_AWV_ASG_01_Header 0;
BA_ "GenSigSendType" SG_ 2536708864 BAP_AWV_ASG_01_Header 3;
BA_ "GenSigSwitchedByIgnition" SG_ 2536708865 BAP_AWV_ASG_02_Header 0;
BA_ "GenSigSendType" SG_ 2536708865 BAP_AWV_ASG_02_Header 3;
BA_ "GenSigSendType" SG_ 2536708880 BAP_AWV_FSG_01_Header 3;
BA_ "GenSigSwitchedByIgnition" SG_ 2536767264 BAP_Debug_Cmd 0;
BA_ "GenSigSendType" SG_ 2536767264 BAP_Debug_Cmd 3;
BA_ "GenSigSendType" SG_ 2536767280 BAP_Debug_Data 3;
BA_ "GenSigSwitchedByIgnition" SG_ 2536708352 BAP_LDW_ASG_01_Header 0;
BA_ "GenSigSendType" SG_ 2536708352 BAP_LDW_ASG_01_Header 3;
BA_ "GenSigSwitchedByIgnition" SG_ 2536708353 BAP_LDW_ASG_02_Header 0;
BA_ "GenSigSendType" SG_ 2536708353 BAP_LDW_ASG_02_Header 3;
BA_ "GenSigSendType" SG_ 2536708368 BAP_LDW_FSG_01_Header 3;
BA_ "GenSigSwitchedByIgnition" SG_ 2536716800 BAP_PedAssist_ASG_01_Header 0;
BA_ "GenSigSendType" SG_ 2536716800 BAP_PedAssist_ASG_01_Header 3;
BA_ "GenSigSwitchedByIgnition" SG_ 2536716801 BAP_PedAssist_ASG_02_Data 0;
BA_ "GenSigSendType" SG_ 2536716801 BAP_PedAssist_ASG_02_Data 3;
BA_ "GenSigSendType" SG_ 2536716816 BAP_PedAssist_FSG_01_Header 3;
BA_ "GenSigSwitchedByIgnition" SG_ 2536703744 BAP_RDK_ASG_01_Header 0;
BA_ "GenSigSendType" SG_ 2536703744 BAP_RDK_ASG_01_Header 3;
BA_ "GenSigSwitchedByIgnition" SG_ 2536703745 BAP_RDK_ASG_02_Header 0;
BA_ "GenSigSendType" SG_ 2536703745 BAP_RDK_ASG_02_Header 3;
BA_ "GenSigSwitchedByIgnition" SG_ 2536703760 BAP_RDK_FSG_01_Header 0;
BA_ "GenSigSendType" SG_ 2536703760 BAP_RDK_FSG_01_Header 3;
BA_ "GenSigSwitchedByIgnition" SG_ 2536708608 BAP_SWA_ASG_01_Header 0;
BA_ "GenSigSendType" SG_ 2536708608 BAP_SWA_ASG_01_Header 3;
BA_ "GenSigSwitchedByIgnition" SG_ 2536708609 BAP_SWA_ASG_02_Header 0;
BA_ "GenSigSendType" SG_ 2536708609 BAP_SWA_ASG_02_Header 3;
BA_ "GenSigSendType" SG_ 2536708624 BAP_SWA_FSG_01_Header 3;
BA_ "GenSigSwitchedByIgnition" SG_ 2536710400 BAP_VZA_ASG_01_Header 0;
BA_ "GenSigSendType" SG_ 2536710400 BAP_VZA_ASG_01_Header 3;
BA_ "GenSigSwitchedByIgnition" SG_ 2536710401 BAP_VZA_ASG_02_Header 0;
BA_ "GenSigSendType" SG_ 2536710401 BAP_VZA_ASG_02_Header 3;
BA_ "GenSigSwitchedByIgnition" SG_ 2536710402 BAP_VZA_ASG_03_Header 0;
BA_ "GenSigSendType" SG_ 2536710402 BAP_VZA_ASG_03_Header 3;
BA_ "GenSigSendType" SG_ 2536710416 BAP_VZA_FSG_01_Header 3;
BA_ "GenSigSwitchedByIgnition" SG_ 870 BM_ZV_auf 0;
BA_ "GenSigSendType" SG_ 870 BM_ZV_auf 4;
BA_ "GenSigSwitchedByIgnition" SG_ 870 BM_ZV_zu 0;
BA_ "GenSigSendType" SG_ 870 BM_ZV_zu 4;
BA_ "GenSigSwitchedByIgnition" SG_ 870 BM_DWA_ein 0;
BA_ "GenSigSendType" SG_ 870 BM_DWA_ein 4;
BA_ "GenSigSwitchedByIgnition" SG_ 870 BM_DWA_Alarm 0;
BA_ "GenSigSendType" SG_ 870 BM_DWA_Alarm 4;
BA_ "GenSigSwitchedByIgnition" SG_ 870 BM_Crash 0;
BA_ "GenSigSendType" SG_ 870 BM_Crash 4;
BA_ "GenSigSwitchedByIgnition" SG_ 870 BM_Panik 0;
BA_ "GenSigSendType" SG_ 870 BM_Panik 4;
BA_ "GenSigSwitchedByIgnition" SG_ 870 BM_Not_Bremsung 0;
BA_ "GenSigSendType" SG_ 870 BM_Not_Bremsung 4;
BA_ "GenSigSwitchedByIgnition" SG_ 870 BM_GDO 0;
BA_ "GenSigSendType" SG_ 870 BM_GDO 4;
BA_ "GenSigSwitchedByIgnition" SG_ 870 BM_Warnblinken 0;
BA_ "GenSigSendType" SG_ 870 BM_Warnblinken 4;
BA_ "GenSigSwitchedByIgnition" SG_ 870 BM_Taxi_Notalarm 0;
BA_ "GenSigSendType" SG_ 870 BM_Taxi_Notalarm 4;
BA_ "GenSigSwitchedByIgnition" SG_ 870 BM_Telematik 0;
BA_ "GenSigSendType" SG_ 870 BM_Telematik 4;
BA_ "GenSigSwitchedByIgnition" SG_ 870 BM_links 0;
BA_ "GenSigSendType" SG_ 870 BM_links 4;
BA_ "GenSigSwitchedByIgnition" SG_ 870 BM_rechts 0;
BA_ "GenSigSendType" SG_ 870 BM_rechts 4;
BA_ "GenSigSwitchedByIgnition" SG_ 870 Blinken_li_Fzg_Takt 0;
BA_ "GenSigSendType" SG_ 870 Blinken_li_Fzg_Takt 4;
BA_ "GenSigSwitchedByIgnition" SG_ 870 Blinken_re_Fzg_Takt 0;
BA_ "GenSigSendType" SG_ 870 Blinken_re_Fzg_Takt 4;
BA_ "GenSigSwitchedByIgnition" SG_ 870 Blinken_li_Kombi_Takt 0;
BA_ "GenSigSendType" SG_ 870 Blinken_li_Kombi_Takt 4;
BA_ "GenSigSwitchedByIgnition" SG_ 870 Blinken_re_Kombi_Takt 0;
BA_ "GenSigSendType" SG_ 870 Blinken_re_Kombi_Takt 4;
BA_ "GenSigSwitchedByIgnition" SG_ 870 BM_NBA_n_codiert_n_aktiv 0;
BA_ "GenSigStartValue" SG_ 870 BM_NBA_n_codiert_n_aktiv 1;
BA_ "GenSigSendType" SG_ 870 BM_NBA_n_codiert_n_aktiv 3;
BA_ "GenSigSwitchedByIgnition" SG_ 870 BM_NBA_Status 0;
BA_ "GenSigSendType" SG_ 870 BM_NBA_Status 4;
BA_ "GenSigSwitchedByIgnition" SG_ 870 BM_WBT_Beleuchtung 0;
BA_ "GenSigSendType" SG_ 870 BM_WBT_Beleuchtung 3;
BA_ "GenSigSwitchedByIgnition" SG_ 870 BM_HD_Oeffnung_angelernt 0;
BA_ "GenSigSendType" SG_ 870 BM_HD_Oeffnung_angelernt 3;
BA_ "GenSigSwitchedByIgnition" SG_ 870 BM_Autobahn 0;
BA_ "GenSigSendType" SG_ 870 BM_Autobahn 4;
BA_ "GenSigSwitchedByIgnition" SG_ 870 BM_Rollenmodus_Blinken 0;
BA_ "GenSigSendType" SG_ 870 BM_Rollenmodus_Blinken 5;
BA_ "GenSigSwitchedByIgnition" SG_ 870 BM_Recas 0;
BA_ "GenSigSendType" SG_ 870 BM_Recas 5;
BA_ "GenSigSwitchedByIgnition" SG_ 870 BM_Wischblinken 0;
BA_ "GenSigSendType" SG_ 870 BM_Wischblinken 4;
BA_ "GenSigSwitchedByIgnition" SG_ 870 BM_Telematik_Abbruchgrund 0;
BA_ "GenSigSendType" SG_ 870 BM_Telematik_Abbruchgrund 4;
BA_ "GenSigStartValue" SG_ 806 BV_Linie_01_dy 2048;
BA_ "GenSigSendType" SG_ 806 BV_Linie_01_dy 0;
BA_ "GenSigSendType" SG_ 806 BV_Linie_01_Existenzmass 0;
BA_ "GenSigSendType" SG_ 806 BV_Linie_01_Farbe 0;
BA_ "GenSigStartValue" SG_ 806 BV_Linie_01_Gierw_diff 2048;
BA_ "GenSigSendType" SG_ 806 BV_Linie_01_Gierw_diff 0;
BA_ "GenSigStartValue" SG_ 806 BV_Linie_01_hor_Kruemm_Aend 2047;
BA_ "GenSigSendType" SG_ 806 BV_Linie_01_hor_Kruemm_Aend 0;
BA_ "GenSigStartValue" SG_ 806 BV_Linie_01_hor_Kruemmung 2047;
BA_ "GenSigSendType" SG_ 806 BV_Linie_01_hor_Kruemmung 0;
BA_ "GenSigSendType" SG_ 806 BV_Linie_01_Liniennummer 0;
BA_ "GenSigSendType" SG_ 806 BV_Linie_01_Typ 0;
BA_ "GenSigStartValue" SG_ 807 BV_Linie_02_dy 2048;
BA_ "GenSigSendType" SG_ 807 BV_Linie_02_dy 0;
BA_ "GenSigSendType" SG_ 807 BV_Linie_02_Existenzmass 0;
BA_ "GenSigSendType" SG_ 807 BV_Linie_02_Farbe 0;
BA_ "GenSigStartValue" SG_ 807 BV_Linie_02_Gierw_diff 2048;
BA_ "GenSigSendType" SG_ 807 BV_Linie_02_Gierw_diff 0;
BA_ "GenSigStartValue" SG_ 807 BV_Linie_02_hor_Kruemm_Aend 2047;
BA_ "GenSigSendType" SG_ 807 BV_Linie_02_hor_Kruemm_Aend 0;
BA_ "GenSigStartValue" SG_ 807 BV_Linie_02_hor_Kruemmung 2047;
BA_ "GenSigSendType" SG_ 807 BV_Linie_02_hor_Kruemmung 0;
BA_ "GenSigSendType" SG_ 807 BV_Linie_02_Liniennummer 0;
BA_ "GenSigSendType" SG_ 807 BV_Linie_02_Typ 0;
BA_ "GenSigStartValue" SG_ 808 BV_Linie_03_dy 2048;
BA_ "GenSigSendType" SG_ 808 BV_Linie_03_dy 0;
BA_ "GenSigSendType" SG_ 808 BV_Linie_03_Existenzmass 0;
BA_ "GenSigSendType" SG_ 808 BV_Linie_03_Farbe 0;
BA_ "GenSigStartValue" SG_ 808 BV_Linie_03_Gierw_diff 2048;
BA_ "GenSigSendType" SG_ 808 BV_Linie_03_Gierw_diff 0;
BA_ "GenSigStartValue" SG_ 808 BV_Linie_03_hor_Kruemm_Aend 2047;
BA_ "GenSigSendType" SG_ 808 BV_Linie_03_hor_Kruemm_Aend 0;
BA_ "GenSigStartValue" SG_ 808 BV_Linie_03_hor_Kruemmung 2047;
BA_ "GenSigSendType" SG_ 808 BV_Linie_03_hor_Kruemmung 0;
BA_ "GenSigSendType" SG_ 808 BV_Linie_03_Liniennummer 0;
BA_ "GenSigSendType" SG_ 808 BV_Linie_03_Typ 0;
BA_ "GenSigStartValue" SG_ 809 BV_Linie_04_dy 2048;
BA_ "GenSigSendType" SG_ 809 BV_Linie_04_dy 0;
BA_ "GenSigSendType" SG_ 809 BV_Linie_04_Existenzmass 0;
BA_ "GenSigSendType" SG_ 809 BV_Linie_04_Farbe 0;
BA_ "GenSigStartValue" SG_ 809 BV_Linie_04_Gierw_diff 2048;
BA_ "GenSigSendType" SG_ 809 BV_Linie_04_Gierw_diff 0;
BA_ "GenSigStartValue" SG_ 809 BV_Linie_04_hor_Kruemm_Aend 2047;
BA_ "GenSigSendType" SG_ 809 BV_Linie_04_hor_Kruemm_Aend 0;
BA_ "GenSigStartValue" SG_ 809 BV_Linie_04_hor_Kruemmung 2047;
BA_ "GenSigSendType" SG_ 809 BV_Linie_04_hor_Kruemmung 0;
BA_ "GenSigSendType" SG_ 809 BV_Linie_04_Liniennummer 0;
BA_ "GenSigSendType" SG_ 809 BV_Linie_04_Typ 0;
BA_ "GenSigSendType" SG_ 1162 BV_Linie_01_dx_Vorausschau 0;
BA_ "GenSigSendType" SG_ 1162 BV_Linie_02_dx_Vorausschau 0;
BA_ "GenSigSendType" SG_ 1162 BV_Linie_03_dx_Vorausschau 0;
BA_ "GenSigSendType" SG_ 1162 BV_Linie_04_dx_Vorausschau 0;
BA_ "GenSigSwitchedByIgnition" SG_ 2617162240 CCP_ACC_CRO_01_Data 0;
BA_ "GenSigSwitchedByIgnition" SG_ 901 CHA_Ziel_FahrPr_AGA 0;
BA_ "GenSigSendType" SG_ 901 CHA_Ziel_FahrPr_AGA 3;
BA_ "GenSigSwitchedByIgnition" SG_ 901 CHA_Ziel_FahrPr_ESP 0;
BA_ "GenSigSendType" SG_ 901 CHA_Ziel_FahrPr_ESP 3;
BA_ "GenSigSwitchedByIgnition" SG_ 901 CHA_Ziel_FahrPr_Freilauf 0;
BA_ "GenSigSendType" SG_ 901 CHA_Ziel_FahrPr_Freilauf 3;
BA_ "GenSigSwitchedByIgnition" SG_ 901 CHA_Fahrer_Umschaltung 0;
BA_ "GenSigSendType" SG_ 901 CHA_Fahrer_Umschaltung 3;
BA_ "GenSigSwitchedByIgnition" SG_ 901 CHA_Fahrer_Umschaltung_BMA 0;
BA_ "GenSigSendType" SG_ 901 CHA_Fahrer_Umschaltung_BMA 3;
BA_ "GenSigSwitchedByIgnition" SG_ 901 CHA_Ziel_FahrPr_MO 0;
BA_ "GenSigSendType" SG_ 901 CHA_Ziel_FahrPr_MO 3;
BA_ "GenSigSwitchedByIgnition" SG_ 901 CHA_Ziel_FahrPr_GE 0;
BA_ "GenSigSendType" SG_ 901 CHA_Ziel_FahrPr_GE 3;
BA_ "GenSigSwitchedByIgnition" SG_ 901 CHA_Ziel_FahrPr_ALR 0;
BA_ "GenSigSendType" SG_ 901 CHA_Ziel_FahrPr_ALR 3;
BA_ "GenSigSwitchedByIgnition" SG_ 901 CHA_Ziel_FahrPr_MO_BZS 0;
BA_ "GenSigSendType" SG_ 901 CHA_Ziel_FahrPr_MO_BZS 3;
BA_ "GenSigSwitchedByIgnition" SG_ 901 CHA_Ziel_FahrPr_DR 0;
BA_ "GenSigSendType" SG_ 901 CHA_Ziel_FahrPr_DR 3;
BA_ "GenSigSwitchedByIgnition" SG_ 901 CHA_Ziel_FahrPr_VAQ 0;
BA_ "GenSigSendType" SG_ 901 CHA_Ziel_FahrPr_VAQ 3;
BA_ "GenSigSwitchedByIgnition" SG_ 901 CHA_Ziel_FahrPr_AFS 0;
BA_ "GenSigSendType" SG_ 901 CHA_Ziel_FahrPr_AFS 3;
BA_ "GenSigSwitchedByIgnition" SG_ 901 CHA_Ziel_FahrPr_RGS 0;
BA_ "GenSigSendType" SG_ 901 CHA_Ziel_FahrPr_RGS 3;
BA_ "GenSigSwitchedByIgnition" SG_ 901 CHA_Ziel_FahrPr_EPS 0;
BA_ "GenSigSendType" SG_ 901 CHA_Ziel_FahrPr_EPS 3;
BA_ "GenSigSwitchedByIgnition" SG_ 901 CHA_Ziel_FahrPr_ACC 0;
BA_ "GenSigSendType" SG_ 901 CHA_Ziel_FahrPr_ACC 3;
BA_ "GenSigSwitchedByIgnition" SG_ 901 CHA_Ziel_FahrPr_SAK 0;
BA_ "GenSigSendType" SG_ 901 CHA_Ziel_FahrPr_SAK 3;
BA_ "GenSigSwitchedByIgnition" SG_ 901 CHA_Ziel_FahrPr_MO_StSt 0;
BA_ "GenSigSendType" SG_ 901 CHA_Ziel_FahrPr_MO_StSt 3;
BA_ "GenSigSwitchedByIgnition" SG_ 1000 CHA_Ziel_FahrPr_EBKV 0;
BA_ "GenSigSendType" SG_ 1000 CHA_Ziel_FahrPr_EBKV 3;
BA_ "GenSigSwitchedByIgnition" SG_ 1000 CHA_Ziel_FahrPr_IL 0;
BA_ "GenSigSendType" SG_ 1000 CHA_Ziel_FahrPr_IL 3;
BA_ "GenSigSwitchedByIgnition" SG_ 1000 CHA_Current_Mode 0;
BA_ "GenSigSendType" SG_ 1000 CHA_Current_Mode 3;
BA_ "GenSigSwitchedByIgnition" SG_ 1000 CHA_Fahrer_Umschaltung 0;
BA_ "GenSigSendType" SG_ 1000 CHA_Fahrer_Umschaltung 3;
BA_ "GenSigSwitchedByIgnition" SG_ 1000 CHA_Ziel_FahrPr_QS 0;
BA_ "GenSigSendType" SG_ 1000 CHA_Ziel_FahrPr_QS 3;
BA_ "GenSigSwitchedByIgnition" SG_ 1000 CHA_Ziel_FahrPr_SCU 0;
BA_ "GenSigSendType" SG_ 1000 CHA_Ziel_FahrPr_SCU 3;
BA_ "GenSigSwitchedByIgnition" SG_ 1000 CHA_Ziel_FahrPr_HAL 0;
BA_ "GenSigSendType" SG_ 1000 CHA_Ziel_FahrPr_HAL 3;
BA_ "GenSigSwitchedByIgnition" SG_ 1000 CHA_Ziel_FahrPr_NR 0;
BA_ "GenSigSendType" SG_ 1000 CHA_Ziel_FahrPr_NR 3;
BA_ "GenSigSwitchedByIgnition" SG_ 1000 CHA_Ziel_FahrPr_AV 0;
BA_ "GenSigSendType" SG_ 1000 CHA_Ziel_FahrPr_AV 3;
BA_ "GenSigSwitchedByIgnition" SG_ 1000 CHA_Ziel_FahrPr_MXB 0;
BA_ "GenSigSendType" SG_ 1000 CHA_Ziel_FahrPr_MXB 3;
BA_ "GenSigSwitchedByIgnition" SG_ 1000 CHA_Ziel_FahrPr_AFR 0;
BA_ "GenSigSendType" SG_ 1000 CHA_Ziel_FahrPr_AFR 3;
BA_ "GenSigSwitchedByIgnition" SG_ 1000 CHA_Ziel_FahrPr_HDC 0;
BA_ "GenSigSendType" SG_ 1000 CHA_Ziel_FahrPr_HDC 3;
BA_ "GenSigSwitchedByIgnition" SG_ 1000 CHA_Ziel_FahrPr_EAR 0;
BA_ "GenSigSendType" SG_ 1000 CHA_Ziel_FahrPr_EAR 3;
BA_ "GenSigSwitchedByIgnition" SG_ 1000 CHA_Ziel_FahrPr_AEB 0;
BA_ "GenSigSendType" SG_ 1000 CHA_Ziel_FahrPr_AEB 3;
BA_ "GenSigSwitchedByIgnition" SG_ 1000 CHA_Ziel_FahrPr_FCWO 0;
BA_ "GenSigSendType" SG_ 1000 CHA_Ziel_FahrPr_FCWO 3;
BA_ "GenSigSwitchedByIgnition" SG_ 1000 CHA_Ziel_FahrPr_FCWP 0;
BA_ "GenSigSendType" SG_ 1000 CHA_Ziel_FahrPr_FCWP 3;
BA_ "GenSigSwitchedByIgnition" SG_ 2549880330 DIA_LED_LM_L_Req_Data 0;
BA_ "GenSigFuncType" SG_ 2549880330 DIA_LED_LM_L_Req_Data 9;
BA_ "GenSigSendType" SG_ 2549880330 DIA_LED_LM_L_Req_Data 3;
BA_ "GenSigFuncType" SG_ 2550011402 DIA_LED_LM_L_Resp_Data 9;
BA_ "GenSigSendType" SG_ 2550011402 DIA_LED_LM_L_Resp_Data 3;
BA_ "GenSigSwitchedByIgnition" SG_ 2549880331 DIA_LED_LM_R_Req_Data 0;
BA_ "GenSigFuncType" SG_ 2549880331 DIA_LED_LM_R_Req_Data 9;
BA_ "GenSigSendType" SG_ 2549880331 DIA_LED_LM_R_Req_Data 3;
BA_ "GenSigFuncType" SG_ 2550011403 DIA_LED_LM_R_Resp_Data 9;
BA_ "GenSigSendType" SG_ 2550011403 DIA_LED_LM_R_Resp_Data 3;
BA_ "GenSigSwitchedByIgnition" SG_ 1714 DGN_Verlernzaehler 0;
BA_ "GenSigSendType" SG_ 1714 DGN_Verlernzaehler 0;
BA_ "Fehlerwert" SG_ 1714 KBI_Kilometerstand 1048575;
BA_ "GenSigSwitchedByIgnition" SG_ 1714 KBI_Kilometerstand 0;
BA_ "GenSigStartValue" SG_ 1714 KBI_Kilometerstand 1048574;
BA_ "GenSigSendType" SG_ 1714 KBI_Kilometerstand 0;
BA_ "GenSigSwitchedByIgnition" SG_ 1714 UH_Jahr 0;
BA_ "GenSigSendType" SG_ 1714 UH_Jahr 0;
BA_ "Fehlerwert" SG_ 1714 UH_Monat 15;
BA_ "GenSigSwitchedByIgnition" SG_ 1714 UH_Monat 0;
BA_ "GenSigSendType" SG_ 1714 UH_Monat 0;
BA_ "GenSigSwitchedByIgnition" SG_ 1714 UH_Tag 0;
BA_ "GenSigSendType" SG_ 1714 UH_Tag 0;
BA_ "GenSigSwitchedByIgnition" SG_ 1714 UH_Stunde 0;
BA_ "GenSigSendType" SG_ 1714 UH_Stunde 0;
BA_ "GenSigSwitchedByIgnition" SG_ 1714 UH_Minute 0;
BA_ "GenSigSendType" SG_ 1714 UH_Minute 0;
BA_ "GenSigSwitchedByIgnition" SG_ 1714 UH_Sekunde 0;
BA_ "GenSigSendType" SG_ 1714 UH_Sekunde 0;
BA_ "GenSigSwitchedByIgnition" SG_ 1714 Vehicle_Driving_Cycle 0;
BA_ "GenSigSendType" SG_ 1714 Vehicle_Driving_Cycle 0;
BA_ "GenSigSwitchedByIgnition" SG_ 1714 Kombi_02_alt 0;
BA_ "GenSigFuncType" SG_ 1714 Kombi_02_alt 5;
BA_ "GenSigStartValue" SG_ 1714 Kombi_02_alt 1;
BA_ "GenSigSendType" SG_ 1714 Kombi_02_alt 0;
BA_ "GenSigSwitchedByIgnition" SG_ 1714 Uhrzeit_01_alt 0;
BA_ "GenSigFuncType" SG_ 1714 Uhrzeit_01_alt 5;
BA_ "GenSigStartValue" SG_ 1714 Uhrzeit_01_alt 1;
BA_ "GenSigSendType" SG_ 1714 Uhrzeit_01_alt 0;
BA_ "Fehlerwert" SG_ 1520 DI_KL_58xd 255;
BA_ "GenSigSwitchedByIgnition" SG_ 1520 DI_KL_58xd 0;
BA_ "GenSigStartValue" SG_ 1520 DI_KL_58xd 254;
BA_ "GenSigSendType" SG_ 1520 DI_KL_58xd 3;
BA_ "Fehlerwert" SG_ 1520 DI_KL_58xs 127;
BA_ "GenSigSwitchedByIgnition" SG_ 1520 DI_KL_58xs 0;
BA_ "GenSigStartValue" SG_ 1520 DI_KL_58xs 126;
BA_ "GenSigSendType" SG_ 1520 DI_KL_58xs 3;
BA_ "GenSigSwitchedByIgnition" SG_ 1520 DI_Display_Nachtdesign 0;
BA_ "GenSigSendType" SG_ 1520 DI_Display_Nachtdesign 3;
BA_ "Fehlerwert" SG_ 1520 DI_KL_58xt 127;
BA_ "GenSigSwitchedByIgnition" SG_ 1520 DI_KL_58xt 0;
BA_ "GenSigStartValue" SG_ 1520 DI_KL_58xt 126;
BA_ "GenSigSendType" SG_ 1520 DI_KL_58xt 3;
BA_ "GenSigSwitchedByIgnition" SG_ 1520 DI_Fotosensor 0;
BA_ "GenSigSendType" SG_ 1520 DI_Fotosensor 3;
BA_ "Fehlerwert" SG_ 1520 BCM1_Stellgroesse_Kl_58s 127;
BA_ "GenSigSwitchedByIgnition" SG_ 1520 BCM1_Stellgroesse_Kl_58s 0;
BA_ "GenSigStartValue" SG_ 1520 BCM1_Stellgroesse_Kl_58s 126;
BA_ "GenSigSendType" SG_ 1520 BCM1_Stellgroesse_Kl_58s 3;
BA_ "GenSigSwitchedByIgnition" SG_ 1603 KBI_Einheit_Datum 0;
BA_ "GenSigSendType" SG_ 1603 KBI_Einheit_Datum 3;
BA_ "GenSigSwitchedByIgnition" SG_ 1603 KBI_Einheit_Druck 0;
BA_ "GenSigSendType" SG_ 1603 KBI_Einheit_Druck 3;
BA_ "GenSigSwitchedByIgnition" SG_ 1603 KBI_Einheit_Streckenanz 0;
BA_ "GenSigSendType" SG_ 1603 KBI_Einheit_Streckenanz 3;
BA_ "GenSigSwitchedByIgnition" SG_ 1603 KBI_MFA_v_Einheit_02 0;
BA_ "GenSigSendType" SG_ 1603 KBI_MFA_v_Einheit_02 3;
BA_ "GenSigSwitchedByIgnition" SG_ 1603 KBI_Einheit_Temp 0;
BA_ "GenSigSendType" SG_ 1603 KBI_Einheit_Temp 3;
BA_ "GenSigSwitchedByIgnition" SG_ 1603 KBI_Einheit_Uhrzeit 0;
BA_ "GenSigSendType" SG_ 1603 KBI_Einheit_Uhrzeit 3;
BA_ "GenSigSwitchedByIgnition" SG_ 1603 KBI_Einheit_Verbrauch 0;
BA_ "GenSigSendType" SG_ 1603 KBI_Einheit_Verbrauch 3;
BA_ "GenSigSwitchedByIgnition" SG_ 1603 KBI_Einheit_Volumen 0;
BA_ "GenSigSendType" SG_ 1603 KBI_Einheit_Volumen 3;
BA_ "GenSigSwitchedByIgnition" SG_ 1603 KBI_Einheit_Verbrauch_elektr 0;
BA_ "GenSigSendType" SG_ 1603 KBI_Einheit_Verbrauch_elektr 3;
BA_ "GenSigSwitchedByIgnition" SG_ 1603 KBI_Einheit_Sprache 0;
BA_ "GenSigSendType" SG_ 1603 KBI_Einheit_Sprache 3;
BA_ "GenSigSwitchedByIgnition" SG_ 1603 KBI_Einheit_Verbrauch_Gas 0;
BA_ "GenSigSendType" SG_ 1603 KBI_Einheit_Verbrauch_Gas 3;
BA_ "GenSigSwitchedByIgnition" SG_ 1603 KBI_Einheit_Masse 0;
BA_ "GenSigSendType" SG_ 1603 KBI_Einheit_Masse 3;
BA_ "GenSigSwitchedByIgnition" SG_ 260 EPB_01_CRC 0;
BA_ "GenSigFuncType" SG_ 260 EPB_01_CRC 2;
BA_ "GenSigSendType" SG_ 260 EPB_01_CRC 0;
BA_ "GenSigSwitchedByIgnition" SG_ 260 EPB_01_BZ 0;
BA_ "GenSigFuncType" SG_ 260 EPB_01_BZ 1;
BA_ "GenSigSendType" SG_ 260 EPB_01_BZ 0;
BA_ "GenSigSwitchedByIgnition" SG_ 260 EPB_QBit_Laengsbeschleunigung 0;
BA_ "GenSigStartValue" SG_ 260 EPB_QBit_Laengsbeschleunigung 1;
BA_ "GenSigSendType" SG_ 260 EPB_QBit_Laengsbeschleunigung 0;
BA_ "GenSigSwitchedByIgnition" SG_ 260 EPB_QBit_Pedalweg_Kuppl 0;
BA_ "GenSigStartValue" SG_ 260 EPB_QBit_Pedalweg_Kuppl 1;
BA_ "GenSigSendType" SG_ 260 EPB_QBit_Pedalweg_Kuppl 0;
BA_ "GenSigSwitchedByIgnition" SG_ 260 EPB_Freig_Verzoeg_Anf 0;
BA_ "GenSigSendType" SG_ 260 EPB_Freig_Verzoeg_Anf 0;
BA_ "GenSigSwitchedByIgnition" SG_ 260 EPB_Verzoeg_Anf 0;
BA_ "GenSigStartValue" SG_ 260 EPB_Verzoeg_Anf 166;
BA_ "GenSigSendType" SG_ 260 EPB_Verzoeg_Anf 0;
BA_ "Fehlerwert" SG_ 260 EPB_Pedalweg_Kuppl 255;
BA_ "GenSigSwitchedByIgnition" SG_ 260 EPB_Pedalweg_Kuppl 0;
BA_ "GenSigSendType" SG_ 260 EPB_Pedalweg_Kuppl 0;
BA_ "GenSigSwitchedByIgnition" SG_ 260 EPB_DAA_Randbed_erf 0;
BA_ "GenSigSendType" SG_ 260 EPB_DAA_Randbed_erf 0;
BA_ "GenSigSwitchedByIgnition" SG_ 260 EPB_Fehlerstatus 0;
BA_ "GenSigSendType" SG_ 260 EPB_Fehlerstatus 0;
BA_ "Fehlerwert" SG_ 260 EPB_Schalterposition 3;
BA_ "GenSigSwitchedByIgnition" SG_ 260 EPB_Schalterposition 0;
BA_ "GenSigSendType" SG_ 260 EPB_Schalterposition 0;
BA_ "GenSigSwitchedByIgnition" SG_ 260 EPB_QBit_Schalterpos 0;
BA_ "GenSigStartValue" SG_ 260 EPB_QBit_Schalterpos 1;
BA_ "GenSigSendType" SG_ 260 EPB_QBit_Schalterpos 0;
BA_ "Fehlerwert" SG_ 260 EPB_Spannkraft 31;
BA_ "GenSigSwitchedByIgnition" SG_ 260 EPB_Spannkraft 0;
BA_ "GenSigStartValue" SG_ 260 EPB_Spannkraft 30;
BA_ "GenSigSendType" SG_ 260 EPB_Spannkraft 0;
BA_ "GenSigSwitchedByIgnition" SG_ 260 EPB_Status 0;
BA_ "GenSigSendType" SG_ 260 EPB_Status 0;
BA_ "GenSigSwitchedByIgnition" SG_ 257 ESP_02_CRC 0;
BA_ "GenSigFuncType" SG_ 257 ESP_02_CRC 2;
BA_ "GenSigSendType" SG_ 257 ESP_02_CRC 0;
BA_ "GenSigSwitchedByIgnition" SG_ 257 ESP_02_BZ 0;
BA_ "GenSigFuncType" SG_ 257 ESP_02_BZ 1;
BA_ "GenSigSendType" SG_ 257 ESP_02_BZ 0;
BA_ "GenSigSwitchedByIgnition" SG_ 257 ESP_QBit_Gierrate 0;
BA_ "GenSigStartValue" SG_ 257 ESP_QBit_Gierrate 1;
BA_ "GenSigSendType" SG_ 257 ESP_QBit_Gierrate 0;
BA_ "GenSigSwitchedByIgnition" SG_ 257 ESP_QBit_Laengsbeschl 0;
BA_ "GenSigStartValue" SG_ 257 ESP_QBit_Laengsbeschl 1;
BA_ "GenSigSendType" SG_ 257 ESP_QBit_Laengsbeschl 0;
BA_ "GenSigSwitchedByIgnition" SG_ 257 ESP_QBit_Querb 0;
BA_ "GenSigStartValue" SG_ 257 ESP_QBit_Querb 1;
BA_ "GenSigSendType" SG_ 257 ESP_QBit_Querb 0;
BA_ "GenSigSwitchedByIgnition" SG_ 257 ESP_Stillstandsflag 0;
BA_ "GenSigSendType" SG_ 257 ESP_Stillstandsflag 0;
BA_ "Fehlerwert" SG_ 257 ESP_Querbeschleunigung 255;
BA_ "GenSigSwitchedByIgnition" SG_ 257 ESP_Querbeschleunigung 0;
BA_ "GenSigStartValue" SG_ 257 ESP_Querbeschleunigung 127;
BA_ "GenSigSendType" SG_ 257 ESP_Querbeschleunigung 0;
BA_ "Fehlerwert" SG_ 257 ESP_Laengsbeschl 1023;
BA_ "GenSigSwitchedByIgnition" SG_ 257 ESP_Laengsbeschl 0;
BA_ "GenSigStartValue" SG_ 257 ESP_Laengsbeschl 512;
BA_ "GenSigSendType" SG_ 257 ESP_Laengsbeschl 0;
BA_ "GenSigSwitchedByIgnition" SG_ 257 ESC_Motorstartverzoegerung 0;
BA_ "GenSigSendType" SG_ 257 ESC_Motorstartverzoegerung 0;
BA_ "GenSigSwitchedByIgnition" SG_ 257 ESC_SeitenwindAssistent_Eingriff 0;
BA_ "GenSigSendType" SG_ 257 ESC_SeitenwindAssistent_Eingriff 0;
BA_ "GenSigSwitchedByIgnition" SG_ 257 ESP_Anschleppstart_Freigabe 0;
BA_ "GenSigSendType" SG_ 257 ESP_Anschleppstart_Freigabe 0;
BA_ "GenSigSwitchedByIgnition" SG_ 257 ESP_QBit_Anf_Vert_Wank 0;
BA_ "GenSigStartValue" SG_ 257 ESP_QBit_Anf_Vert_Wank 1;
BA_ "GenSigSendType" SG_ 257 ESP_QBit_Anf_Vert_Wank 0;
BA_ "Fehlerwert" SG_ 257 ESP_Gierrate 16383;
BA_ "GenSigSwitchedByIgnition" SG_ 257 ESP_Gierrate 0;
BA_ "GenSigSendType" SG_ 257 ESP_Gierrate 0;
BA_ "GenSigSwitchedByIgnition" SG_ 257 ESP_VZ_Gierrate 0;
BA_ "GenSigSendType" SG_ 257 ESP_VZ_Gierrate 0;
BA_ "GenSigSwitchedByIgnition" SG_ 257 ESP_Notbremsanzeige 0;
BA_ "GenSigSendType" SG_ 257 ESP_Notbremsanzeige 0;
BA_ "GenSigSwitchedByIgnition" SG_ 257 ESP_SpannungsAnf 0;
BA_ "GenSigSendType" SG_ 257 ESP_SpannungsAnf 0;
BA_ "GenSigSwitchedByIgnition" SG_ 257 ESP_PLA_Abbruch 0;
BA_ "GenSigSendType" SG_ 257 ESP_PLA_Abbruch 0;
BA_ "GenSigSwitchedByIgnition" SG_ 257 ESP_Status_ESP_PLA 0;
BA_ "GenSigSendType" SG_ 257 ESP_Status_ESP_PLA 0;
BA_REL_ "GenSigTimeoutTime" BU_SG_REL_ Frontsensorik SG_ 279 ACC_10_CRC 500;
BA_REL_ "GenSigTimeoutTime" BU_SG_REL_ Frontsensorik SG_ 279 ACC_10_BZ 500;
BA_REL_ "GenSigTimeoutTime" BU_SG_REL_ Frontsensorik SG_ 279 AWV2_Freigabe 500;
BA_REL_ "GenSigTimeoutTime" BU_SG_REL_ Frontsensorik SG_ 279 ANB_Teilbremsung_Freigabe 500;
BA_REL_ "GenSigTimeoutTime" BU_SG_REL_ Frontsensorik SG_ 279 ANB_Zielbremsung_Freigabe 500;
BA_REL_ "GenSigTimeoutTime" BU_SG_REL_ Frontradar SG_ 64 Airbag_01_CRC 500;
BA_REL_ "GenSigTimeoutTime" BU_SG_REL_ Frontsensorik SG_ 64 Airbag_01_CRC 500;
BA_REL_ "GenSigTimeoutTime" BU_SG_REL_ Frontradar SG_ 64 Airbag_01_BZ 500;
BA_REL_ "GenSigTimeoutTime" BU_SG_REL_ Frontsensorik SG_ 64 Airbag_01_BZ 500;
BA_REL_ "GenSigTimeoutTime" BU_SG_REL_ Frontradar SG_ 64 AB_Front_Crash 500;
BA_REL_ "GenSigTimeoutTime" BU_SG_REL_ Frontsensorik SG_ 64 AB_Front_Crash 500;
BA_REL_ "GenSigTimeoutTime" BU_SG_REL_ Frontsensorik SG_ 64 AB_Heck_Crash 500;
BA_REL_ "GenSigTimeoutTime" BU_SG_REL_ Frontsensorik SG_ 64 AB_SF_Crash 500;
BA_REL_ "GenSigTimeoutTime" BU_SG_REL_ Frontsensorik SG_ 64 AB_SB_Crash 500;
BA_REL_ "GenSigTimeoutTime" BU_SG_REL_ Frontsensorik SG_ 64 AB_Rollover_Crash 500;
BA_REL_ "GenSigTimeoutTime" BU_SG_REL_ Frontradar SG_ 64 AB_Crash_Int 500;
BA_REL_ "GenSigTimeoutTime" BU_SG_REL_ Frontsensorik SG_ 64 AB_Systemfehler 500;
BA_REL_ "GenSigTimeoutTime" BU_SG_REL_ Frontradar SG_ 64 SC_Masterzeit_Offset 500;
BA_REL_ "GenSigTimeoutTime" BU_SG_REL_ Frontradar SG_ 64 SC_Masterzeit 500;
BA_REL_ "GenSigTimeoutTime" BU_SG_REL_ Frontradar SG_ 1312 Airbag_02_CRC 2000;
BA_REL_ "GenSigTimeoutTime" BU_SG_REL_ Frontradar SG_ 1312 Airbag_02_BZ 2000;
BA_REL_ "GenSigTimeoutTime" BU_SG_REL_ Frontradar SG_ 1312 AB_Gurtschloss_FA 2000;
BA_REL_ "GenSigTimeoutTime" BU_SG_REL_ Frontradar SG_ 897 US_RDir_VL 800;
BA_REL_ "GenSigTimeoutTime" BU_SG_REL_ Frontradar SG_ 897 US_RDir_VLM 800;
BA_REL_ "GenSigTimeoutTime" BU_SG_REL_ Frontradar SG_ 897 US_RIndir_VLM_VL 800;
BA_REL_ "GenSigTimeoutTime" BU_SG_REL_ Frontradar SG_ 897 US_RIndir_VLM_VRM 800;
BA_REL_ "GenSigTimeoutTime" BU_SG_REL_ Frontradar SG_ 897 US_RIndir_VL_VLM 800;
BA_REL_ "GenSigTimeoutTime" BU_SG_REL_ Frontradar SG_ 897 US_GDir_VL 800;
BA_REL_ "GenSigTimeoutTime" BU_SG_REL_ Frontradar SG_ 897 US_GDir_VLM 800;
BA_REL_ "GenSigTimeoutTime" BU_SG_REL_ Frontradar SG_ 897 US_GIndir_VLM_VL 800;
BA_REL_ "GenSigTimeoutTime" BU_SG_REL_ Frontradar SG_ 897 US_GIndir_VLM_VRM 800;
BA_REL_ "GenSigTimeoutTime" BU_SG_REL_ Frontradar SG_ 897 US_GIndir_VL_VLM 800;
BA_REL_ "GenSigTimeoutTime" BU_SG_REL_ Frontradar SG_ 897 APS_01_Paketzaehler 800;
BA_REL_ "GenSigTimeoutTime" BU_SG_REL_ Frontradar SG_ 898 US_RDir_VR 800;
BA_REL_ "GenSigTimeoutTime" BU_SG_REL_ Frontradar SG_ 898 US_RDir_VRM 800;
BA_REL_ "GenSigTimeoutTime" BU_SG_REL_ Frontradar SG_ 898 US_RIndir_VRM_VR 800;
BA_REL_ "GenSigTimeoutTime" BU_SG_REL_ Frontradar SG_ 898 US_RIndir_VRM_VLM 800;
BA_REL_ "GenSigTimeoutTime" BU_SG_REL_ Frontradar SG_ 898 US_RIndir_VR_VRM 800;
BA_REL_ "GenSigTimeoutTime" BU_SG_REL_ Frontradar SG_ 898 US_GDir_VR 800;
BA_REL_ "GenSigTimeoutTime" BU_SG_REL_ Frontradar SG_ 898 US_GDir_VRM 800;
BA_REL_ "GenSigTimeoutTime" BU_SG_REL_ Frontradar SG_ 898 US_GIndir_VRM_VLM 800;
BA_REL_ "GenSigTimeoutTime" BU_SG_REL_ Frontradar SG_ 898 US_GIndir_VRM_VR 800;
BA_REL_ "GenSigTimeoutTime" BU_SG_REL_ Frontradar SG_ 898 US_GIndir_VR_VRM 800;
BA_REL_ "GenSigTimeoutTime" BU_SG_REL_ Frontradar SG_ 898 APS_02_Paketzaehler 800;
BA_REL_ "GenSigTimeoutTime" BU_SG_REL_ Frontradar SG_ 896 US_ACC_BZ 800;
BA_REL_ "GenSigTimeoutTime" BU_SG_REL_ Frontradar SG_ 896 US_Sende_Modus 800;
BA_REL_ "GenSigTimeoutTime" BU_SG_REL_ Frontradar SG_ 896 US_relevanter_Fehler 800;
BA_REL_ "GenSigTimeoutTime" BU_SG_REL_ Frontradar SG_ 896 US_relevante_Nichtverfuegbarkeit 800;
BA_REL_ "GenSigTimeoutTime" BU_SG_REL_ Frontradar SG_ 896 US_Freisicht_nio 800;
BA_REL_ "GenSigTimeoutTime" BU_SG_REL_ Frontradar SG_ 896 US_blindness_detected 800;
BA_REL_ "GenSigTimeoutTime" BU_SG_REL_ Frontradar SG_ 896 US_Freie_Weglaenge_Front_Typ 800;
BA_REL_ "GenSigTimeoutTime" BU_SG_REL_ Frontradar SG_ 896 US_Freie_Weglaenge_Front 800;
BA_REL_ "GenSigTimeoutTime" BU_SG_REL_ Frontradar SG_ 2536703232 BAP_ACC_ASG_01_Header 800;
BA_REL_ "GenSigTimeoutTime" BU_SG_REL_ Frontradar SG_ 2536708864 BAP_AWV_ASG_01_Header 800;
BA_REL_ "GenSigTimeoutTime" BU_SG_REL_ Frontradar SG_ 2536708865 BAP_AWV_ASG_02_Header 800;
BA_REL_ "GenSigTimeoutTime" BU_SG_REL_ Frontsensorik SG_ 2536708352 BAP_LDW_ASG_01_Header 800;
BA_REL_ "GenSigTimeoutTime" BU_SG_REL_ Frontsensorik SG_ 2536708353 BAP_LDW_ASG_02_Header 800;
BA_REL_ "GenSigTimeoutTime" BU_SG_REL_ Frontsensorik SG_ 2536710400 BAP_VZA_ASG_01_Header 800;
BA_REL_ "GenSigTimeoutTime" BU_SG_REL_ Frontsensorik SG_ 2536710401 BAP_VZA_ASG_02_Header 800;
BA_REL_ "GenSigTimeoutTime" BU_SG_REL_ Frontradar SG_ 870 BM_Warnblinken 5000;
BA_REL_ "GenSigTimeoutTime" BU_SG_REL_ Frontsensorik SG_ 870 BM_links 5000;
BA_REL_ "GenSigTimeoutTime" BU_SG_REL_ Frontsensorik SG_ 870 BM_rechts 5000;
BA_REL_ "GenSigTimeoutTime" BU_SG_REL_ Frontradar SG_ 901 CHA_Fahrer_Umschaltung 5000;
BA_REL_ "GenSigTimeoutTime" BU_SG_REL_ Frontradar SG_ 901 CHA_Ziel_FahrPr_ACC 5000;
BA_REL_ "GenSigTimeoutTime" BU_SG_REL_ Frontradar SG_ 1000 CHA_Current_Mode 5000;
BA_REL_ "GenSigTimeoutTime" BU_SG_REL_ Frontradar SG_ 1714 DGN_Verlernzaehler 5000;
BA_REL_ "GenSigTimeoutTime" BU_SG_REL_ Frontsensorik SG_ 1714 DGN_Verlernzaehler 5000;
BA_REL_ "GenSigTimeoutTime" BU_SG_REL_ Frontradar SG_ 1714 KBI_Kilometerstand 5000;
BA_REL_ "GenSigTimeoutTime" BU_SG_REL_ Frontsensorik SG_ 1714 KBI_Kilometerstand 5000;
BA_REL_ "GenSigTimeoutTime" BU_SG_REL_ Frontradar SG_ 1714 UH_Jahr 5000;
BA_REL_ "GenSigTimeoutTime" BU_SG_REL_ Frontsensorik SG_ 1714 UH_Jahr 5000;
BA_REL_ "GenSigTimeoutTime" BU_SG_REL_ Frontradar SG_ 1714 UH_Monat 5000;
BA_REL_ "GenSigTimeoutTime" BU_SG_REL_ Frontsensorik SG_ 1714 UH_Monat 5000;
BA_REL_ "GenSigTimeoutTime" BU_SG_REL_ Frontradar SG_ 1714 UH_Tag 5000;
BA_REL_ "GenSigTimeoutTime" BU_SG_REL_ Frontsensorik SG_ 1714 UH_Tag 5000;
BA_REL_ "GenSigTimeoutTime" BU_SG_REL_ Frontradar SG_ 1714 UH_Stunde 5000;
BA_REL_ "GenSigTimeoutTime" BU_SG_REL_ Frontsensorik SG_ 1714 UH_Stunde 5000;
BA_REL_ "GenSigTimeoutTime" BU_SG_REL_ Frontradar SG_ 1714 UH_Minute 5000;
BA_REL_ "GenSigTimeoutTime" BU_SG_REL_ Frontsensorik SG_ 1714 UH_Minute 5000;
BA_REL_ "GenSigTimeoutTime" BU_SG_REL_ Frontradar SG_ 1714 UH_Sekunde 5000;
BA_REL_ "GenSigTimeoutTime" BU_SG_REL_ Frontsensorik SG_ 1714 UH_Sekunde 5000;
BA_REL_ "GenSigTimeoutTime" BU_SG_REL_ Frontradar SG_ 1714 Kombi_02_alt 5000;
BA_REL_ "GenSigTimeoutTime" BU_SG_REL_ Frontsensorik SG_ 1714 Kombi_02_alt 5000;
BA_REL_ "GenSigTimeoutTime" BU_SG_REL_ Frontradar SG_ 1714 Uhrzeit_01_alt 5000;
BA_REL_ "GenSigTimeoutTime" BU_SG_REL_ Frontsensorik SG_ 1714 Uhrzeit_01_alt 5000;
BA_REL_ "GenSigTimeoutTime" BU_SG_REL_ Frontradar SG_ 260 EPB_01_CRC 500;
BA_REL_ "GenSigTimeoutTime" BU_SG_REL_ Frontradar SG_ 260 EPB_01_BZ 500;
BA_REL_ "GenSigTimeoutTime" BU_SG_REL_ Frontradar SG_ 260 EPB_Freig_Verzoeg_Anf 500;
BA_REL_ "GenSigTimeoutTime" BU_SG_REL_ Frontradar SG_ 260 EPB_Fehlerstatus 500;
BA_REL_ "GenSigTimeoutTime" BU_SG_REL_ Frontradar SG_ 260 EPB_Schalterposition 500;
BA_REL_ "GenSigTimeoutTime" BU_SG_REL_ Frontradar SG_ 260 EPB_QBit_Schalterpos 500;
BA_REL_ "GenSigTimeoutTime" BU_SG_REL_ Frontradar SG_ 260 EPB_Spannkraft 500;
BA_REL_ "GenSigTimeoutTime" BU_SG_REL_ Frontradar SG_ 260 EPB_Status 500;
BA_REL_ "GenSigTimeoutTime" BU_SG_REL_ Frontradar SG_ 257 ESP_02_CRC 500;
BA_REL_ "GenSigTimeoutTime" BU_SG_REL_ Frontsensorik SG_ 257 ESP_02_CRC 500;
BA_REL_ "GenSigTimeoutTime" BU_SG_REL_ Frontradar SG_ 257 ESP_02_BZ 500;
BA_REL_ "GenSigTimeoutTime" BU_SG_REL_ Frontsensorik SG_ 257 ESP_02_BZ 500;
BA_REL_ "GenSigTimeoutTime" BU_SG_REL_ Frontradar SG_ 257 ESP_QBit_Gierrate 500;
BA_REL_ "GenSigTimeoutTime" BU_SG_REL_ Frontsensorik SG_ 257 ESP_QBit_Gierrate 500;
BA_REL_ "GenSigTimeoutTime" BU_SG_REL_ Frontradar SG_ 257 ESP_QBit_Laengsbeschl 500;
BA_REL_ "GenSigTimeoutTime" BU_SG_REL_ Frontsensorik SG_ 257 ESP_QBit_Laengsbeschl 500;
BA_REL_ "GenSigTimeoutTime" BU_SG_REL_ Frontradar SG_ 257 ESP_QBit_Querb 500;
BA_REL_ "GenSigTimeoutTime" BU_SG_REL_ Frontsensorik SG_ 257 ESP_QBit_Querb 500;
BA_REL_ "GenSigTimeoutTime" BU_SG_REL_ Frontradar SG_ 257 ESP_Querbeschleunigung 500;
BA_REL_ "GenSigTimeoutTime" BU_SG_REL_ Frontsensorik SG_ 257 ESP_Querbeschleunigung 500;
BA_REL_ "GenSigTimeoutTime" BU_SG_REL_ Frontradar SG_ 257 ESP_Laengsbeschl 500;
BA_REL_ "GenSigTimeoutTime" BU_SG_REL_ Frontsensorik SG_ 257 ESP_Laengsbeschl 500;
BA_REL_ "GenSigTimeoutTime" BU_SG_REL_ Frontradar SG_ 257 ESP_Gierrate 500;
BA_REL_ "GenSigTimeoutTime" BU_SG_REL_ Frontsensorik SG_ 257 ESP_Gierrate 500;
BA_REL_ "GenSigTimeoutTime" BU_SG_REL_ Frontradar SG_ 257 ESP_VZ_Gierrate 500;
BA_REL_ "GenSigTimeoutTime" BU_SG_REL_ Frontsensorik SG_ 257 ESP_VZ_Gierrate 500;
VAL_ 780 ACC_Wunschgeschw_02 1023 "keine_Anzeige" ;
VAL_ 780 ACC_Status_Prim_Anz 0 "Symbol nicht beleuchtet" 1 "Farbe 1 (typisch 'gruen')" 2 "Farbe 2 (typisch 'rot')" 3 "Farbe 3 (typisch 'gelb')" ;
VAL_ 780 ACC_Abstandsindex 0 "Sonderanzeige_graue_Fahrbahn" 1022 "Sonderanzeige_graue_Fahrbahn" 1023 "Sonderanzeige_Fahrbahn_mit_gruenem_roten_Bereich" ;
VAL_ 780 ACC_Akustik_02 0 "keine_Akustik" 1 "hochpriore_Akustik" 2 "niederpriore_Akustik" 3 "hochpriore_Dauerakustik" ;
VAL_ 780 ACC_Warnung_Verkehrszeichen_1 0 "keine_Warnung_Initialwert" 1 "Warnung" ;
VAL_ 780 ACC_Gesetzte_Zeitluecke 0 "keine_Anzeige" 1 "Zeitluecke_1" 2 "Zeitluecke_2" 3 "Zeitluecke_3" 4 "Zeitluecke_4" 5 "Zeitluecke_5" 6 "nicht_definiert" 7 "nicht_definiert" ;
VAL_ 780 ACC_Optischer_Fahrerhinweis 0 "optischer_Fahrerhinweis_AUS" 1 "optischer_Fahrerhinweis_EIN" ;
VAL_ 780 ACC_Typ_Tachokranz 0 "Tachokranz_lang" 1 "Tachokranz_kurz" ;
VAL_ 780 ACC_Anzeige_Zeitluecke 0 "Anzeige_Zeitluecke_nicht_angefordert" 1 "Anzeige_Zeitluecke_angefordert" ;
VAL_ 780 ACC_Tachokranz 0 "Tachokranz_nicht_beleuchtet" 1 "Tachokranz_beleuchtet" ;
VAL_ 780 ACC_Display_Prio 0 "hoechste_Prio" 1 "mittlere_Prio" 2 "geringe_Prio" 3 "keine_Prio" ;
VAL_ 780 ACC_Relevantes_Objekt 0 "Symbol_nicht_beleuchtet" 1 "Farbe_1_typisch_gruen" 2 "Farbe_2_typisch_rot" 3 "Farbe_3_typisch_gelb" ;
VAL_ 780 ACC_Texte_Primaeranz 0 "keine Anzeige" 1 "ACC nicht verfuegbar !" 2 "Auto_Auto_ _ _" 3 "Auto_ _Auto_ _" 4 "Auto_ _ _Auto_" 5 "Auto_ _ _ _Auto" 6 "Auto_Auto_ _ _ Gong (durchgestrichen)" 7 "Auto_ _Auto_ _ Gong (durchgestrichen)" 8 "Auto_ _ _Auto_ Gong (durchgestrichen)" 9 "Auto_ _ _ _Auto Gong (durchgestrichen)" 10 "ACC bereit" 11 "keine Abstandsregelung" 12 "ACC Sensor Sicht !" 13 "ACC nicht verfuegbar" 14 "o  o  o" 15 "Hochschalten" 16 "ESP Eingriff" 17 "Herunterschalten" 18 "Parkbremse !" 19 "Geschwindigkeitsgrenze" 20 "Waehlhebelposition !" 21 "VDA ACC-Symbol YYY km/h / mph" 22 "Tempolimit XXX km/h / mph" 23 "Kurve XXX km/h / mph" 24 "ACC Abschaltung" 25 "Symbol 'Eieruhr'" 26 "!" 27 "--- km/h / mph" 28 "XXX km/h / mph (Schriftart 2)" 29 "Lenkradwinkel" 30 "Anfahren bestaetigen" 31 "Fahrzeug verloren" 32 "Im Stand nicht moeglich" 33 "Ungueltiger Anfahrbefehl" 34 "Tuer offen !" 35 "Fahrer Gurtschloss offen !" 36 "Schalthebelposition !" 37 "Drehzahl !" 38 "Kurvenassistent aus" 39 "Tempolimit aus" 40 "Abbiegeassistent" 41 "Ortsanfang XXX km/h / mph" 42 "Ortsende XXX km/h / mph" 43 "Tempolimit Ende XXX km/h / mph" 44 "HDC aktiv" 45 "braking guard Bremsruck" 46 "braking guard aus" 47 "braking guard aus" 48 "Uebernehmen !" 49 "Steigung zu gross" 50 "Stehendes Objekt voraus" 51 "SET / 'GRA Symbol'___xxx km/h / mph" 52 "SET / 'GRA Symbol' xxx km/h / mph" 53 "ACC aus" 54 "ACC startet" 55 "ACC reinigen" 56 "ACC Fehler" 57 "ACC haelt an !" 58 "Bremse betaetigen !" 59 "Kupplung betaetigt" 60 "LIM AUS" 61 "LIM AKTIV" 62 "LIM PASSIV" 63 "LIM FEHLER" 64 "Bremse ueberhitzt !" 65 "Bremse haelt !" 66 "ESP PASSIV !" 67 "ACC_anfahrbereit" 68 "Gang_einlegen" 69 "Rechtsueberholen_verhindert" 70 "Linksueberholen_verhindert" 71 "Achtung_Geschwindigkeitsueberschreitung" 72 "Tempolimit_und_Kurvenassistent_nicht_verfuegbar" ;
VAL_ 780 ACC_Wunschgeschw_erreicht 0 "Wunschgeschwindigkeit_nicht_erreicht" 1 "Wunschgeschwindigkeit_erreicht" ;
VAL_ 780 ACC_Typ_Tachokranz_unten 0 "LEDs_an" 1 "LEDs_aus" ;
VAL_ 780 ACC_Status_Anzeige 0 "ACC_GRA_Hauptschalter_aus" 1 "ACC_in_Init_nicht_bei_GRA" 2 "ACC_GRA_passiv" 3 "ACC_GRA_aktiv" 4 "ACC_GRA_im_Hintergrund_uebertreten" 5 "ACC_GRA_Abschaltreaktion" 6 "ACC_reversibel_aus_nicht_bei_GRA" 7 "ACC_GRA_irreversibel_aus" ;
VAL_ 804 ACC_Texte_Sekundaeranz 0 "keine_Anzeige" 1 "Zielfahrzeug_erkannt" 2 "Rechtskurve_voraus" 3 "Linkskurve_voraus" 4 "Tempolimit_voraus" 5 "Sensorsicht" 6 "Anfahrbereit" 7 "Tempolimit_erkannt" 8 "Kreuzung_voraus" 9 "Kreisverkehr_voraus" ;
VAL_ 804 ACC_Texte_Zusatzanz 0 "keine_Anzeige" 1 "ACC_AUS" 2 "ACC_BEREIT" 3 "UEBERTRETEN" 4 "ABSTAND" 5 "DISTANZ_1" 6 "DISTANZ_2" 7 "DISTANZ_3" 8 "DISTANZ_4" 9 "DISTANZ_1__dyn" 10 "DISTANZ_2__dyn" 11 "DISTANZ_3__dyn" 12 "DISTANZ_4__dyn" 13 "DISTANZ_1__stand" 14 "DISTANZ_2__stand" 15 "DISTANZ_3__stand" 16 "DISTANZ_4__stand" 17 "DISTANZ_1__comf" 18 "DISTANZ_2__comf" 19 "DISTANZ_3__comf" 20 "DISTANZ_4__comf" 21 "DISTANZ_1__efficiency" 22 "DISTANZ_2__efficiency" 23 "DISTANZ_3__efficiency" 24 "DISTANZ_4__efficiency" 25 "DISTANZ_5" 26 "DISTANZ_5__dyn" 27 "DISTANZ_5__stand" 28 "DISTANZ_5__comf" 29 "DISTANZ_5__efficiency" 30 "ACHTUNG" 31 "Abstandsanzeige" 32 "Abstandsanz_Warnung_aktiviert" ;
VAL_ 804 ACC_Status_Zusatzanz 0 "keine Anzeige" 1 "Bild 1 (Fzg. Silhouette, typ. farblos)" 2 "Bild 2 (Fzg. Farbe 1, typ. grau)" 3 "Bild 3 (Fzg. Farbe 2, typ. rot)" 4 "Bild 4 (Symbol 1 ACCplus, typ. Doppelfzg. gelb)" 5 "Bild 5 (Symbol 2 ACCplus, typ. Doppelfzg. grau)" 6 "Bild 6 (Fzg. Farbe 2, typ. rot) mit Priorität im Kombi (Pop-up)" ;
VAL_ 804 ACC_Texte 0 "keine_Anzeige" 1 "ACC_nicht_verfuegbar" 2 "ACC_und_AWV_nicht_verfuegbar" 3 "ACC_keine_Sensorsicht" 4 "ACC_und_AWV_keine_Sensorsicht" 5 "ACC_Steigung_zu_gross" 6 "ACC_nur_in_Fahrstufe_verfuegbar" 7 "ACC_Parkbremse_betaetigt" 8 "ACC_ESP_Eingriff" 9 "ACC_Bitte_uebernehmen" 10 "ACC_HDC_betaetigt" 11 "ACC_Geschwindigkeitsgrenze" 12 "ACC_Schalthebelposition" 13 "ACC_Drehzahl" 14 "ACC_Kupplung_betaetigt" 15 "ACC_Aktivierverhinderung" 16 "ACC_Abschaltung" 17 "ACC_Parkassistent_aktiv" 18 "ACC_ESC_aus" 19 "ACC_Charisma_Modus_inkompatibel" 20 "ACC_Stehendes_Objekt_voraus" 21 "ACA_Fahreruebernahme" 22 "ACA_Querfuehrung_nicht_verfuegbar" ;
VAL_ 804 ACC_Texte_braking_guard 0 "keine_Anzeige" 1 "AWV_aus" 2 "AWV_Warnung" 3 "AWV_Demomodus" 4 "AWV_Systemstoerung" 5 "AWV_Eingriff" 6 "AWV_Vorwarnung_aus" 7 "AWV_keine_Sensorsicht" ;
VAL_ 804 ACC_Warnhinweis 0 "kein_Warnhinweis" 1 "Warnhinweis" ;
VAL_ 804 ACC_Zeitluecke_Abstandswarner 61 "Freifahrt" 62 "nicht_definiert" 63 "keine_Anzeige" ;
VAL_ 804 ACC_Abstand_Abstandswarner 509 "Freifahrt" 510 "nicht_definiert" 511 "keine_Anzeige" ;
VAL_ 804 ACC_Tempolimit 0 "keine_Anzeige" 1 "5_zulHoechstgeschw" 2 "7_zulHoechstgeschw" 3 "10_zulHoechstgeschw" 4 "15_zulHoechstgeschw" 5 "20_zulHoechstgeschw" 6 "25_zulHoechstgeschw" 7 "30_zulHoechstgeschw" 8 "35_zulHoechstgeschw" 9 "40_zulHoechstgeschw" 10 "45_zulHoechstgeschw" 11 "50_zulHoechstgeschw" 12 "55_zulHoechstgeschw" 13 "60_zulHoechstgeschw" 14 "65_zulHoechstgeschw" 15 "70_zulHoechstgeschw" 16 "75_zulHoechstgeschw" 17 "80_zulHoechstgeschw" 18 "85_zulHoechstgeschw" 19 "90_zulHoechstgeschw" 20 "95_zulHoechstgeschw" 21 "100_zulHoechstgeschw" 22 "110_zulHoechstgeschw" 23 "120_zulHoechstgeschw" 24 "130_zulHoechstgeschw" 25 "140_zulHoechstgeschw" 26 "150_zulHoechstgeschw" 27 "160_zulHoechstgeschw" 28 "200_zulHoechstgeschw" 30 "250_zulHoechstgeschw" 31 "Ende_zulHoechstgeschw" ;
VAL_ 804 ACC_Charisma_FahrPr 0 "keine_Funktion" 1 "Programm_1" 2 "Programm_2" 3 "Programm_3" 4 "Programm_4" 5 "Programm_5" 6 "Programm_6" 7 "Programm_7" 8 "Programm_8" 9 "Programm_9" 10 "Programm_10" 11 "Programm_11" 12 "Programm_12" 13 "Programm_13" 14 "Programm_14" 15 "Programm_15" ;
VAL_ 804 ACC_Charisma_Status 0 "Init" 1 "verfuegbar" 2 "nicht_verfuegbar" 3 "asynchron_durch_Fahrerwunsch" ;
VAL_ 804 ACC_Texte_Abstandswarner 0 "keine_Anzeige" 1 "Systemstoerung" 2 "keine_Sensorsicht" 3 "zurzeit_eingeschraenkt" ;
VAL_ 290 ACC_limitierte_Anfahrdyn 0 "keine_Limitierung" 1 "Limitierung_Anfahrdynamik_angefordert" ;
VAL_ 290 ACC_nachtr_Stopp_Anf 0 "nicht_angefordert" 1 "angefordert" ;
VAL_ 290 ACC_StartStopp_Info 0 "Motorlauf_langfristig_nicht_notwendig_Stoppfreigabe" 1 "Motoranlauf_nicht_zwingend_notwendig_Stoppverbot_keine_Startanforderung" 2 "Motoranlauf_zwingend_notwendig_Startanforderung" 3 "Systemfehler" ;
VAL_ 290 ACC_Sollbeschleunigung_02 2046 "Neutralwert" 2047 "Fehler" ;
VAL_ 290 ACC_Anfahren 0 "keine_Anforderung_Anfahren" 1 "Anforderung_Anfahren" ;
VAL_ 290 ACC_Anhalten 0 "kein_Anhalten_gewuenscht" 1 "Anhalten_gewuenscht" ;
VAL_ 290 ACC_Typ 0 "Basis_ACC" 1 "ACC_mit_FollowToStop" 2 "ACC_mit_StopAndGo" 3 "ACC_nicht_codiert" ;
VAL_ 290 ACC_Status_ACC 0 "ACC_OFF_Hauptschalter_aus" 1 "ACC_INIT" 2 "ACC_STANDBY" 3 "ACC_AKTIV_regelt" 4 "ACC_OVERRIDE" 5 "ACC_Abschaltreaktion" 6 "reversibler_Fehler_im_ACC_System" 7 "irreversibler_Fehler_im_ACC_System" ;
VAL_ 290 ACC_Minimale_Bremsung 0 "Anforderung_Minimale_Bremsung_nicht_aktiv" 1 "Anforderung_Minimale_Bremsung_aktiv" ;
VAL_ 302 ACC_Anhalteweg 2046 "Neutralwert" 2047 "Fehler" ;
VAL_ 302 ACC_Anhalten 0 "kein_Anhalten_gewuenscht" 1 "Anhalten_gewuenscht" ;
VAL_ 302 ACC_Freilauf_Anf 0 "keine Freilauf-Anforderung" 1 "Freilauf-Anforderung" ;
VAL_ 302 ACC_Freilauf_Info 0 "Freilauf_freigegeben" 1 "kein_Uebergang_in_Freilauf_zulaessig" 2 "Freilauf_nicht_freigegeben" 3 "Freilauf_Anforderung" ;
VAL_ 302 ACC_Anforderung_HMS 0 "keine_Anforderung" 1 "halten" 2 "parken" 3 "halten_Standby" 4 "anfahren" 5 "Loesen_ueber_Rampe" ;
VAL_ 302 ACC_Anfahren 0 "keine_Anforderung_Anfahren" 1 "Anforderung_Anfahren" ;
VAL_ 302 ACC_Folgebeschl 254 "Neutralwert" ;
VAL_ 302 ACC_Sollbeschleunigung_02 2046 "Neutralwert" 2047 "Fehler" ;
VAL_ 279 AWV1_Anf_Prefill 0 "Prefill_nicht_aktivieren" 1 "Prefill_aktivieren" ;
VAL_ 279 ANB_CM_Info 0 "Standard" 1 "Erweitert" ;
VAL_ 279 AWV2_Freigabe 0 "keine_Freigabe" 1 "Freigabe" ;
VAL_ 279 AWV1_HBA_Param 0 "Defaultparametersatz" 1 "Parametersatz_mit_leicht_erhoehter_Empfindlichkeit" 2 "Parametersatz_mit_erhoehter_Empfindlichkeit" 3 "Parametersatz_mit_hoechster_Empfindlichkeit" ;
VAL_ 279 AWV2_Priowarnung 0 "Anzeige_Verlassen_der_Fahrspur_wird_nicht_unterdrueckt" 1 "Anzeige_Verlassen_der_Fahrspur_wird_unterdrueckt" ;
VAL_ 279 ANB_CM_Anforderung 0 "keine_Anforderung" 1 "Anforderung_aktiv" ;
VAL_ 279 ANB_Info_Teilbremsung 0 "Auspraegung_Standard" 1 "Auspraegung_Erweitert" ;
VAL_ 279 ANB_Notfallblinken 0 "kein_ANB_Notfallblinken" 1 "Notfallblinken_ANB_angefordert" ;
VAL_ 279 ANB_Teilbremsung_Freigabe 0 "Teilbremsung_nicht_freigegeben" 1 "Teilbremsung_freigegeben" ;
VAL_ 279 ANB_Zielbremsung_Freigabe 0 "Zielbremsung_nicht_freigegeben" 1 "Zielbremsung_freigegeben" ;
VAL_ 279 AWV_Vorstufe 0 "keine_Notbremsung_erwartet" 1 "Notbremsung_in_Kuerze" ;
VAL_ 279 AWV_Halten 0 "keine_Anforderung" 1 "Anforderung_das_Fzg_im_Stillstand_zu_halten" ;
VAL_ 279 AWV_CityANB_Auspraegung 0 "autom_Bremsung_im_ges_vBereich" 1 "autom_Bremsung_im_def_vBereich" ;
VAL_ 279 PCF_Freigabe 0 "keine_Freigabe_PreCrashFront" 1 "Freigabe_PreCrashFront" ;
VAL_ 279 AWV1_ECD_Anlauf 0 "ECD_Anlauf_nicht_aktivieren" 1 "ECD_Anlauf_aktivieren" ;
VAL_ 279 PCF_Time_to_collision 255 "Objektstatus=0x0__oder_berechneter_TTC_Wert_groesser_als_Maximalwert" ;
VAL_ 679 ACC_Regelgeschw 1023 "keine_Anzeige" ;
VAL_ 679 ACC_Einheit_maxSetzgeschw 0 "kmh" 1 "mph" ;
VAL_ 679 ACC_maxSetzgeschw 511 "Init_Neutralwert" ;
VAL_ 679 ACC_minRegelgeschw 255 "keine_Anzeige" ;
VAL_ 679 ACC_maxRegelgeschw 255 "keine_Anzeige" ;
VAL_ 679 ACC_Tempolimitassistent 0 "keine_Anzeige" 1 "Tempolimitassistent_aktiv" 2 "Tempolimitassistent_nicht_verfuegbar" 3 "Tempolimitassistent_Fahreruebernahme" ;
VAL_ 679 ACC_Kurvenassistent 0 "keine_Anzeige" 1 "Kreuzung" 2 "Rechtskurve" 3 "Linkskurve" 4 "Kreisverkehr" ;
VAL_ 679 ACC_RUV 0 "keine_Anzeige" 1 "RUV_aktiv_Rechtsverkehr" 2 "RUV_aktiv_Linksverkehr" ;
VAL_ 679 ACC_Tachokranz 0 "Tachokranz_nicht_beleuchtet" 1 "Tachokranz_beleuchtet" ;
VAL_ 679 ACC_Typ_Tachokranz_unten 0 "LEDs_an" 1 "LEDs_aus" ;
VAL_ 679 ACC_ENG_Texte 0 "keine_Anzeige" 1 "keine_Laenderverfuegbarkeit" 2 "nicht_verfuegbar" 3 "Geschwindigkeitsgrenze" ;
VAL_ 681 AWV_Warnung 0 "keine_Anzeige" 1 "latente_Vorwarnung" 2 "Vorwarnung" 3 "Akutwarnung" 4 "Eingriff" 5 "Fahreruebernahmeaufforderung" 6 "Abbiegewarnung" ;
VAL_ 681 AWV_Texte 0 "keine_Anzeige" 1 "Systemstoerung" 2 "keine_Sensorsicht" 3 "Demomodus" 4 "System_aus" 5 "nicht_definiert" 6 "ESC_aus" 7 "zurzeit_eingeschraenkt" ;
VAL_ 681 AWV_Status_Anzeige 0 "Init" 1 "verfuegbar" 2 "nicht_verfuegbar" ;
VAL_ 681 AWV_Einstellung_System_FSG 0 "deaktiviert" 1 "aktiviert" ;
VAL_ 681 AWV_Einstellung_Warnung_FSG 0 "Aus" 1 "Setting_2" 2 "Setting_3" 3 "Setting_4" 4 "Setting_5" 5 "Ein" ;
VAL_ 681 AWV_Warnlevel 0 "keine_Gefaehrdung" 63 "max_Gefaehrdung" ;
VAL_ 2527679682 ACC_ASM_Ereignis 0 "No_Event" 255 "ASM_Trigger" ;
VAL_ 2527679682 ACC_ASM_Zeitstempel 255 "Init" ;
VAL_ 64 AB_RGS_Anst 4 "aktiv_Niveau_1" 5 "aktiv_Niveau_2" 6 "aktiv_Niveau_3" 7 "aktiv_Niveau_4" 8 "deaktiviert" ;
VAL_ 64 AB_Front_Crash 0 "kein_Front_Crash" 1 "Front_Crash" ;
VAL_ 64 AB_Heck_Crash 0 "kein_Heck_Crash" 1 "Heck_Crash" ;
VAL_ 64 AB_SF_Crash 0 "kein_Seiten_Crash_Fahrer" 1 "Seiten_Crash_Fahrer" ;
VAL_ 64 AB_SB_Crash 0 "kein_Seiten_Crash_Beifahrer" 1 "Seiten_Crash_Beifahrer" ;
VAL_ 64 AB_Rollover_Crash 0 "kein_Rollover" 1 "Rollover" ;
VAL_ 64 AB_Crash_Int 0 "kein_Crash" 1 "Crash_Intensitaet_1" 2 "Crash_Intensitaet_2_(nur_Stellgliedtest_MLB_B8)" 3 "Crash_Intensitaet_2_(nur_D4_C7_Colorado_NF_PAG__Crash_im_MLB_B8)" 4 "Crash_Intensitaet_3_(alt_VW/AUDI__Stellgliedtest_MLB_B8)" 5 "Crash_Intensitaet_3_(alt_PAG)" 7 "Crash_Intensitaet_3" ;
VAL_ 64 AB_Lampe 0 "Aus" 1 "Ein" ;
VAL_ 64 AB_Deaktiviert 0 "aktiv" 1 "deaktiviert" ;
VAL_ 64 AB_VB_deaktiviert 0 "Beifahrerairbag_aktiv" 1 "Beifahrerairbag_deaktiviert" ;
VAL_ 64 AB_Systemfehler 0 "kein_Fehler" 1 "Airbag_Systemfehler" ;
VAL_ 64 AB_Diagnose 0 "nicht_in_Diagnose" 1 "in_Diagnose" ;
VAL_ 64 AB_Stellgliedtest 0 "nicht_im_Stellgliedtest" 1 "Airbag_im_Stellgliedtest" ;
VAL_ 64 AB_Erh_Auf_VB 0 "keine_Anzeige" 1 "Beifahrerairbag_deaktiviert" 2 "Beifahrerairbag_aktiviert" 3 "nicht_definiert" ;
VAL_ 64 AB_Gurtwarn_VF 0 "keine_Warnung" 1 "Gurtwarnung_ausloesen" ;
VAL_ 64 AB_Gurtwarn_VB 0 "keine_Warnung" 1 "Gurtwarnung_ausloesen" ;
VAL_ 64 AB_Anzeige_Fussg 0 "keine_FSG_Aktion_ausgeloest" 1 "Motorhaube_offen" 2 "Systemfehler" ;
VAL_ 64 AB_Texte_AKS 0 "keine_AKS_Ausloesung" 1 "AKS_ausgeloest" 2 "AKS_Systemfehler" ;
VAL_ 64 AB_PAO_Leuchte_Anf 0 "Leuchte_ausschalten" 1 "Leuchte_einschalten" ;
VAL_ 64 AB_MKB_gueltig 0 "Multikollisionsbremsung_nicht_freigeschaltet" 1 "Multikollisionsbremsung_freigeschaltet" ;
VAL_ 64 AB_MKB_Anforderung 0 "Multikollisionsbremsung_nicht_angefordert" 1 "Multikollisionsbremsung_angefordert" ;
VAL_ 64 AB_Versorgungsspannung 0 "plausibel" 1 "unplausibel" ;
VAL_ 64 AB_Deaktivierung_HV 0 "keine_Deaktivierung" 1 "Deaktivierung_1" 2 "Deaktivierung_2" 3 "Deaktivierung_3" 4 "Deaktivierung_4" 5 "Deaktivierung_5" 6 "Deaktivierung_6" 7 "Fehler" ;
VAL_ 64 AB_EDR_Trigger 0 "No_Event" 1 "Start_Event" 2 "NonDeployment_Event" 3 "Deployment_Event" ;
VAL_ 64 SC_Masterzeit 127 "Init" ;
VAL_ 1312 LoGeWa_Event_Kombiwarnung 0 "Init" 1 "Unfall" 2 "Traktionsverlust" 3 "Panne" 4 "Sichtbehinderung" 5 "Stauende" 6 "Aktiver_Eingriff_PreSense" 7 "Aktiver_Eingriff_ANB" 8 "Aktiver_Eingriff_Emergency_Brake" ;
VAL_ 1312 AB_Anforderung_eCall 0 "keine_Anforderung" 1 "Anforderung" ;
VAL_ 1312 AB_Anprall_Seite_Beifahrer 0 "kein_Anprall" 1 "Anprall_erkannt" ;
VAL_ 1312 AB_Anprall_Rollover 0 "kein_Anprall" 1 "Anprall_erkannt" ;
VAL_ 1312 AB_Anprall_FGS 0 "kein_Anprall" 1 "Anprall_erkannt" ;
VAL_ 1312 AB_Anprall_Front_Beifahrer 0 "kein_Anprall" 1 "Anprall_erkannt" ;
VAL_ 1312 AB_Anprall_Front_Fahrer 0 "kein_Anprall" 1 "Anprall_erkannt" ;
VAL_ 1312 AB_Anprall_Heck_Beifahrer 0 "kein_Anprall" 1 "Anprall_erkannt" ;
VAL_ 1312 AB_Anprall_Heck_Fahrer 0 "kein_Anprall" 1 "Anprall_erkannt" ;
VAL_ 1312 AB_Wickelklappung_Reihe2_MI 0 "nicht_verbaut" 1 "nicht_verfügbar (Fehler oder Init)" 2 "nicht_verriegelt" 3 "verriegelt" ;
VAL_ 1312 AB_Belegung_VB 0 "nicht_verfuegbar" 1 "Fehler" 2 "nicht_belegt" 3 "belegt" ;
VAL_ 1312 AB_Abschaltanf_SIH_BF 0 "Normalbetrieb" 1 "Abschaltung_angefordert" ;
VAL_ 1312 AB_Anprall_Seite_Fahrer 0 "kein_Anprall" 1 "Anprall_erkannt" ;
VAL_ 1312 SC_PAO_Schriftzug_Anf 0 "LED aus" 1 "LED an" 2 "LED blinken" 3 "reserviert" ;
VAL_ 1312 SC_PAO_ON_Anf 0 "LED aus" 1 "LED an" 2 "LED blinken" 3 "reserviert" ;
VAL_ 1312 SC_PAO_OFF_Anf 0 "LED aus" 1 "LED an" 2 "LED blinken" 3 "reserviert" ;
VAL_ 1312 AB_Crashschwere 0 "kein_Ereignis" 1 "Crashschwere_1" 2 "Crashschwere_2" 3 "Crashschwere_3" 4 "Crashschwere_4" 5 "Crashschwere_5" 6 "nicht_belegt" 7 "Fehler" ;
VAL_ 1312 AB_Anforderung_USM 0 "keine_Anforderung" 1 "Anforderung" ;
VAL_ 1312 AB_Gurtschloss_FA 0 "nicht_verbaut" 1 "nicht_verfügbar (Fehler oder Init)" 2 "nicht_gesteckt" 3 "gesteckt" ;
VAL_ 1312 AB_Gurtschloss_BF 0 "nicht_verbaut" 1 "nicht_verfügbar (Fehler oder Init)" 2 "nicht_gesteckt" 3 "gesteckt" ;
VAL_ 1312 AB_Gurtschloss_Reihe2_FA 0 "nicht_verbaut" 1 "nicht_verfügbar (Fehler oder Init)" 2 "nicht_gesteckt" 3 "gesteckt" ;
VAL_ 1312 AB_Gurtschloss_Reihe2_MI 0 "nicht_verbaut" 1 "nicht_verfügbar (Fehler oder Init)" 2 "nicht_gesteckt" 3 "gesteckt" ;
VAL_ 1312 AB_Gurtschloss_Reihe2_BF 0 "nicht_verbaut" 1 "nicht_verfügbar (Fehler oder Init)" 2 "nicht_gesteckt" 3 "gesteckt" ;
VAL_ 1312 AB_Gurtschloss_Reihe3_FA 0 "nicht_verbaut" 1 "nicht_verfügbar (Fehler oder Init)" 2 "nicht_gesteckt" 3 "gesteckt" ;
VAL_ 1312 AB_Gurtschloss_Reihe3_MI 0 "nicht_verbaut" 1 "nicht_verfügbar (Fehler oder Init)" 2 "nicht_gesteckt" 3 "gesteckt" ;
VAL_ 1312 AB_Gurtschloss_Reihe3_BF 0 "nicht_verbaut" 1 "nicht_verfügbar (Fehler oder Init)" 2 "nicht_gesteckt" 3 "gesteckt" ;
VAL_ 1312 AB_Sitzpos_Sens_FA 0 "nicht verfügbar" 1 "Fehler" 2 "Sitz nicht vorne" 3 "Sitz vorne" ;
VAL_ 1312 AB_Sitzpos_Sens_BF 0 "nicht verfügbar" 1 "Fehler" 2 "Sitz nicht vorne" 3 "Sitz vorne" ;
VAL_ 1312 AB_Wickelklappung_Reihe2_BF 0 "nicht_verbaut" 1 "nicht_verfügbar (Fehler oder Init)" 2 "nicht_verriegelt" 3 "verriegelt" ;
VAL_ 1312 AB_Wickelklappung_Reihe2_FA 0 "nicht_verbaut" 1 "nicht_verfügbar (Fehler oder Init)" 2 "nicht_verriegelt" 3 "verriegelt" ;
VAL_ 927 US_Fehler_VS 0 "kein_Fehler" 1 "Fehler" ;
VAL_ 927 US_Fehler_HS 0 "kein_Fehler" 1 "Fehler" ;
VAL_ 927 US_Verschmutzung_VS 0 "keine_Blindheit" 1 "Blindheit_erkannt" ;
VAL_ 927 US_Verschmutzung_HS 0 "keine_Blindheit" 1 "Blindheit_erkannt" ;
VAL_ 927 US_NichtVerfuegbarkeit_VS 0 "Abstandswert_verfuegbar" 1 "Abstandswert_nicht_verfuegbar" ;
VAL_ 927 US_NichtVerfuegbarkeit_HS 0 "Abstandswert_verfuegbar" 1 "Abstandswert_nicht_verfuegbar" ;
VAL_ 896 US_Sende_Modus 0 "keine_fuer_das_ACC_SG_relevanten_Abstandswerte_werden_gesendet" 1 "4K_ext_range__10_Signalwege_verfuegbar__4m" 2 "4K_norm_range__10_Signalwege_verfuegbar__2m" 3 "6K_ext_range__16_Signalwege_verfuegbar__4m" 4 "6K_norm_range__16_Signalwege_verfuegbar__2m" 5 "2K_ext_range__2_Signalwege_verfuegbar__4m" 6 "Modeumschaltung__ext_>_norm__oder__norm_>_ext" 7 "Blindheitspruefung" 8 "4K_ext_range__12_Signalwege_verfuegbar_4m" 9 "4K_norm_range__12_Signalwege_verfuegbar_2m" 10 "6K_ext_range__18_Signalwege_verfuegbar_4m" 11 "6K_norm_range__18_Signalwege_verfuegbar_2m" 15 "Fehler" ;
VAL_ 896 US_relevanter_Fehler 0 "kein_relevanter_Fehler" 1 "relevanter_Fehler" ;
VAL_ 896 US_relevante_Nichtverfuegbarkeit 0 "verfuegbar" 1 "nicht_verfuegbar" ;
VAL_ 896 US_Freisicht_nio 0 "Freisicht_iO" 1 "Freisicht_niO" ;
VAL_ 896 US_blindness_detected 0 "blindness_nicht_detektiert" 1 "blindness_detektiert" ;
VAL_ 896 US_Sende_Modus_hinten 0 "keine_fuer_das_ACC_SG_relevanten_Abstandswerte_werden_gesendet" 5 "2K_ext_range__2_Signalwege_verfuegbar__4m" 6 "Modeumschaltung__ext_>_norm__oder__norm_>_ext" 7 "Blindheitspruefung" 15 "Fehler" ;
VAL_ 896 APS_Master_Sendestatus 0 "Langsame_Zykluszeit_aktiv" 1 "Schnelle_Zykluszeit_aktiv" ;
VAL_ 896 US_Freie_Weglaenge_Front_Typ 0 "Maximaler_Messbereich" 1 "Hindernis_detektiert" ;
VAL_ 896 US_Freie_Weglaenge_Front 509 "freie_Weglaenge_groesser_5m" 510 "Init" 511 "Fehler" ;
VAL_ 870 BM_ZV_auf 0 "inaktiv" 1 "aktiv" ;
VAL_ 870 BM_ZV_zu 0 "inaktiv" 1 "aktiv" ;
VAL_ 870 BM_DWA_ein 0 "inaktiv" 1 "aktiv" ;
VAL_ 870 BM_DWA_Alarm 0 "inaktiv" 1 "aktiv" ;
VAL_ 870 BM_Crash 0 "inaktiv" 1 "aktiv" ;
VAL_ 870 BM_Panik 0 "inaktiv" 1 "aktiv" ;
VAL_ 870 BM_Not_Bremsung 0 "inaktiv" 1 "aktiv" ;
VAL_ 870 BM_GDO 0 "inaktiv" 1 "aktiv" ;
VAL_ 870 BM_Warnblinken 0 "inaktiv" 1 "aktiv" ;
VAL_ 870 BM_Taxi_Notalarm 0 "inaktiv" 1 "aktiv" ;
VAL_ 870 BM_Telematik 0 "inaktiv" 1 "aktiv" ;
VAL_ 870 BM_links 0 "inaktiv" 1 "aktiv" ;
VAL_ 870 BM_rechts 0 "inaktiv" 1 "aktiv" ;
VAL_ 870 Blinken_li_Fzg_Takt 0 "Blinker_links_ausgeschaltet" 1 "Blinker_links_eingeschaltet" ;
VAL_ 870 Blinken_re_Fzg_Takt 0 "Blinker_rechts_ausgeschaltet" 1 "Blinker_rechts_eingeschaltet" ;
VAL_ 870 Blinken_li_Kombi_Takt 0 "Blinkerkontrolllampe_links_ausgeschaltet" 1 "Blinkerkontrolllampe_links_eingeschaltet" ;
VAL_ 870 Blinken_re_Kombi_Takt 0 "Blinkerkontrolllampe_rechts_ausgeschaltet" 1 "Blinkerkontrolllampe_rechts_eingeschaltet" ;
VAL_ 870 BM_NBA_n_codiert_n_aktiv 0 "codiert_AND_kein_Fehler" 1 "nicht_codiert_OR_Fehler_erkannt" ;
VAL_ 870 BM_NBA_Status 0 "NBA_nicht_aktiv" 1 "BRL_Dunkelphase" 3 "BRL_Hellphase" ;
VAL_ 870 BM_WBT_Beleuchtung 0 "inaktiv" 1 "aktiv" ;
VAL_ 870 BM_HD_Oeffnung_angelernt 0 "keine_Quittierung" 1 "Quittierung" ;
VAL_ 870 BM_Autobahn 0 "inaktiv" 1 "aktiv" ;
VAL_ 870 BM_Rollenmodus_Blinken 0 "inaktiv" 1 "aktiv" ;
VAL_ 870 BM_Recas 0 "inaktiv" 1 "aktiv" ;
VAL_ 870 BM_Wischblinken 0 "inaktiv" 1 "aktiv" ;
VAL_ 870 BM_Telematik_Abbruchgrund 0 "Init" 1 "speed_out_of_range" 2 "defect" 3 "clamp_s_on" 4 "clamp_15_on" 5 "door_open" 6 "engine_hood_open" 7 "trunk_open" 8 "convertible_top_not_locked" 9 "horn_activated_by_user" 10 "Higher_Prioritiy_Function_active" 11 "Central_Lock_status_changed" 12 "Request_Dropped_by_Requester" 13 "Service_Duration_Expired" 14 "not_possible_due_to_coding" 15 "no_reason_or_unknown_timeout" ;
VAL_ 806 BV_Linie_01_Farbe 0 "keine_Linie" 1 "weiss" 2 "rot" 3 "gelb" 4 "sonstige" 5 "nicht_definiert" 6 "nicht_definiert" 7 "nicht_definiert" ;
VAL_ 806 BV_Linie_01_Liniennummer 0 "keine_Linie" ;
VAL_ 806 BV_Linie_01_Typ 0 "keine_Linie" 1 "durchgezogen" 2 "gestrichelt" 3 "Bordstein" 4 "Rasen" 5 "Bot-Dotts" 6 "sonstige" 7 "nicht_definiert" ;
VAL_ 807 BV_Linie_02_Farbe 0 "keine_Linie" 1 "weiss" 2 "rot" 3 "gelb" 4 "sonstige" 5 "nicht_definiert" 6 "nicht_definiert" 7 "nicht_definiert" ;
VAL_ 807 BV_Linie_02_Liniennummer 0 "keine_Linie" ;
VAL_ 807 BV_Linie_02_Typ 0 "keine_Linie" 1 "durchgezogen" 2 "gestrichelt" 3 "Bordstein" 4 "Rasen" 5 "Bot-Dotts" 6 "sonstige" 7 "nicht_definiert" ;
VAL_ 808 BV_Linie_03_Farbe 0 "keine_Linie" 1 "weiss" 2 "rot" 3 "gelb" 4 "sonstige" 5 "nicht_definiert" 6 "nicht_definiert" 7 "nicht_definiert" ;
VAL_ 808 BV_Linie_03_Liniennummer 0 "keine_Linie" ;
VAL_ 808 BV_Linie_03_Typ 0 "keine_Linie" 1 "durchgezogen" 2 "gestrichelt" 3 "Bordstein" 4 "Rasen" 5 "Bot-Dotts" 6 "sonstige" 7 "nicht_definiert" ;
VAL_ 809 BV_Linie_04_Farbe 0 "keine_Linie" 1 "weiss" 2 "rot" 3 "gelb" 4 "sonstige" 5 "nicht_definiert" 6 "nicht_definiert" 7 "nicht_definiert" ;
VAL_ 809 BV_Linie_04_Liniennummer 0 "keine_Linie" ;
VAL_ 809 BV_Linie_04_Typ 0 "keine_Linie" 1 "durchgezogen" 2 "gestrichelt" 3 "Bordstein" 4 "Rasen" 5 "Bot-Dotts" 6 "sonstige" 7 "nicht_definiert" ;
VAL_ 901 CHA_Ziel_FahrPr_AGA 0 "keine_Funktion" 1 "Programm_1" 2 "Programm_2" 3 "Programm_3" 4 "Programm_4" 5 "Programm_5" 6 "Programm_6" 7 "Programm_7" 8 "Programm_8" 9 "Programm_9" 10 "Programm_10" 11 "Programm_11" 12 "Programm_12" 13 "Programm_13" 14 "Programm_14" 15 "Programm_15" ;
VAL_ 901 CHA_Ziel_FahrPr_ESP 0 "keine_Funktion" 1 "Programm_1" 2 "Programm_2" 3 "Programm_3" 4 "Programm_4" 5 "Programm_5" 6 "Programm_6" 7 "Programm_7" 8 "Programm_8" 9 "Programm_9" 10 "Programm_10" 11 "Programm_11" 12 "Programm_12" 13 "Programm_13" 14 "Programm_14" 15 "Programm_15" ;
VAL_ 901 CHA_Ziel_FahrPr_Freilauf 0 "keine_Funktion" 1 "Programm_1" 2 "Programm_2" 3 "Programm_3" 4 "Programm_4" 5 "Programm_5" 6 "Programm_6" 7 "Programm_7" 8 "Programm_8" 9 "Programm_9" 10 "Programm_10" 11 "Programm_11" 12 "Programm_12" 13 "Programm_13" 14 "Programm_14" 15 "Programm_15" ;
VAL_ 901 CHA_Fahrer_Umschaltung 0 "keine_oder_automatische_Umschaltung" 1 "manuelle_Umschaltung" ;
VAL_ 901 CHA_Fahrer_Umschaltung_BMA 0 "keine_oder_autom_Umschaltung" 1 "manuelle_Umschaltung" ;
VAL_ 901 CHA_Ziel_FahrPr_MO 0 "keine_Funktion" 1 "Programm_1" 2 "Programm_2" 3 "Programm_3" 4 "Programm_4" 5 "Programm_5" 6 "Programm_6" 7 "Programm_7" 8 "Programm_8" 9 "Programm_9" 10 "Programm_10" 11 "Programm_11" 12 "Programm_12" 13 "Programm_13" 14 "Programm_14" 15 "Programm_15" ;
VAL_ 901 CHA_Ziel_FahrPr_GE 0 "keine_Funktion" 1 "Programm_1" 2 "Programm_2" 3 "Programm_3" 4 "Programm_4" 5 "Programm_5" 6 "Programm_6" 7 "Programm_7" 8 "Programm_8" 9 "Programm_9" 10 "Programm_10" 11 "Programm_11" 12 "Programm_12" 13 "Programm_13" 14 "Programm_14" 15 "Programm_15" ;
VAL_ 901 CHA_Ziel_FahrPr_ALR 0 "keine_Funktion" 1 "Programm_1" 2 "Programm_2" 3 "Programm_3" 4 "Programm_4" 5 "Programm_5" 6 "Programm_6" 7 "Programm_7" 8 "Programm_8" 9 "Programm_9" 10 "Programm_10" 11 "Programm_11" 12 "Programm_12" 13 "Programm_13" 14 "Programm_14" 15 "Programm_15" ;
VAL_ 901 CHA_Ziel_FahrPr_MO_BZS 0 "keine_Funktion" 1 "Programm_1" 2 "Programm_2" 3 "Programm_3" 4 "Programm_4" 5 "Programm_5" 6 "Programm_6" 7 "Programm_7" 8 "Programm_8" 9 "Programm_9" 10 "Programm_10" 11 "Programm_11" 12 "Programm_12" 13 "Programm_13" 14 "Programm_14" 15 "Programm_15" ;
VAL_ 901 CHA_Ziel_FahrPr_DR 0 "keine_Funktion" 1 "Programm_1" 2 "Programm_2" 3 "Programm_3" 4 "Programm_4" 5 "Programm_5" 6 "Programm_6" 7 "Programm_7" 8 "Programm_8" 9 "Programm_9" 10 "Programm_10" 11 "Programm_11" 12 "Programm_12" 13 "Programm_13" 14 "Programm_14" 15 "Programm_15" ;
VAL_ 901 CHA_Ziel_FahrPr_VAQ 0 "keine_Funktion" 1 "Programm_1" 2 "Programm_2" 3 "Programm_3" 4 "Programm_4" 5 "Programm_5" 6 "Programm_6" 7 "Programm_7" 8 "Programm_8" 9 "Programm_9" 10 "Programm_10" 11 "Programm_11" 12 "Programm_12" 13 "Programm_13" 14 "Programm_14" 15 "Programm_15" ;
VAL_ 901 CHA_Ziel_FahrPr_AFS 0 "keine_Funktion" 1 "Programm_1" 2 "Programm_2" 3 "Programm_3" 4 "Programm_4" 5 "Programm_5" 6 "Programm_6" 7 "Programm_7" 8 "Programm_8" 9 "Programm_9" 10 "Programm_10" 11 "Programm_11" 12 "Programm_12" 13 "Programm_13" 14 "Programm_14" 15 "Programm_15" ;
VAL_ 901 CHA_Ziel_FahrPr_RGS 0 "keine_Funktion" 1 "Programm_1" 2 "Programm_2" 3 "Programm_3" 4 "Programm_4" 5 "Programm_5" 6 "Programm_6" 7 "Programm_7" 8 "Programm_8" 9 "Programm_9" 10 "Programm_10" 11 "Programm_11" 12 "Programm_12" 13 "Programm_13" 14 "Programm_14" 15 "Programm_15" ;
VAL_ 901 CHA_Ziel_FahrPr_EPS 0 "keine_Funktion" 1 "Programm_1" 2 "Programm_2" 3 "Programm_3" 4 "Programm_4" 5 "Programm_5" 6 "Programm_6" 7 "Programm_7" 8 "Programm_8" 9 "Programm_9" 10 "Programm_10" 11 "Programm_11" 12 "Programm_12" 13 "Programm_13" 14 "Programm_14" 15 "Programm_15" ;
VAL_ 901 CHA_Ziel_FahrPr_ACC 0 "keine_Funktion" 1 "Programm_1" 2 "Programm_2" 3 "Programm_3" 4 "Programm_4" 5 "Programm_5" 6 "Programm_6" 7 "Programm_7" 8 "Programm_8" 9 "Programm_9" 10 "Programm_10" 11 "Programm_11" 12 "Programm_12" 13 "Programm_13" 14 "Programm_14" 15 "Programm_15" ;
VAL_ 901 CHA_Ziel_FahrPr_SAK 0 "keine_Funktion" 1 "Programm_1" 2 "Programm_2" 3 "Programm_3" 4 "Programm_4" 5 "Programm_5" 6 "Programm_6" 7 "Programm_7" 8 "Programm_8" 9 "Programm_9" 10 "Programm_10" 11 "Programm_11" 12 "Programm_12" 13 "Programm_13" 14 "Programm_14" 15 "Programm_15" ;
VAL_ 901 CHA_Ziel_FahrPr_MO_StSt 0 "keine_Funktion" 1 "Programm_1" 2 "Programm_2" 3 "Programm_3" 4 "Programm_4" 5 "Programm_5" 6 "Programm_6" 7 "Programm_7" 8 "Programm_8" 9 "Programm_9" 10 "Programm_10" 11 "Programm_11" 12 "Programm_12" 13 "Programm_13" 14 "Programm_14" 15 "Programm_15" ;
VAL_ 1000 CHA_Ziel_FahrPr_EBKV 0 "keine_Funktion" 1 "Programm_1" 2 "Programm_2" 3 "Programm_3" 4 "Programm_4" 5 "Programm_5" 6 "Programm_6" 7 "Programm_7" 8 "Programm_8" 9 "Programm_9" 10 "Programm_10" 11 "Programm_11" 12 "Programm_12" 13 "Programm_13" 14 "Programm_14" 15 "Programm_15" ;
VAL_ 1000 CHA_Ziel_FahrPr_IL 0 "keine_Funktion" 1 "Programm_1" 2 "Programm_2" 3 "Programm_3" 4 "Programm_4" 5 "Programm_5" 6 "Programm_6" 7 "Programm_7" 8 "Programm_8" 9 "Programm_9" 10 "Programm_10" 11 "Programm_11" 12 "Programm_12" 13 "Programm_13" 14 "Programm_14" 15 "Programm_15" ;
VAL_ 1000 CHA_Current_Mode 0 "keine_Funktion" 1 "Programm_1" 2 "Programm_2" 3 "Programm_3" 4 "Programm_4" 5 "Programm_5" 6 "Programm_6" 7 "Programm_7" 8 "Programm_8" 9 "Programm_9" 10 "Programm_10" 11 "Programm_11" 12 "Programm_12" 13 "Programm_13" 14 "Programm_14" 15 "Programm_15" ;
VAL_ 1000 CHA_Fahrer_Umschaltung 0 "keine_oder_automatische_Umschaltung" 1 "manuelle_Umschaltung" ;
VAL_ 1000 CHA_Ziel_FahrPr_QS 0 "keine_Funktion" 1 "Programm_1" 2 "Programm_2" 3 "Programm_3" 4 "Programm_4" 5 "Programm_5" 6 "Programm_6" 7 "Programm_7" 8 "Programm_8" 9 "Programm_9" 10 "Programm_10" 11 "Programm_11" 12 "Programm_12" 13 "Programm_13" 14 "Programm_14" 15 "Programm_15" ;
VAL_ 1000 CHA_Ziel_FahrPr_SCU 0 "keine_Funktion" 1 "Programm_1" 2 "Programm_2" 3 "Programm_3" 4 "Programm_4" 5 "Programm_5" 6 "Programm_6" 7 "Programm_7" 8 "Programm_8" 9 "Programm_9" 10 "Programm_10" 11 "Programm_11" 12 "Programm_12" 13 "Programm_13" 14 "Programm_14" 15 "Programm_15" ;
VAL_ 1000 CHA_Ziel_FahrPr_HAL 0 "keine_Funktion" 1 "Programm_1" 2 "Programm_2" 3 "Programm_3" 4 "Programm_4" 5 "Programm_5" 6 "Programm_6" 7 "Programm_7" 8 "Programm_8" 9 "Programm_9" 10 "Programm_10" 11 "Programm_11" 12 "Programm_12" 13 "Programm_13" 14 "Programm_14" 15 "Programm_15" ;
VAL_ 1000 CHA_Ziel_FahrPr_NR 0 "keine_Funktion" 1 "Programm_1" 2 "Programm_2" 3 "Programm_3" 4 "Programm_4" 5 "Programm_5" 6 "Programm_6" 7 "Programm_7" 8 "Programm_8" 9 "Programm_9" 10 "Programm_10" 11 "Programm_11" 12 "Programm_12" 13 "Programm_13" 14 "Programm_14" 15 "Programm_15" ;
VAL_ 1000 CHA_Ziel_FahrPr_AV 0 "keine_Funktion" 1 "Programm_1" 2 "Programm_2" 3 "Programm_3" 4 "Programm_4" 5 "Programm_5" 6 "Programm_6" 7 "Programm_7" 8 "Programm_8" 9 "Programm_9" 10 "Programm_10" 11 "Programm_11" 12 "Programm_12" 13 "Programm_13" 14 "Programm_14" 15 "Programm_15" ;
VAL_ 1000 CHA_Ziel_FahrPr_MXB 0 "keine_Funktion" 1 "Programm_1" 2 "Programm_2" 3 "Programm_3" 4 "Programm_4" 5 "Programm_5" 6 "Programm_6" 7 "Programm_7" 8 "Programm_8" 9 "Programm_9" 10 "Programm_10" 11 "Programm_11" 12 "Programm_12" 13 "Programm_13" 14 "Programm_14" 15 "Programm_15" ;
VAL_ 1000 CHA_Ziel_FahrPr_AFR 0 "keine_Funktion" 1 "Programm_1" 2 "Programm_2" 3 "Programm_3" 4 "Programm_4" 5 "Programm_5" 6 "Programm_6" 7 "Programm_7" 8 "Programm_8" 9 "Programm_9" 10 "Programm_10" 11 "Programm_11" 12 "Programm_12" 13 "Programm_13" 14 "Programm_14" 15 "Programm_15" ;
VAL_ 1000 CHA_Ziel_FahrPr_HDC 0 "keine_Funktion" 1 "Programm_1" 2 "Programm_2" 3 "Programm_3" 4 "Programm_4" 5 "Programm_5" 6 "Programm_6" 7 "Programm_7" 8 "Programm_8" 9 "Programm_9" 10 "Programm_10" 11 "Programm_11" 12 "Programm_12" 13 "Programm_13" 14 "Programm_14" 15 "Programm_15" ;
VAL_ 1000 CHA_Ziel_FahrPr_EAR 0 "keine_Funktion" 1 "Programm_1" 2 "Programm_2" 3 "Programm_3" 4 "Programm_4" 5 "Programm_5" 6 "Programm_6" 7 "Programm_7" 8 "Programm_8" 9 "Programm_9" 10 "Programm_10" 11 "Programm_11" 12 "Programm_12" 13 "Programm_13" 14 "Programm_14" 15 "Programm_15" ;
VAL_ 1000 CHA_Ziel_FahrPr_AEB 0 "keine_Funktion" 1 "Programm_1" 2 "Programm_2" 3 "Programm_3" 4 "Programm_4" 5 "Programm_5" 6 "Programm_6" 7 "Programm_7" 8 "Programm_8" 9 "Programm_9" 10 "Programm_10" 11 "Programm_11" 12 "Programm_12" 13 "Programm_13" 14 "Programm_14" 15 "Programm_15" ;
VAL_ 1000 CHA_Ziel_FahrPr_FCWO 0 "keine_Funktion" 1 "Programm_1" 2 "Programm_2" 3 "Programm_3" 4 "Programm_4" 5 "Programm_5" 6 "Programm_6" 7 "Programm_7" 8 "Programm_8" 9 "Programm_9" 10 "Programm_10" 11 "Programm_11" 12 "Programm_12" 13 "Programm_13" 14 "Programm_14" 15 "Programm_15" ;
VAL_ 1000 CHA_Ziel_FahrPr_FCWP 0 "keine_Funktion" 1 "Programm_1" 2 "Programm_2" 3 "Programm_3" 4 "Programm_4" 5 "Programm_5" 6 "Programm_6" 7 "Programm_7" 8 "Programm_8" 9 "Programm_9" 10 "Programm_10" 11 "Programm_11" 12 "Programm_12" 13 "Programm_13" 14 "Programm_14" 15 "Programm_15" ;
VAL_ 1714 DGN_Verlernzaehler 255 "ungültiger Zählerstand oder kein gültiger Fahrzyklus" ;
VAL_ 1714 KBI_Kilometerstand 1048574 "Init" 1048575 "Fehler" ;
VAL_ 1714 UH_Monat 0 "Init" 14 "reserviert" 15 "Fehler" ;
VAL_ 1714 UH_Tag 0 "Init" ;
VAL_ 1714 Vehicle_Driving_Cycle 0 "kein_Driving_Cycle_erkannt" 1 "Driving_Cycle_erkannt" ;
VAL_ 1714 Kombi_02_alt 0 "aktuell" 1 "veraltet" ;
VAL_ 1714 Uhrzeit_01_alt 0 "aktuell" 1 "veraltet" ;
VAL_ 1520 DI_KL_58xd 254 "Init" 255 "Fehler" ;
VAL_ 1520 DI_KL_58xs 126 "Init" 127 "Fehler" ;
VAL_ 1520 DI_KL_58xt 126 "Init" 127 "Fehler" ;
VAL_ 1520 BCM1_Stellgroesse_Kl_58s 125 "Nicht_verbaut" 126 "Init" 127 "Fehler" ;
VAL_ 1603 KBI_Einheit_Datum 0 "Tag/Monat/Jahr" 1 "Monat/Tag/Jahr" 2 "Jahr/Monat/Tag" 3 "reserviert" ;
VAL_ 1603 KBI_Einheit_Druck 0 "Druckangabe in bar" 1 "Druckangabe in psi" 2 "Druckangabe in kPa" 3 "tbd." ;
VAL_ 1603 KBI_Einheit_Streckenanz 0 "Kilometer" 1 "Meilen" ;
VAL_ 1603 KBI_MFA_v_Einheit_02 0 "kmh" 1 "mph" ;
VAL_ 1603 KBI_Einheit_Temp 0 "Grad Celsius °C" 1 "Grad Fahrenheit °F" ;
VAL_ 1603 KBI_Einheit_Uhrzeit 0 "24h" 1 " 12h AM/PM" ;
VAL_ 1603 KBI_Einheit_Verbrauch 0 "mpg UK" 1 "mpg USA" 2 "Liter/100km" 3 "km/Liter" ;
VAL_ 1603 KBI_Einheit_Volumen 0 "Liter" 1 "Gallonen UK" 2 "Gallonen USA" 3 "reserviert" ;
VAL_ 1603 KBI_Einheit_Verbrauch_elektr 0 "kWh_pro_100km" 1 "kWh_pro_100mls" 2 "km_pro_kWh" 3 "mls_pro_kWh" 4 "MPGe" ;
VAL_ 1603 KBI_Einheit_Verbrauch_Gas 0 "kg_per_100km" 1 "km_per_kg" 2 "m3_per_100km" 3 "km_per_m3" 4 "miles_per_lbs" 5 "miles_per_yard3" 6 "miles_per_kg" 7 "miles_per_m3" 8 "miles_per_gallon_equivalent_US" ;
VAL_ 1603 KBI_Einheit_Masse 0 "kg" 1 "lbs" 2 "reserviert" ;
VAL_ 260 EPB_QBit_Laengsbeschleunigung 0 "gültiger Wert" 1 "Ersatz-, Init- oder Fehlerwert" ;
VAL_ 260 EPB_QBit_Pedalweg_Kuppl 0 "gültiger Wert" 1 "Ersatz-, Init- oder Fehlerwert" ;
VAL_ 260 EPB_Freig_Verzoeg_Anf 0 "nicht freigegeben" 1 "freigegeben" ;
VAL_ 260 EPB_Pedalweg_Kuppl 0 "Init" 255 "Fehler" ;
VAL_ 260 EPB_DAA_Randbed_erf 0 "Randbed_nicht_erfuellt" 1 "Randbed_erfuellt" ;
VAL_ 260 EPB_Fehlerstatus 0 "kein_Fehler_in_EPB__AVH_darf_von_ESP_ausgefuehrt_werden" 1 "temporaer_nicht_verfuegbar_Grund_1" 2 "temporaer_nicht_verfuegbar_Grund_2" 3 "Fehler_in_EPB__AVH_darf_von_ESP_nicht_ausgefuehrt_werden" ;
VAL_ 260 EPB_Schalterposition 0 "keine Fahreranforderung" 1 "Fahreranforderung Öffnen" 2 "Fahreranforderung Schließen" 3 "Fehler" ;
VAL_ 260 EPB_QBit_Schalterpos 0 "gültiger Wert (volle Funktion)" 1 " Ersatz-, Init- oder Fehlerwert (Schalter ausser Funktion)" ;
VAL_ 260 EPB_Spannkraft 30 "Init" 31 "Fehler" ;
VAL_ 260 EPB_Status 0 "offen" 1 "Bremse_geschl_(Spannkraft_voll/reduziert)" 2 "Aktuator_im_Lauf" 3 "Fehler_oder_unbekannt" ;
VAL_ 257 ESP_QBit_Gierrate 0 "gueltiger_Wert" 1 "Ersatz_Init_oder_Fehlerwert" ;
VAL_ 257 ESP_QBit_Laengsbeschl 0 "gueltiger_Wert" 1 "Ersatz_Init_oder_Fehlerwert" ;
VAL_ 257 ESP_QBit_Querb 0 "gueltiger_Wert" 1 "Ersatz_Init_oder_Fehlerwert" ;
VAL_ 257 ESP_Stillstandsflag 0 "kein_Stillstand_erkannt" 1 "Stillstand_erkannt" ;
VAL_ 257 ESP_Querbeschleunigung 255 "Fehler" ;
VAL_ 257 ESP_Laengsbeschl 1022 "Signal_nicht_vorhanden" 1023 "Fehler" ;
VAL_ 257 ESC_Motorstartverzoegerung 0 "Startfreigabe" 1 "Anforderung_Startverzoegerung" ;
VAL_ 257 ESC_SeitenwindAssistent_Eingriff 0 "Kein_SWA_Eingriff_und_Init" 1 "SWA_Eingriff_aktiv" ;
VAL_ 257 ESP_Anschleppstart_Freigabe 0 "kein_Schleppstart_oder_NotSchleppstart_erlaubt" 1 "NotSchleppstart_erlaubt" 2 "Schleppstart_und_NotSchleppStart_erlaubt" ;
VAL_ 257 ESP_QBit_Anf_Vert_Wank 0 "gueltiger_Wert" 1 "Ersatz_Init_oder_Fehlerwert" ;
VAL_ 257 ESP_Gierrate 16383 "Fehler" ;
VAL_ 257 ESP_VZ_Gierrate 0 "positiv" 1 "negativ" ;
VAL_ 257 ESP_Notbremsanzeige 0 "keine_Notbremsung_erkannt" 1 "Notbremsung_erkannt" ;
VAL_ 257 ESP_SpannungsAnf 0 "keine_Anforderung" 1 "Anforderung_Spannungswert_1" ;
VAL_ 257 ESP_PLA_Abbruch 0 "Init" 1 "Geschwindigkeitsueberschreitung" 2 "Falscher_PLA_Status" 3 "Deaktivierung_durch_Abbruch_Lenkung" 4 "PLA_Bremsanforderung_nach_Stillstand" 5 "Abbruch_durch_Kl15_aus" 6 "Abbruch_durch_FT_offen" ;
VAL_ 257 ESP_Status_ESP_PLA 0 "ESP_PLA_deaktiv" 1 "ESP_PLA_Init" 2 "ESP_PLA_Fehler" 4 "ESP_PLA_aktivierbar" 6 "ESP_PLA_Bremse_aktiv" 8 "ESP_PLA_funktionsbereit" 9 "ESP_PLA_Neustart" 10 "ESP_PLA_Abbruch" ;
